VERSION ""
BS_:
BU_:

BO_ 881 RCM_dtcMatrix: 8 ETH
 SG_ RCM_dtcIndex M: 0|8@1+ (1,0) [0|0] "" X
 SG_ RCM_d000_comFault1 m0: 8|2@1+ (1,0) [0|0] "" X
 SG_ RCM_d001_vBatRange m0: 10|2@1+ (1,0) [0|0] "" X
 SG_ RCM_d002_vinMismatch m0: 12|2@1+ (1,0) [0|0] "" X
 SG_ RCM_d003_swVersionMismatch m0: 14|2@1+ (1,0) [0|0] "" X
 SG_ RCM_d004_idleMode m0: 16|2@1+ (1,0) [0|0] "" X
 SG_ RCM_d005_internalHard m0: 18|2@1+ (1,0) [0|0] "" X
 SG_ RCM_d006_crashAlgoDisabled m0: 20|2@1+ (1,0) [0|0] "" X
 SG_ RCM_d007_eolProgMismatch m0: 22|2@1+ (1,0) [0|0] "" X
 SG_ RCM_d008_crcErrorExternal m0: 24|2@1+ (1,0) [0|0] "" X
 SG_ RCM_d009_cfgFault m0: 26|2@1+ (1,0) [0|0] "" X
 SG_ RCM_d010_crashCalPNMissing m0: 28|2@1+ (1,0) [0|0] "" X
 SG_ RCM_d011_vdsFieldCalibFailed m0: 30|2@1+ (1,0) [0|0] "" X
 SG_ RCM_d012_vdsChannelSigMonTmp m0: 32|2@1+ (1,0) [0|0] "" X
 SG_ RCM_d013_vdsFieldCalibNotDone m0: 34|2@1+ (1,0) [0|0] "" X
 SG_ RCM_d014_vdsChannelSigMonPerm m0: 36|2@1+ (1,0) [0|0] "" X
 SG_ RCM_d015_vdsSensorMonitorTemp m0: 38|2@1+ (1,0) [0|0] "" X
 SG_ RCM_d016_comCANInitFailure m0: 40|2@1+ (1,0) [0|0] "" X
 SG_ RCM_d017_comGTWCarConfig m0: 42|2@1+ (1,0) [0|0] "" X
 SG_ RCM_d018_vinEmptyError m0: 44|2@1+ (1,0) [0|0] "" X
 SG_ RCM_d019_comESPC m0: 46|2@1+ (1,0) [0|0] "" X
 SG_ RCM_d020_comESP135 m0: 48|2@1+ (1,0) [0|0] "" X
 SG_ RCM_d021_comEPBStatus m0: 50|2@1+ (1,0) [0|0] "" X
 SG_ RCM_d022_comBCS2RStatus m0: 52|2@1+ (1,0) [0|0] "" X
 SG_ RCM_d023_comBCS2LStatus m0: 54|2@1+ (1,0) [0|0] "" X
 SG_ RCM_d024_comBCS2CStatus m0: 56|2@1+ (1,0) [0|0] "" X
 SG_ RCM_d025_comTPMSStatus m0: 58|2@1+ (1,0) [0|0] "" X
 SG_ RCM_d026_airbagWarnMismatch m0: 60|2@1+ (1,0) [0|0] "" X
 SG_ RCM_d027_ocsFailure m0: 62|2@1+ (1,0) [0|0] "" X
 SG_ RCM_d028_comGTWACS m1: 8|2@1+ (1,0) [0|0] "" X
 SG_ RCM_d029_comChassisBusOff m1: 10|2@1+ (1,0) [0|0] "" X
 SG_ RCM_d030_comStwAngle m1: 12|2@1+ (1,0) [0|0] "" X
 SG_ RCM_d031_comESP145 m1: 14|2@1+ (1,0) [0|0] "" X
 SG_ RCM_d032_comDITorque2 m1: 16|2@1+ (1,0) [0|0] "" X
 SG_ RCM_d033_comDITorque1 m1: 18|2@1+ (1,0) [0|0] "" X
 SG_ RCM_d034_comESPB m1: 20|2@1+ (1,0) [0|0] "" X
 SG_ RCM_d035_comGTWOdo m1: 22|2@1+ (1,0) [0|0] "" X
 SG_ RCM_d036_comBusOff m1: 24|2@1+ (1,0) [0|0] "" X
 SG_ RCM_d037_comMissingVehConfg m1: 26|2@1+ (1,0) [0|0] "" X
 SG_ RCM_d038_seatBackSw2ndRowLeft m1: 28|2@1+ (1,0) [0|0] "" X
 SG_ RCM_d039_pretenLapFrontRight m1: 30|2@1+ (1,0) [0|0] "" X
 SG_ RCM_d040_pretenLapFrontLeft m1: 32|2@1+ (1,0) [0|0] "" X
 SG_ RCM_d041_pretenShldFrontRight m1: 34|2@1+ (1,0) [0|0] "" X
 SG_ RCM_d042_pretenShldrFrontLeft m1: 36|2@1+ (1,0) [0|0] "" X
 SG_ RCM_d043_passABLampOnHardWire m1: 38|2@1+ (1,0) [0|0] "" X
 SG_ RCM_d044_crashDetected m1: 40|2@1+ (1,0) [0|0] "" X
 SG_ RCM_d045_crashOutSignal m1: 42|2@1+ (1,0) [0|0] "" X
 SG_ RCM_d046_passengerActiveVent m1: 44|2@1+ (1,0) [0|0] "" X
 SG_ RCM_d047_kneeABFrontPassenger m1: 46|2@1+ (1,0) [0|0] "" X
 SG_ RCM_d048_pressureFrontRtDoor m1: 48|2@1+ (1,0) [0|0] "" X
 SG_ RCM_d049_pressureFrontLftDoor m1: 50|2@1+ (1,0) [0|0] "" X
 SG_ RCM_d050_eepromDataLocked m1: 52|2@1+ (1,0) [0|0] "" X
 SG_ RCM_d051_hoodActuatorLeft m1: 54|2@1+ (1,0) [0|0] "" X
 SG_ RCM_d052_pretenMid2ndRow m1: 56|2@1+ (1,0) [0|0] "" X
 SG_ RCM_d053_sbsw2ndRowRight m1: 58|2@1+ (1,0) [0|0] "" X
 SG_ RCM_d054_padLampHardWire m1: 60|2@1+ (1,0) [0|0] "" X
 SG_ RCM_d055_passResOccupancySw m1: 62|2@1+ (1,0) [0|0] "" X
 SG_ RCM_d056_stpsDriver m2: 8|2@1+ (1,0) [0|0] "" X
 SG_ RCM_d057_pasDPillarLeftYAxis m2: 10|2@1+ (1,0) [0|0] "" X
 SG_ RCM_d058_pasDPillarLeftXAxis m2: 12|2@1+ (1,0) [0|0] "" X
 SG_ RCM_d059_pasDPillarRight m2: 14|2@1+ (1,0) [0|0] "" X
 SG_ RCM_d060_pasCPillarRight m2: 16|2@1+ (1,0) [0|0] "" X
 SG_ RCM_d061_pasBPillarRight m2: 18|2@1+ (1,0) [0|0] "" X
 SG_ RCM_d062_ufsRightSide m2: 20|2@1+ (1,0) [0|0] "" X
 SG_ RCM_d063_pasCPillarLeft m2: 22|2@1+ (1,0) [0|0] "" X
 SG_ RCM_d064_pasBPillarLeft m2: 24|2@1+ (1,0) [0|0] "" X
 SG_ RCM_d065_ufsLeftSide m2: 26|2@1+ (1,0) [0|0] "" X
 SG_ RCM_d066_loadLimiterRightSide m2: 28|2@1+ (1,0) [0|0] "" X
 SG_ RCM_d067_loadLimiterLeftSide m2: 30|2@1+ (1,0) [0|0] "" X
 SG_ RCM_d068_curAB3rdRowRight m2: 32|2@1+ (1,0) [0|0] "" X
 SG_ RCM_d069_curAB2ndRowRight m2: 34|2@1+ (1,0) [0|0] "" X
 SG_ RCM_d070_curAB2ndRowLeft m2: 36|2@1+ (1,0) [0|0] "" X
 SG_ RCM_d071_preten2ndRowRight m2: 38|2@1+ (1,0) [0|0] "" X
 SG_ RCM_d072_curAB3rdRowLeft m2: 40|2@1+ (1,0) [0|0] "" X
 SG_ RCM_d073_preten2ndRowLeft m2: 42|2@1+ (1,0) [0|0] "" X
 SG_ RCM_d074_siAB2ndRowRight m2: 44|2@1+ (1,0) [0|0] "" X
 SG_ RCM_d075_siAB2ndRowLeft m2: 46|2@1+ (1,0) [0|0] "" X
 SG_ RCM_d076_hardwarCodingPin3 m2: 48|2@1+ (1,0) [0|0] "" X
 SG_ RCM_d077_hardwareCodingPin2 m2: 50|2@1+ (1,0) [0|0] "" X
 SG_ RCM_d078_hardwareCodingPin1 m2: 52|2@1+ (1,0) [0|0] "" X
 SG_ RCM_d079_buckleRightSide m2: 54|2@1+ (1,0) [0|0] "" X
 SG_ RCM_d080_buckleLeftSide m2: 56|2@1+ (1,0) [0|0] "" X
 SG_ RCM_d081_curAB1stRowRight m2: 58|2@1+ (1,0) [0|0] "" X
 SG_ RCM_d082_siAB1stRowRight m2: 60|2@1+ (1,0) [0|0] "" X
 SG_ RCM_d083_curAB1stRowLeft m2: 62|2@1+ (1,0) [0|0] "" X
 SG_ RCM_d084_siAB1stRowLeft m3: 8|2@1+ (1,0) [0|0] "" X
 SG_ RCM_d085_pabStage2 m3: 10|2@1+ (1,0) [0|0] "" X
 SG_ RCM_d086_pabStage1 m3: 12|2@1+ (1,0) [0|0] "" X
 SG_ RCM_d087_hvDisconnect m3: 14|2@1+ (1,0) [0|0] "" X
 SG_ RCM_d088_kneeABDriver m3: 16|2@1+ (1,0) [0|0] "" X
 SG_ RCM_d089_dabStage2 m3: 18|2@1+ (1,0) [0|0] "" X
 SG_ RCM_d090_dabStage1 m3: 20|2@1+ (1,0) [0|0] "" X
 SG_ RCM_d091_comGTWCarState m3: 22|2@1+ (1,0) [0|0] "" X
 SG_ RCM_d092_driverOrientation m3: 24|2@1+ (1,0) [0|0] "" X
 SG_ RCM_d093_scmUnavailable m3: 26|2@1+ (1,0) [0|0] "" X
 SG_ RCM_d094_comDasControl m3: 28|2@1+ (1,0) [0|0] "" X
 SG_ RCM_d095_comDasIDF m3: 30|2@1+ (1,0) [0|0] "" X
 SG_ RCM_d096_comDasStatus m3: 32|2@1+ (1,0) [0|0] "" X
 SG_ RCM_d097_comDIState m3: 34|2@1+ (1,0) [0|0] "" X
 SG_ RCM_d098_comDIState2 m3: 36|2@1+ (1,0) [0|0] "" X

BO_ 849 RCM_info: 8 ETH
 SG_ RCM_infoIndex M: 0|8@1+ (1,0) [0|0] "" X
 SG_ RCM_infoBuildType m10: 8|8@1+ (1,0) [0|0] "" X
 SG_ RCM_infoComponentID m10: 48|16@1+ (1,0) [0|0] "" X
 SG_ RCM_infoPcbaID m11: 16|8@1+ (1,0) [0|0] "" X
 SG_ RCM_infoAssemblyID m11: 24|8@1+ (1,0) [0|0] "" X
 SG_ RCM_infoUsageID m11: 32|16@1+ (1,0) [0|0] "" X
 SG_ RCM_infoBootUdsProtoVersion m20: 8|8@1+ (1,0) [0|0] "" X
 SG_ RCM_infoBootloaderCRC m20: 32|32@1+ (1,0) [0|0] "" X
 SG_ RCM_infoApplicationCRC m13: 32|32@1+ (1,0) [0|0] "" X
 SG_ RCM_infoVariantCRC m22: 32|32@1+ (1,0) [0|0] "" X

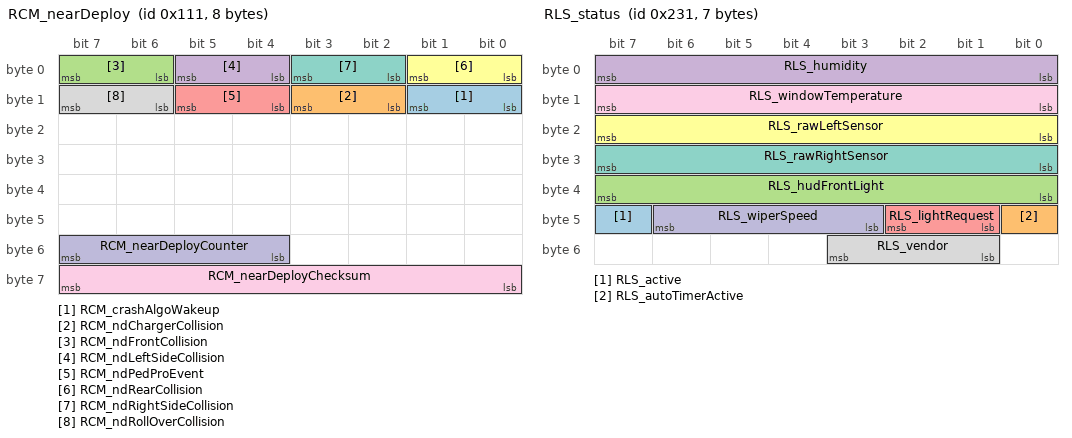
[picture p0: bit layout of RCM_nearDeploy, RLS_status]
BO_ 273 RCM_nearDeploy: 8 ETH
 SG_ RCM_crashAlgoWakeup: 8|2@1+ (1,0) [0|0] "" X
 SG_ RCM_ndChargerCollision: 10|2@1+ (1,0) [0|0] "" X
 SG_ RCM_ndFrontCollision: 6|2@1+ (1,0) [0|0] "" X
 SG_ RCM_ndLeftSideCollision: 4|2@1+ (1,0) [0|0] "" X
 SG_ RCM_ndPedProEvent: 12|2@1+ (1,0) [0|0] "" X
 SG_ RCM_ndRearCollision: 0|2@1+ (1,0) [0|0] "" X
 SG_ RCM_ndRightSideCollision: 2|2@1+ (1,0) [0|0] "" X
 SG_ RCM_ndRollOverCollision: 14|2@1+ (1,0) [0|0] "" X
 SG_ RCM_nearDeployChecksum: 56|8@1+ (1,0) [0|0] "" X
 SG_ RCM_nearDeployCounter: 52|4@1+ (1,0) [0|0] "" X

BO_ 535 RCM_status: 8 ETH
 SG_ RCM_airbagCutoffSwStatus: 34|2@1+ (1,0) [0|0] "" X
 SG_ RCM_armStatus: 4|2@1+ (1,0) [0|0] "" X
 SG_ RCM_buckle2ndRowStatus: 48|3@1+ (1,0) [0|0] "" X
 SG_ RCM_buckleDriverStatus: 14|2@1+ (1,0) [0|0] "" X
 SG_ RCM_bucklePassengerStatus: 10|2@1+ (1,0) [0|0] "" X
 SG_ RCM_chimeState1stRow: 22|2@1+ (1,0) [0|0] "" X
 SG_ RCM_driverOrientationInitStatus: 0|3@1+ (1,0) [0|0] "" X
 SG_ RCM_edr1State: 46|2@1+ (1,0) [0|0] "" X
 SG_ RCM_edr2State: 44|2@1+ (1,0) [0|0] "" X
 SG_ RCM_hwConfigPin56: 30|2@1+ (1,0) [0|0] "" X
 SG_ RCM_hwConfigPin57: 28|2@1+ (1,0) [0|0] "" X
 SG_ RCM_hwConfigPin58: 26|2@1+ (1,0) [0|0] "" X
 SG_ RCM_passAirbagRequest: 20|2@1+ (1,0) [0|0] "" X
 SG_ RCM_passOccupantStatus: 32|2@1+ (1,0) [0|0] "" X
 SG_ RCM_privateCANStatus: 36|2@1+ (1,0) [0|0] "" X
 SG_ RCM_publicCANStatus: 38|2@1+ (1,0) [0|0] "" X
 SG_ RCM_seatTrackPositionDrvr: 18|2@1+ (1,0) [0|0] "" X
 SG_ RCM_statusChecksum: 56|8@1+ (1,0) [0|0] "" X
 SG_ RCM_statusCounter: 52|4@1+ (1,0) [0|0] "" X
 SG_ RCM_tellTaleDriverState: 12|2@1+ (1,0) [0|0] "" X
 SG_ RCM_tellTalePassengerState: 8|2@1+ (1,0) [0|0] "" X
 SG_ RCM_vinLearnFlag: 24|2@1+ (1,0) [0|0] "" X
 SG_ RCM_warningIndicatorState: 6|2@1+ (1,0) [0|0] "" X

BO_ 1618 RCM_udsResponse: 8 ETH
 SG_ RCM_udsResponseData: 0|54@0+ (1024,0) [0|0] "" X

BO_ 561 RLS_status: 7 ETH
 SG_ RLS_active: 47|1@1+ (1,0) [0|0] "" X
 SG_ RLS_autoTimerActive: 40|1@1+ (1,0) [0|0] "" X
 SG_ RLS_hudFrontLight: 32|8@1+ (1,0) [0|0] "INTEGRAL" X
 SG_ RLS_humidity: 0|8@1+ (0.5,0) [0|0] "%" X
 SG_ RLS_lightRequest: 41|2@1+ (1,0) [0|0] "" X
 SG_ RLS_rawLeftSensor: 16|8@1+ (4.01575,0) [0|0] "W/m2" X
 SG_ RLS_rawRightSensor: 24|8@1+ (4.01575,0) [0|0] "W/m2" X
 SG_ RLS_vendor: 49|3@1+ (1,0) [0|0] "" X
 SG_ RLS_windowTemperature: 8|8@1+ (0.5,-40) [0|0] "C" X
 SG_ RLS_wiperSpeed: 43|4@1+ (1,0) [0|0] "" X

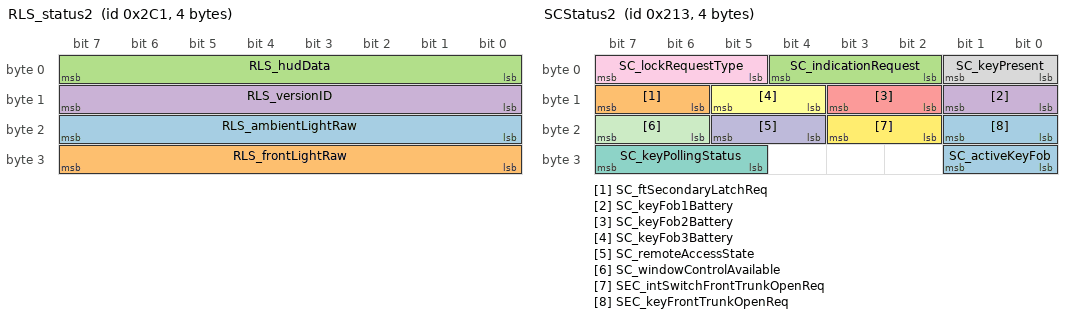
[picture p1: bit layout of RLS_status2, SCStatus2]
BO_ 705 RLS_status2: 4 ETH
 SG_ RLS_ambientLightRaw: 16|8@1+ (100,0) [0|0] "INTEGRAL" X
 SG_ RLS_frontLightRaw: 24|8@1+ (1,0) [0|0] "" X
 SG_ RLS_hudData: 0|8@1+ (1,0) [0|0] "INTEGRAL" X
 SG_ RLS_versionID: 8|8@1+ (1,0) [0|0] "INTEGRAL" X

BO_ 1944 SCCM_udsResponse: 8 ETH
 SG_ SCCM_udsResponseData: 0|54@0+ (1024,0) [0|0] "" X

BO_ 515 SCStatus: 8 ETH
 SG_ SC_alarmStatus: 0|4@1+ (1,0) [0|0] "" X
 SG_ SC_driverFrontDoorOpenStatus: 36|2@1+ (1,0) [0|0] "" X
 SG_ SC_driverRearDoorOpenStatus: 38|2@1+ (1,0) [0|0] "" X
 SG_ SC_frontTrunkStatus: 16|2@1+ (1,0) [0|0] "" X
 SG_ SC_hazardSwitchStatus: 14|2@1+ (1,0) [0|0] "" X
 SG_ SC_ignitionStatus: 52|4@1+ (1,0) [0|0] "" X
 SG_ SC_keyChallengeType: 22|2@1+ (1,0) [0|0] "" X
 SG_ SC_keyFobAuthenticated: 30|2@1+ (1,0) [0|0] "" X
 SG_ SC_passFrontDoorOpenStatus: 32|2@1+ (1,0) [0|0] "" X
 SG_ SC_passRearDoorOpenStatus: 34|2@1+ (1,0) [0|0] "" X
 SG_ SC_rearTrunkStatus: 18|2@1+ (1,0) [0|0] "" X
 SG_ SC_rkeUnlockRequiredForStart: 21|1@1+ (1,0) [0|0] "" X
 SG_ SC_scClusterMessage: 48|10@0+ (1,0) [0|0] "" X
 SG_ SC_scStatus: 4|4@1+ (1,0) [0|0] "" X
 SG_ SC_vehicleLockStatus: 8|3@1+ (1,0) [0|0] "" X
 SG_ SC_vehicleStatus: 11|3@1+ (1,0) [0|0] "" X
 SG_ SEC_accessViaDeadFob: 46|2@1+ (1,0) [0|0] "" X
 SG_ SEC_chargePortRequest: 44|2@1+ (1,0) [0|0] "" X
 SG_ SEC_driverPresent: 50|2@1+ (1,0) [0|0] "" X
 SG_ SEC_dtcPresent: 40|1@1+ (1,0) [0|0] "" X
 SG_ SEC_keyLocation: 24|4@1+ (1,0) [0|0] "" X
 SG_ SEC_keyPollSuccess: 28|2@1+ (1,0) [0|0] "" X
 SG_ SEC_lockRejected: 20|1@1+ (1,0) [0|0] "" X
 SG_ SEC_windowRequest: 42|2@1+ (1,0) [0|0] "" X

BO_ 531 SCStatus2: 4 ETH
 SG_ SC_activeKeyFob: 24|2@1+ (1,0) [0|0] "" X
 SG_ SC_ftSecondaryLatchReq: 14|2@1+ (1,0) [0|0] "" X
 SG_ SC_indicationRequest: 2|3@1+ (1,0) [0|0] "" X
 SG_ SC_keyFob1Battery: 8|2@1+ (1,0) [0|0] "" X
 SG_ SC_keyFob2Battery: 10|2@1+ (1,0) [0|0] "" X
 SG_ SC_keyFob3Battery: 12|2@1+ (1,0) [0|0] "" X
 SG_ SC_keyPollingStatus: 29|3@1+ (1,0) [0|0] "" X
 SG_ SC_keyPresent: 0|2@1+ (1,0) [0|0] "" X
 SG_ SC_lockRequestType: 5|3@1+ (1,0) [0|0] "" X
 SG_ SC_remoteAccessState: 20|2@1+ (1,0) [0|0] "" X
 SG_ SC_windowControlAvailable: 22|2@1+ (1,0) [0|0] "" X
 SG_ SEC_intSwitchFrontTrunkOpenReq: 18|2@1+ (1,0) [0|0] "" X
 SG_ SEC_keyFrontTrunkOpenReq: 16|2@1+ (1,0) [0|0] "" X

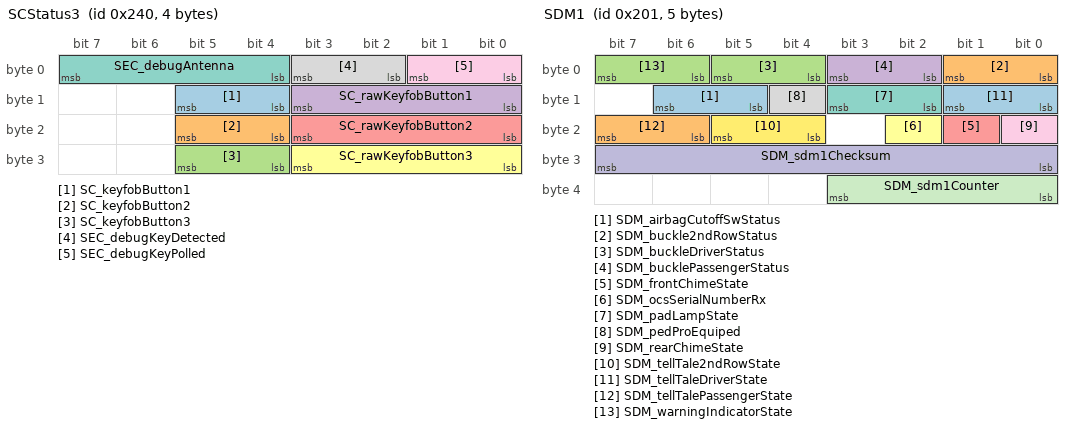
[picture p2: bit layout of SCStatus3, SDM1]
BO_ 576 SCStatus3: 4 ETH
 SG_ SC_keyfobButton1: 12|2@1+ (1,0) [0|0] "" X
 SG_ SC_keyfobButton2: 20|2@1+ (1,0) [0|0] "" X
 SG_ SC_keyfobButton3: 28|2@1+ (1,0) [0|0] "" X
 SG_ SC_rawKeyfobButton1: 8|4@1+ (1,0) [0|0] "" X
 SG_ SC_rawKeyfobButton2: 16|4@1+ (1,0) [0|0] "" X
 SG_ SC_rawKeyfobButton3: 24|4@1+ (1,0) [0|0] "" X
 SG_ SEC_debugAntenna: 4|4@1+ (1,0) [0|0] "" X
 SG_ SEC_debugKeyDetected: 2|2@1+ (1,0) [0|0] "" X
 SG_ SEC_debugKeyPolled: 0|2@1+ (1,0) [0|0] "" X

BO_ 513 SDM1: 5 ETH
 SG_ SDM_airbagCutoffSwStatus: 13|2@1+ (1,0) [0|0] "" X
 SG_ SDM_buckle2ndRowStatus: 0|2@1+ (1,0) [0|0] "" X
 SG_ SDM_buckleDriverStatus: 4|2@1+ (1,0) [0|0] "" X
 SG_ SDM_bucklePassengerStatus: 2|2@1+ (1,0) [0|0] "" X
 SG_ SDM_frontChimeState: 17|1@1+ (1,0) [0|0] "" X
 SG_ SDM_ocsSerialNumberRx: 18|1@1+ (1,0) [0|0] "" X
 SG_ SDM_padLampState: 10|2@1+ (1,0) [0|0] "" X
 SG_ SDM_pedProEquiped: 12|1@1+ (1,0) [0|0] "" X
 SG_ SDM_rearChimeState: 16|1@1+ (1,0) [0|0] "" X
 SG_ SDM_sdm1Checksum: 24|8@1+ (1,0) [0|0] "" X
 SG_ SDM_sdm1Counter: 32|4@1+ (1,0) [0|0] "" X
 SG_ SDM_tellTale2ndRowState: 20|2@1+ (1,0) [0|0] "" X
 SG_ SDM_tellTaleDriverState: 8|2@1+ (1,0) [0|0] "" X
 SG_ SDM_tellTalePassengerState: 22|2@1+ (1,0) [0|0] "" X
 SG_ SDM_warningIndicatorState: 6|2@1+ (1,0) [0|0] "" X

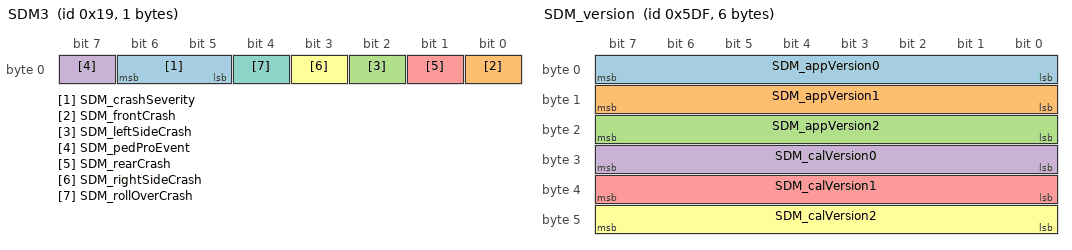
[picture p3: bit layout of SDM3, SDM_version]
BO_ 25 SDM3: 1 ETH
 SG_ SDM_crashSeverity: 5|2@1+ (1,0) [0|0] "" X
 SG_ SDM_frontCrash: 0|1@1+ (1,0) [0|0] "" X
 SG_ SDM_leftSideCrash: 2|1@1+ (1,0) [0|0] "" X
 SG_ SDM_pedProEvent: 7|1@1+ (1,0) [0|0] "" X
 SG_ SDM_rearCrash: 1|1@1+ (1,0) [0|0] "" X
 SG_ SDM_rightSideCrash: 3|1@1+ (1,0) [0|0] "" X
 SG_ SDM_rollOverCrash: 4|1@1+ (1,0) [0|0] "" X

BO_ 1617 SDM_udsResponse: 8 ETH
 SG_ SDM_udsResponseData: 0|54@0+ (1024,0) [0|0] "" X

BO_ 1503 SDM_version: 6 ETH
 SG_ SDM_appVersion0: 0|8@1+ (1,0) [0|0] "" X
 SG_ SDM_appVersion1: 8|8@1+ (1,0) [0|0] "" X
 SG_ SDM_appVersion2: 16|8@1+ (1,0) [0|0] "" X
 SG_ SDM_calVersion0: 24|8@1+ (1,0) [0|0] "" X
 SG_ SDM_calVersion1: 32|8@1+ (1,0) [0|0] "" X
 SG_ SDM_calVersion2: 40|8@1+ (1,0) [0|0] "" X

BO_ 547 SEC_doorCommandPartial: 1 ETH
 SG_ SC_handleFLCommand: 6|2@1+ (1,0) [0|0] "" X

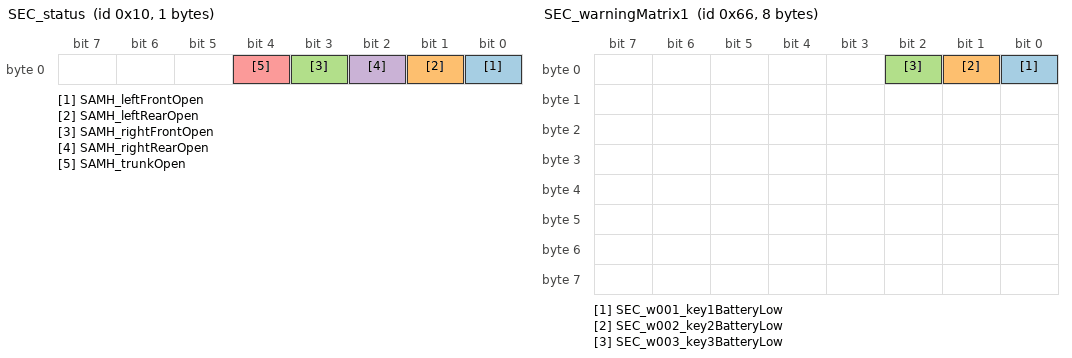
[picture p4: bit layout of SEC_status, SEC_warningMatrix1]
BO_ 16 SEC_status: 1 ETH
 SG_ SAMH_leftFrontOpen: 0|1@1+ (1,0) [0|0] "" X
 SG_ SAMH_leftRearOpen: 1|1@1+ (1,0) [0|0] "" X
 SG_ SAMH_rightFrontOpen: 3|1@1+ (1,0) [0|0] "" X
 SG_ SAMH_rightRearOpen: 2|1@1+ (1,0) [0|0] "" X
 SG_ SAMH_trunkOpen: 4|1@1+ (1,0) [0|0] "" X

BO_ 1683 SEC_udsResponse: 8 ETH
 SG_ SEC_udsResponseData: 0|54@0+ (1024,0) [0|0] "" X

BO_ 1315 SEC_version: 8 ETH
 SG_ SEC_componentBranchOrigin: 40|8@1+ (1,0) [0|0] "" X
 SG_ SEC_componentHardwareRevision: 56|8@1+ (1,0) [0|0] "" X
 SG_ SEC_componentMajorVersion: 32|8@1+ (1,0) [0|0] "" X
 SG_ SEC_componentMaturity: 48|8@1+ (1,0) [0|0] "" X
 SG_ SEC_componentSvn: 8|24@0+ (1,0) [0|0] "" X
 SG_ SEC_platformType: 0|8@1+ (1,0) [0|0] "" X

BO_ 102 SEC_warningMatrix1: 8 ETH
 SG_ SEC_w001_key1BatteryLow: 0|1@1+ (1,0) [0|0] "" X
 SG_ SEC_w002_key2BatteryLow: 1|1@1+ (1,0) [0|0] "" X
 SG_ SEC_w003_key3BatteryLow: 2|1@1+ (1,0) [0|0] "" X

BO_ 1317 SNSCLL1_info: 8 ETH
 SG_ SNSCLL1_infoIndex M: 0|8@1+ (1,0) [0|0] "" X
 SG_ SNSCLL1_infoBuildType m10: 8|8@1+ (1,0) [0|0] "" X
 SG_ SNSCLL1_infoBuildConfigID m10: 16|16@1+ (1,0) [0|0] "" X
 SG_ SNSCLL1_infoHardwareID m10: 32|16@1+ (1,0) [0|0] "" X
 SG_ SNSCLL1_infoComponentID m10: 48|16@1+ (1,0) [0|0] "" X
 SG_ SNSCLL1_infoPcbaID m11: 16|8@1+ (1,0) [0|0] "" X
 SG_ SNSCLL1_infoAssemblyID m11: 24|8@1+ (1,0) [0|0] "INTEGRAL" X
 SG_ SNSCLL1_infoUsageID m11: 32|16@1+ (1,0) [0|0] "" X
 SG_ SNSCLL1_infoSubUsageID m11: 48|16@1+ (1,0) [0|0] "" X
 SG_ SNSCLL1_infoApplicationCRC m13: 32|32@1+ (1,0) [0|0] "" X
 SG_ SNSCLL1_infoBootSvnRev m14: 8|24@1+ (1,0) [0|0] "" X
 SG_ SNSCLL1_infoAppGitHashBytes m17: 10|54@1+ (4,0) [0|0] "" X
 SG_ SNSCLL1_infoBootGitHashBytes m18: 10|54@1+ (4,0) [0|0] "" X
 SG_ SNSCLL1_infoPlatformType m19: 8|8@1+ (1,0) [0|0] "" X
 SG_ SNSCLL1_infoBootUdsProtoVersion m20: 8|8@1+ (1,0) [0|0] "" X
 SG_ SNSCLL1_infoBootloaderCRC m20: 32|32@1+ (1,0) [0|0] "" X

BO_ 1784 SNSCLL1_udsResponse: 8 ETH
 SG_ SNSCLL1_udsResponseData: 0|54@0+ (1024,0) [0|0] "" X

BO_ 1318 SNSCLR1_info: 8 ETH
 SG_ SNSCLR1_infoIndex M: 0|8@1+ (1,0) [0|0] "" X
 SG_ SNSCLR1_infoBuildType m10: 8|8@1+ (1,0) [0|0] "" X
 SG_ SNSCLR1_infoBuildConfigID m10: 16|16@1+ (1,0) [0|0] "" X
 SG_ SNSCLR1_infoHardwareID m10: 32|16@1+ (1,0) [0|0] "" X
 SG_ SNSCLR1_infoComponentID m10: 48|16@1+ (1,0) [0|0] "" X
 SG_ SNSCLR1_infoPcbaID m11: 16|8@1+ (1,0) [0|0] "" X
 SG_ SNSCLR1_infoAssemblyID m11: 24|8@1+ (1,0) [0|0] "INTEGRAL" X
 SG_ SNSCLR1_infoUsageID m11: 32|16@1+ (1,0) [0|0] "" X
 SG_ SNSCLR1_infoSubUsageID m11: 48|16@1+ (1,0) [0|0] "" X
 SG_ SNSCLR1_infoApplicationCRC m13: 32|32@1+ (1,0) [0|0] "" X
 SG_ SNSCLR1_infoBootSvnRev m14: 8|24@1+ (1,0) [0|0] "" X
 SG_ SNSCLR1_infoAppGitHashBytes m17: 10|54@1+ (4,0) [0|0] "" X
 SG_ SNSCLR1_infoBootGitHashBytes m18: 10|54@1+ (4,0) [0|0] "" X
 SG_ SNSCLR1_infoPlatformType m19: 8|8@1+ (1,0) [0|0] "" X
 SG_ SNSCLR1_infoBootUdsProtoVersion m20: 8|8@1+ (1,0) [0|0] "" X
 SG_ SNSCLR1_infoBootloaderCRC m20: 32|32@1+ (1,0) [0|0] "" X

BO_ 1785 SNSCLR1_udsResponse: 8 ETH
 SG_ SNSCLR1_udsResponseData: 0|54@0+ (1024,0) [0|0] "" X

BO_ 1319 SNSCUL1_info: 8 ETH
 SG_ SNSCUL1_infoIndex M: 0|8@1+ (1,0) [0|0] "" X
 SG_ SNSCUL1_infoBuildType m10: 8|8@1+ (1,0) [0|0] "" X
 SG_ SNSCUL1_infoBuildConfigID m10: 16|16@1+ (1,0) [0|0] "" X
 SG_ SNSCUL1_infoHardwareID m10: 32|16@1+ (1,0) [0|0] "" X
 SG_ SNSCUL1_infoComponentID m10: 48|16@1+ (1,0) [0|0] "" X
 SG_ SNSCUL1_infoPcbaID m11: 16|8@1+ (1,0) [0|0] "" X
 SG_ SNSCUL1_infoAssemblyID m11: 24|8@1+ (1,0) [0|0] "INTEGRAL" X
 SG_ SNSCUL1_infoUsageID m11: 32|16@1+ (1,0) [0|0] "" X
 SG_ SNSCUL1_infoSubUsageID m11: 48|16@1+ (1,0) [0|0] "" X
 SG_ SNSCUL1_infoApplicationCRC m13: 32|32@1+ (1,0) [0|0] "" X
 SG_ SNSCUL1_infoBootSvnRev m14: 8|24@1+ (1,0) [0|0] "" X
 SG_ SNSCUL1_infoAppGitHashBytes m17: 10|54@1+ (4,0) [0|0] "" X
 SG_ SNSCUL1_infoBootGitHashBytes m18: 10|54@1+ (4,0) [0|0] "" X
 SG_ SNSCUL1_infoPlatformType m19: 8|8@1+ (1,0) [0|0] "" X
 SG_ SNSCUL1_infoBootUdsProtoVersion m20: 8|8@1+ (1,0) [0|0] "" X
 SG_ SNSCUL1_infoBootloaderCRC m20: 32|32@1+ (1,0) [0|0] "" X

BO_ 1786 SNSCUL1_udsResponse: 8 ETH
 SG_ SNSCUL1_udsResponseData: 0|54@0+ (1024,0) [0|0] "" X

BO_ 1320 SNSCUR1_info: 8 ETH
 SG_ SNSCUR1_infoIndex M: 0|8@1+ (1,0) [0|0] "" X
 SG_ SNSCUR1_infoBuildType m10: 8|8@1+ (1,0) [0|0] "" X
 SG_ SNSCUR1_infoBuildConfigID m10: 16|16@1+ (1,0) [0|0] "" X
 SG_ SNSCUR1_infoHardwareID m10: 32|16@1+ (1,0) [0|0] "" X
 SG_ SNSCUR1_infoComponentID m10: 48|16@1+ (1,0) [0|0] "" X
 SG_ SNSCUR1_infoPcbaID m11: 16|8@1+ (1,0) [0|0] "" X
 SG_ SNSCUR1_infoAssemblyID m11: 24|8@1+ (1,0) [0|0] "INTEGRAL" X
 SG_ SNSCUR1_infoUsageID m11: 32|16@1+ (1,0) [0|0] "" X
 SG_ SNSCUR1_infoSubUsageID m11: 48|16@1+ (1,0) [0|0] "" X
 SG_ SNSCUR1_infoApplicationCRC m13: 32|32@1+ (1,0) [0|0] "" X
 SG_ SNSCUR1_infoBootSvnRev m14: 8|24@1+ (1,0) [0|0] "" X
 SG_ SNSCUR1_infoAppGitHashBytes m17: 10|54@1+ (4,0) [0|0] "" X
 SG_ SNSCUR1_infoBootGitHashBytes m18: 10|54@1+ (4,0) [0|0] "" X
 SG_ SNSCUR1_infoPlatformType m19: 8|8@1+ (1,0) [0|0] "" X
 SG_ SNSCUR1_infoBootUdsProtoVersion m20: 8|8@1+ (1,0) [0|0] "" X
 SG_ SNSCUR1_infoBootloaderCRC m20: 32|32@1+ (1,0) [0|0] "" X

BO_ 1787 SNSCUR1_udsResponse: 8 ETH
 SG_ SNSCUR1_udsResponseData: 0|54@0+ (1024,0) [0|0] "" X

BO_ 685 STW_ACTN_RQ: 8 ETH
 SG_ CRC_STW_ACTN_RQ: 56|8@1+ (1,0) [0|0] "" X
 SG_ DTR_Dist_Rq: 8|8@1+ (1,0) [0|0] "" X
 SG_ HiBmLvr_Stat: 18|2@1+ (1,0) [0|0] "" X
 SG_ HrnSw_Psd: 30|2@1+ (1,0) [0|0] "" X
 SG_ MC_STW_ACTN_RQ: 52|4@1+ (1,0) [0|0] "" X
 SG_ SpdCtrlLvrStat_Inv: 7|1@1+ (1,0) [0|0] "" X
 SG_ SpdCtrlLvr_Stat: 0|6@1+ (1,0) [0|0] "" X
 SG_ StW_Cond_Flt: 27|1@1+ (1,0) [0|0] "" X
 SG_ StW_Cond_Psd: 28|2@1+ (1,0) [0|0] "" X
 SG_ StW_Lvr_Stat: 24|3@1+ (1,0) [0|0] "" X
 SG_ StW_Sw00_Psd: 32|1@1+ (1,0) [0|0] "" X
 SG_ StW_Sw01_Psd: 33|1@1+ (1,0) [0|0] "" X
 SG_ StW_Sw02_Psd: 34|1@1+ (1,0) [0|0] "" X
 SG_ StW_Sw03_Psd: 35|1@1+ (1,0) [0|0] "" X
 SG_ StW_Sw04_Psd: 36|1@1+ (1,0) [0|0] "" X
 SG_ StW_Sw05_Psd: 37|1@1+ (1,0) [0|0] "" X
 SG_ StW_Sw06_Psd: 38|1@1+ (1,0) [0|0] "" X
 SG_ StW_Sw07_Psd: 39|1@1+ (1,0) [0|0] "" X
 SG_ StW_Sw08_Psd: 40|1@1+ (1,0) [0|0] "" X
 SG_ StW_Sw09_Psd: 41|1@1+ (1,0) [0|0] "" X
 SG_ StW_Sw10_Psd: 42|1@1+ (1,0) [0|0] "" X
 SG_ StW_Sw11_Psd: 43|1@1+ (1,0) [0|0] "" X
 SG_ StW_Sw12_Psd: 44|1@1+ (1,0) [0|0] "" X
 SG_ StW_Sw13_Psd: 45|1@1+ (1,0) [0|0] "" X
 SG_ StW_Sw14_Psd: 46|1@1+ (1,0) [0|0] "" X
 SG_ StW_Sw15_Psd: 47|1@1+ (1,0) [0|0] "" X
 SG_ TurnIndLvr_Stat: 16|2@1+ (1,0) [0|0] "" X
 SG_ VSL_Enbl_Rq: 6|1@1+ (1,0) [0|0] "" X
 SG_ WprSw6Posn: 48|3@1+ (1,0) [0|0] "" X
 SG_ WprWashSw_Psd: 20|2@1+ (1,0) [0|0] "" X
 SG_ WprWash_R_Sw_Posn_V2: 22|2@1+ (1,0) [0|0] "" X

BO_ 138 STW_ANGLHP_STAT_partial: 8 ETH
 SG_ StW_AnglHP: 0|14@0+ (0.1,-819.2) [0|0] "deg" X
 SG_ StW_AnglHP_Spd: 16|14@0+ (0.5,-4096) [0|0] "deg/s" X

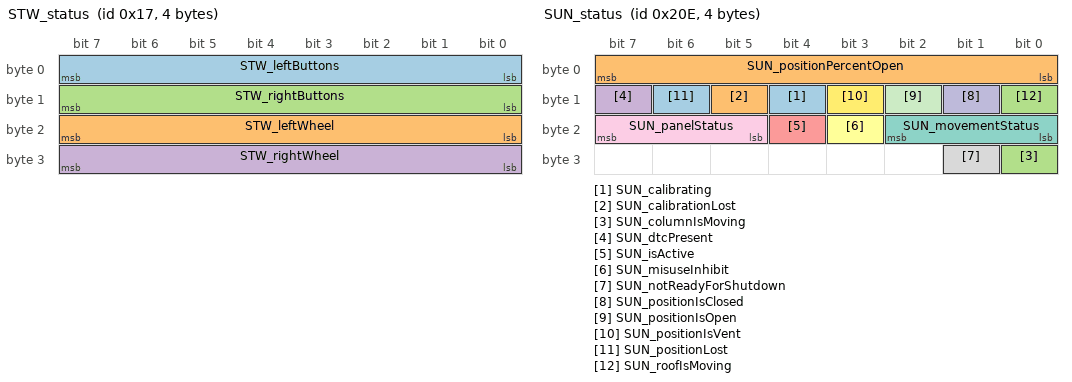
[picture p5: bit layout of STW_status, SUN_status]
BO_ 23 STW_status: 4 ETH
 SG_ STW_leftButtons: 0|8@1+ (1,0) [0|0] "" X
 SG_ STW_leftWheel: 16|8@1+ (1,0) [0|0] "" X
 SG_ STW_rightButtons: 8|8@1+ (1,0) [0|0] "" X
 SG_ STW_rightWheel: 24|8@1+ (1,0) [0|0] "" X

BO_ 526 SUN_status: 4 ETH
 SG_ SUN_calibrating: 12|1@1+ (1,0) [0|0] "" X
 SG_ SUN_calibrationLost: 13|1@1+ (1,0) [0|0] "" X
 SG_ SUN_columnIsMoving: 24|1@1+ (1,0) [0|0] "" X
 SG_ SUN_dtcPresent: 15|1@1+ (1,0) [0|0] "" X
 SG_ SUN_isActive: 20|1@1+ (1,0) [0|0] "" X
 SG_ SUN_misuseInhibit: 19|1@1+ (1,0) [0|0] "" X
 SG_ SUN_movementStatus: 16|3@1+ (1,0) [0|0] "" X
 SG_ SUN_notReadyForShutdown: 25|1@1+ (1,0) [0|0] "" X
 SG_ SUN_panelStatus: 21|3@1+ (1,0) [0|0] "" X
 SG_ SUN_positionIsClosed: 9|1@1+ (1,0) [0|0] "" X
 SG_ SUN_positionIsOpen: 10|1@1+ (1,0) [0|0] "" X
 SG_ SUN_positionIsVent: 11|1@1+ (1,0) [0|0] "" X
 SG_ SUN_positionLost: 14|1@1+ (1,0) [0|0] "" X
 SG_ SUN_positionPercentOpen: 0|8@1+ (0.5,0) [0|0] "%" X
 SG_ SUN_roofIsMoving: 8|1@1+ (1,0) [0|0] "" X

BO_ 1694 SUN_udsResponse: 8 ETH
 SG_ SUN_udsResponseData: 0|54@0+ (1024,0) [0|0] "" X

BO_ 1310 SUN_version: 8 ETH
 SG_ SUN_componentBranchOrigin: 40|8@1+ (1,0) [0|0] "" X
 SG_ SUN_componentHardwareRevision: 56|8@1+ (1,0) [0|0] "" X
 SG_ SUN_componentMajorVersion: 32|8@1+ (1,0) [0|0] "" X
 SG_ SUN_componentMaturity: 48|8@1+ (1,0) [0|0] "" X
 SG_ SUN_componentSvn: 8|24@0+ (1,0) [0|0] "" X
 SG_ SUN_platformType: 0|8@1+ (1,0) [0|0] "" X

BO_ 1292 TAS2_alertMatrix: 8 ETH
 SG_ TAS2_matrixIndex M: 0|4@1+ (1,0) [0|0] "" X
 SG_ TAS2_a001_WatchdogReset m0: 4|1@1+ (1,0) [0|0] "" X
 SG_ TAS2_a002_PowerLossReset m0: 5|1@1+ (1,0) [0|0] "" X
 SG_ TAS2_a003_SWAssertion m0: 6|1@1+ (1,0) [0|0] "" X
 SG_ TAS2_a012_CPUReset m0: 15|1@1+ (1,0) [0|0] "" X
 SG_ TAS2_a015_NVMMAlert m0: 18|1@1+ (1,0) [0|0] "" X
 SG_ TAS2_a021_TaskSchedulerError m0: 24|1@1+ (1,0) [0|0] "" X
 SG_ TAS2_a022_TaskInitError m0: 25|1@1+ (1,0) [0|0] "" X
 SG_ TAS2_a025_CrashEvent m0: 28|1@1+ (1,0) [0|0] "" X
 SG_ TAS2_a030_PWMerrorFL m0: 33|1@1+ (1,0) [0|0] "" X
 SG_ TAS2_a031_PWMerrorFR m0: 34|1@1+ (1,0) [0|0] "" X
 SG_ TAS2_a032_PWMerrorRL m0: 35|1@1+ (1,0) [0|0] "" X
 SG_ TAS2_a033_PWMerrorRR m0: 36|1@1+ (1,0) [0|0] "" X
 SG_ TAS2_a034_PWMshortFL m0: 37|1@1+ (1,0) [0|0] "" X
 SG_ TAS2_a035_PWMshortFR m0: 38|1@1+ (1,0) [0|0] "" X
 SG_ TAS2_a036_PWMshortRL m0: 39|1@1+ (1,0) [0|0] "" X
 SG_ TAS2_a037_PWMshortRR m0: 40|1@1+ (1,0) [0|0] "" X
 SG_ TAS2_a038_PWMopenFL m0: 41|1@1+ (1,0) [0|0] "" X
 SG_ TAS2_a039_PWMopenFR m0: 42|1@1+ (1,0) [0|0] "" X
 SG_ TAS2_a040_PWMopenRL m0: 43|1@1+ (1,0) [0|0] "" X
 SG_ TAS2_a041_PWMopenRR m0: 44|1@1+ (1,0) [0|0] "" X
 SG_ TAS2_a043_Task1msError m0: 46|1@1+ (1,0) [0|0] "" X
 SG_ TAS2_a044_Task10msError m0: 47|1@1+ (1,0) [0|0] "" X
 SG_ TAS2_a045_Task100msError m0: 48|1@1+ (1,0) [0|0] "" X
 SG_ TAS2_a046_Task1000msError m0: 49|1@1+ (1,0) [0|0] "" X
 SG_ TAS2_a059_inputResistanceHigh m0: 62|1@1+ (1,0) [0|0] "" X
 SG_ TAS2_a060_engineeringBuild m0: 63|1@1+ (1,0) [0|0] "" X
 SG_ TAS2_a061_XCPConnected m1: 4|1@1+ (1,0) [0|0] "" X
 SG_ TAS2_a062_XCPWasConnected m1: 5|1@1+ (1,0) [0|0] "" X
 SG_ TAS2_a070_underVoltage12V m1: 13|1@1+ (1,0) [0|0] "" X
 SG_ TAS2_a071_overVoltage12V m1: 14|1@1+ (1,0) [0|0] "" X
 SG_ TAS2_a072_shortCircuit5VOnBoard m1: 15|1@1+ (1,0) [0|0] "" X
 SG_ TAS2_a073_underVoltage5VOnBoard m1: 16|1@1+ (1,0) [0|0] "" X
 SG_ TAS2_a074_shortCircuit5VAnalog m1: 17|1@1+ (1,0) [0|0] "" X
 SG_ TAS2_a075_underVoltage5VAnalog m1: 18|1@1+ (1,0) [0|0] "" X
 SG_ TAS2_a076_overVoltage5VAnalog m1: 19|1@1+ (1,0) [0|0] "" X
 SG_ TAS2_a077_pressureSigVTooLow m1: 20|1@1+ (1,0) [0|0] "" X
 SG_ TAS2_a078_pressureSigVTooHigh m1: 21|1@1+ (1,0) [0|0] "" X
 SG_ TAS2_a079_DvrSideCfgMismatch m1: 22|1@1+ (1,0) [0|0] "" X
 SG_ TAS2_a080_shortCircuit5VHeight m1: 23|1@1+ (1,0) [0|0] "" X
 SG_ TAS2_a081_underVoltage5VHeight m1: 24|1@1+ (1,0) [0|0] "" X
 SG_ TAS2_a082_overVoltage5VHeight m1: 25|1@1+ (1,0) [0|0] "" X
 SG_ TAS2_a093_OTPError m1: 36|1@1+ (1,0) [0|0] "" X
 SG_ TAS2_a094_DAS_MIA m1: 37|1@1+ (1,0) [0|0] "" X
 SG_ TAS2_a095_DIS_MIA m1: 38|1@1+ (1,0) [0|0] "" X
 SG_ TAS2_a096_IMU_MIA m1: 39|1@1+ (1,0) [0|0] "" X
 SG_ TAS2_a097_RCM_MIA m1: 40|1@1+ (1,0) [0|0] "" X
 SG_ TAS2_a098_MCU_MIA m1: 41|1@1+ (1,0) [0|0] "" X
 SG_ TAS2_a099_EFUSE_MIA m1: 42|1@1+ (1,0) [0|0] "" X
 SG_ TAS2_a100_SCCM_MIA m1: 43|1@1+ (1,0) [0|0] "" X
 SG_ TAS2_a101_ESP_MIA m1: 44|1@1+ (1,0) [0|0] "" X
 SG_ TAS2_a102_DI_MIA m1: 45|1@1+ (1,0) [0|0] "" X
 SG_ TAS2_a103_GTW_MIA m1: 46|1@1+ (1,0) [0|0] "" X
 SG_ TAS2_a106_HighCPULoad m1: 49|1@1+ (1,0) [0|0] "" X
 SG_ TAS2_a107_HighStackUsage m1: 50|1@1+ (1,0) [0|0] "" X
 SG_ TAS2_a121_maxDutyFL m2: 4|1@1+ (1,0) [0|0] "" X
 SG_ TAS2_a122_maxDutyFR m2: 5|1@1+ (1,0) [0|0] "" X
 SG_ TAS2_a123_maxDutyRL m2: 6|1@1+ (1,0) [0|0] "" X
 SG_ TAS2_a124_maxDutyRR m2: 7|1@1+ (1,0) [0|0] "" X
 SG_ TAS2_a125_maxDutyReservoir m2: 8|1@1+ (1,0) [0|0] "" X
 SG_ TAS2_a126_maxDutyExhaust m2: 9|1@1+ (1,0) [0|0] "" X
 SG_ TAS2_a127_maxDutyBoost m2: 10|1@1+ (1,0) [0|0] "" X
 SG_ TAS2_a128_maxDutyCompressor m2: 11|1@1+ (1,0) [0|0] "" X
 SG_ TAS2_a129_openCircuitFL m2: 12|1@1+ (1,0) [0|0] "" X
 SG_ TAS2_a130_openCircuitFR m2: 13|1@1+ (1,0) [0|0] "" X
 SG_ TAS2_a131_openCircuitRL m2: 14|1@1+ (1,0) [0|0] "" X
 SG_ TAS2_a132_openCircuitRR m2: 15|1@1+ (1,0) [0|0] "" X
 SG_ TAS2_a133_openCircuitReservoir m2: 16|1@1+ (1,0) [0|0] "" X
 SG_ TAS2_a134_openCircuitExhaust m2: 17|1@1+ (1,0) [0|0] "" X
 SG_ TAS2_a135_openCircuitBoost m2: 18|1@1+ (1,0) [0|0] "" X
 SG_ TAS2_a136_openCircuitCompressor m2: 19|1@1+ (1,0) [0|0] "" X
 SG_ TAS2_a137_shortCircuitFL m2: 20|1@1+ (1,0) [0|0] "" X
 SG_ TAS2_a138_shortCircuitFR m2: 21|1@1+ (1,0) [0|0] "" X
 SG_ TAS2_a139_shortCircuitRL m2: 22|1@1+ (1,0) [0|0] "" X
 SG_ TAS2_a140_shortCircuitRR m2: 23|1@1+ (1,0) [0|0] "" X
 SG_ TAS2_a141_shortCircuitReservoir m2: 24|1@1+ (1,0) [0|0] "" X
 SG_ TAS2_a142_shortCircuitExhaust m2: 25|1@1+ (1,0) [0|0] "" X
 SG_ TAS2_a143_shortCircuitBoost m2: 26|1@1+ (1,0) [0|0] "" X
 SG_ TAS2_a144_shortCircuitCompressor m2: 27|1@1+ (1,0) [0|0] "" X
 SG_ TAS2_a145_boardFaultFL m2: 28|1@1+ (1,0) [0|0] "" X
 SG_ TAS2_a146_boardFaultFR m2: 29|1@1+ (1,0) [0|0] "" X
 SG_ TAS2_a147_boardFaultRL m2: 30|1@1+ (1,0) [0|0] "" X
 SG_ TAS2_a148_boardFaultRR m2: 31|1@1+ (1,0) [0|0] "" X
 SG_ TAS2_a149_boardFaultReservoir m2: 32|1@1+ (1,0) [0|0] "" X
 SG_ TAS2_a150_boardFaultExhaust m2: 33|1@1+ (1,0) [0|0] "" X
 SG_ TAS2_a151_boardFaultBoost m2: 34|1@1+ (1,0) [0|0] "" X
 SG_ TAS2_a152_boardFaultCompressor m2: 35|1@1+ (1,0) [0|0] "" X
 SG_ TAS2_a153_otherCircuitFL m2: 36|1@1+ (1,0) [0|0] "" X
 SG_ TAS2_a154_otherCircuitFR m2: 37|1@1+ (1,0) [0|0] "" X
 SG_ TAS2_a155_otherCircuitRL m2: 38|1@1+ (1,0) [0|0] "" X
 SG_ TAS2_a156_otherCircuitRR m2: 39|1@1+ (1,0) [0|0] "" X
 SG_ TAS2_a157_otherCircuitReservoir m2: 40|1@1+ (1,0) [0|0] "" X
 SG_ TAS2_a158_otherCircuitExhaust m2: 41|1@1+ (1,0) [0|0] "" X
 SG_ TAS2_a159_otherCircuitBoost m2: 42|1@1+ (1,0) [0|0] "" X
 SG_ TAS2_a160_otherCircuitCompressor m2: 43|1@1+ (1,0) [0|0] "" X
 SG_ TAS2_a161_valveBlockOpenGND m2: 44|1@1+ (1,0) [0|0] "" X
 SG_ TAS2_a162_compressorValveOpenGND m2: 45|1@1+ (1,0) [0|0] "" X
 SG_ TAS2_a163_reservoirFillDisabled m2: 46|1@1+ (1,0) [0|0] "" X
 SG_ TAS2_a165_damperValveCompFL m2: 48|1@1+ (1,0) [0|0] "" X
 SG_ TAS2_a166_damperValveRbndFL m2: 49|1@1+ (1,0) [0|0] "" X
 SG_ TAS2_a167_damperValveCompFR m2: 50|1@1+ (1,0) [0|0] "" X
 SG_ TAS2_a168_damperValveRbndFR m2: 51|1@1+ (1,0) [0|0] "" X
 SG_ TAS2_a169_damperValveCompRL m2: 52|1@1+ (1,0) [0|0] "" X
 SG_ TAS2_a170_damperValveRbndRL m2: 53|1@1+ (1,0) [0|0] "" X
 SG_ TAS2_a171_damperValveCompRR m2: 54|1@1+ (1,0) [0|0] "" X
 SG_ TAS2_a172_damperValveRbndRR m2: 55|1@1+ (1,0) [0|0] "" X
 SG_ TAS2_a200_jackModeActive m3: 23|1@1+ (1,0) [0|0] "" X
 SG_ TAS2_a201_lowHVBattery m3: 24|1@1+ (1,0) [0|0] "" X
 SG_ TAS2_a210_outOfRangeCalibration m3: 33|1@1+ (1,0) [0|0] "" X
 SG_ TAS2_a211_noRideHeightCalib m3: 34|1@1+ (1,0) [0|0] "" X
 SG_ TAS2_a213_yellowWarningLamp m3: 36|1@1+ (1,0) [0|0] "" X
 SG_ TAS2_a214_redWarningLamp m3: 37|1@1+ (1,0) [0|0] "" X
 SG_ TAS2_a215_limpHomeMode10 m3: 38|1@1+ (1,0) [0|0] "" X
 SG_ TAS2_a216_limpHomeMode20 m3: 39|1@1+ (1,0) [0|0] "" X
 SG_ TAS2_a217_limpHomeMode30 m3: 40|1@1+ (1,0) [0|0] "" X
 SG_ TAS2_a218_limpHomeMode40 m3: 41|1@1+ (1,0) [0|0] "" X
 SG_ TAS2_a220_exhaustGalleryFault m3: 43|1@1+ (1,0) [0|0] "" X
 SG_ TAS2_a221_valveLeakDetected m3: 44|1@1+ (1,0) [0|0] "" X
 SG_ TAS2_a222_compressorPrefillFault m3: 45|1@1+ (1,0) [0|0] "" X
 SG_ TAS2_a223_blockedAirline m3: 46|1@1+ (1,0) [0|0] "" X
 SG_ TAS2_a224_openAirline m3: 47|1@1+ (1,0) [0|0] "" X
 SG_ TAS2_a225_galleryPressureTooHigh m3: 48|1@1+ (1,0) [0|0] "" X
 SG_ TAS2_a226_PWMfastDetectFL m3: 49|1@1+ (1,0) [0|0] "" X
 SG_ TAS2_a227_PWMfastDetectFR m3: 50|1@1+ (1,0) [0|0] "" X
 SG_ TAS2_a228_PWMfastDetectRL m3: 51|1@1+ (1,0) [0|0] "" X
 SG_ TAS2_a229_PWMfastDetectRR m3: 52|1@1+ (1,0) [0|0] "" X
 SG_ TAS2_a290_twistSustainedAtSpeed m4: 53|1@1+ (1,0) [0|0] "" X
 SG_ TAS2_a291_frontAxleTooHigh m4: 54|1@1+ (1,0) [0|0] "" X
 SG_ TAS2_a292_rearAxleTooHigh m4: 55|1@1+ (1,0) [0|0] "" X
 SG_ TAS2_a293_frontAxleTooLow m4: 56|1@1+ (1,0) [0|0] "" X
 SG_ TAS2_a294_rearAxleTooLow m4: 57|1@1+ (1,0) [0|0] "" X
 SG_ TAS2_a295_targetHeightNotMet m4: 58|1@1+ (1,0) [0|0] "" X
 SG_ TAS2_a296_chassisTypeMismatch m4: 59|1@1+ (1,0) [0|0] "" X
 SG_ TAS2_a297_vinMismatch m4: 60|1@1+ (1,0) [0|0] "" X
 SG_ TAS2_a298_vinNotLearned m4: 61|1@1+ (1,0) [0|0] "" X

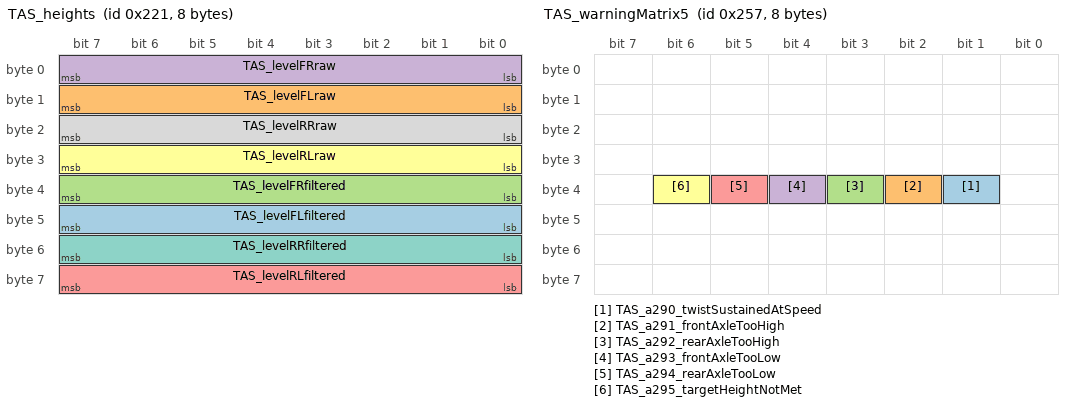
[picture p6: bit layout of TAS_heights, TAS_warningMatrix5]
BO_ 545 TAS_heights: 8 ETH
 SG_ TAS_levelFLfiltered: 40|8@1+ (1,-100) [0|0] "mm" X
 SG_ TAS_levelFLraw: 8|8@1+ (1,-100) [0|0] "mm" X
 SG_ TAS_levelFRfiltered: 32|8@1+ (1,-100) [0|0] "mm" X
 SG_ TAS_levelFRraw: 0|8@1+ (1,-100) [0|0] "mm" X
 SG_ TAS_levelRLfiltered: 56|8@1+ (1,-100) [0|0] "mm" X
 SG_ TAS_levelRLraw: 24|8@1+ (1,-100) [0|0] "mm" X
 SG_ TAS_levelRRfiltered: 48|8@1+ (1,-100) [0|0] "mm" X
 SG_ TAS_levelRRraw: 16|8@1+ (1,-100) [0|0] "mm" X

BO_ 1307 TAS_info: 8 ETH
 SG_ TAS_infoIndex M: 0|8@1+ (1,0) [0|0] "" X
 SG_ TAS_infoBuildType m10: 8|8@1+ (1,0) [0|0] "" X
 SG_ TAS_infoBuildConfigId m10: 16|16@1+ (1,0) [0|0] "" X
 SG_ TAS_infoHardwareId m10: 32|1@1+ (1,0) [0|0] "" X
 SG_ TAS_infoComponentId m10: 48|16@1+ (1,0) [0|0] "" X
 SG_ TAS_infoPcbaId m11: 16|8@1+ (1,0) [0|0] "" X
 SG_ TAS_infoAssemblyId m11: 24|8@1+ (1,0) [0|0] "" X
 SG_ TAS_infoUsageId m11: 32|16@1+ (1,0) [0|0] "" X
 SG_ TAS_infoSubUsageId m11: 48|16@1+ (1,0) [0|0] "" X
 SG_ TAS_infoAppCrc m13: 32|32@1+ (1,0) [0|0] "" X
 SG_ TAS_infoBootloaderSvnRevision m14: 8|24@1+ (1,0) [0|0] "" X
 SG_ TAS_infoAppGitHash m17: 10|54@1+ (4,0) [0|0] "" X
 SG_ TAS_infoBootGitHash m18: 10|54@1+ (4,0) [0|0] "" X
 SG_ TAS_infoPlatformType m19: 8|8@1+ (1,0) [0|0] "" X
 SG_ TAS_infoMajorVersion m19: 16|8@1+ (1,0) [0|0] "" X
 SG_ TAS_infoBranchOrigin m19: 24|8@1+ (1,0) [0|0] "" X
 SG_ TAS_infoMaturity m19: 32|8@1+ (1,0) [0|0] "" X
 SG_ TAS_infoHardwareRevision m19: 40|8@1+ (1,0) [0|0] "" X
 SG_ TAS_infoBootUdsProtoVersion m20: 8|8@1+ (1,0) [0|0] "" X
 SG_ TAS_infoBootCrc m20: 32|32@1+ (1,0) [0|0] "" X

BO_ 555 TAS_states: 8 ETH
 SG_ TAS_closureRestriction: 45|1@1+ (1,0) [0|0] "" X
 SG_ TAS_currentLevel: 56|3@1+ (1,0) [0|0] "" X
 SG_ TAS_detectedJack: 52|1@1+ (1,0) [0|0] "" X
 SG_ TAS_detectedLean: 51|1@1+ (1,0) [0|0] "" X
 SG_ TAS_detectedTwist: 50|1@1+ (1,0) [0|0] "" X
 SG_ TAS_levelingItem: 10|3@1+ (1,0) [0|0] "" X
 SG_ TAS_levelingType: 8|2@1+ (1,0) [0|0] "" X
 SG_ TAS_limpHomeMode: 61|3@1+ (1,0) [0|0] "" X
 SG_ TAS_mode: 0|3@1+ (1,0) [0|0] "" X
 SG_ TAS_pressureFL: 25|5@1+ (0.5,0) [0|0] "bara" X
 SG_ TAS_pressureFR: 30|5@1+ (0.5,0) [0|0] "bara" X
 SG_ TAS_pressureGallery: 13|6@1+ (0.33,0) [0|0] "bara" X
 SG_ TAS_pressureRL: 35|5@1+ (0.5,0) [0|0] "bara" X
 SG_ TAS_pressureRR: 40|5@1+ (0.5,0) [0|0] "bara" X
 SG_ TAS_pressureReservoir: 19|6@1+ (0.33,0) [0|0] "bara" X
 SG_ TAS_runMode: 46|3@1+ (1,0) [0|0] "" X
 SG_ TAS_state: 4|4@1+ (1,0) [0|0] "" X
 SG_ TAS_targetLevel: 53|3@1+ (1,0) [0|0] "" X
 SG_ TAS_warningLampRed: 59|1@1+ (1,0) [0|0] "" X
 SG_ TAS_warningLampYellow: 60|1@1+ (1,0) [0|0] "" X

BO_ 1627 TAS_udsResponse: 8 ETH
 SG_ TAS_udsResponseData_H: 0|32@0+ (1,0) [0|0] "" X
 SG_ TAS_udsResponseData_L: 32|32@0+ (1,0) [0|0] "" X

BO_ 743 TAS_warningMatrix1: 8 ETH
 SG_ TAS_a001_WatchdogReset: 0|1@1+ (1,0) [0|0] "" X
 SG_ TAS_a002_PowerLossReset: 1|1@1+ (1,0) [0|0] "" X
 SG_ TAS_a003_SWAssertion: 2|1@1+ (1,0) [0|0] "" X
 SG_ TAS_a004_CANMIA: 3|1@1+ (1,0) [0|0] "" X
 SG_ TAS_a005_CANHighError: 4|1@1+ (1,0) [0|0] "" X
 SG_ TAS_a006_CANLowError: 5|1@1+ (1,0) [0|0] "" X
 SG_ TAS_a007_LINTimeout: 6|1@1+ (1,0) [0|0] "" X
 SG_ TAS_a008_LIN2Error: 7|1@1+ (1,0) [0|0] "" X
 SG_ TAS_a009_LIN3Error: 8|1@1+ (1,0) [0|0] "" X
 SG_ TAS_a010_ExtSupplyVoltError: 9|1@1+ (1,0) [0|0] "" X
 SG_ TAS_a011_ECUSupplyVoltError: 10|1@1+ (1,0) [0|0] "" X
 SG_ TAS_a012_CPUReset: 11|1@1+ (1,0) [0|0] "" X
 SG_ TAS_a013_Shared13: 12|1@1+ (1,0) [0|0] "" X
 SG_ TAS_a014_BridgeFault: 13|1@1+ (1,0) [0|0] "" X
 SG_ TAS_a015_NVMMAlert: 14|1@1+ (1,0) [0|0] "" X
 SG_ TAS_a016_MessageTimingError: 15|1@1+ (1,0) [0|0] "" X
 SG_ TAS_a017_AwakeForTooLong: 16|1@1+ (1,0) [0|0] "" X
 SG_ TAS_a018_ADCError: 17|1@1+ (1,0) [0|0] "" X
 SG_ TAS_a019_I2CError: 18|1@1+ (1,0) [0|0] "" X
 SG_ TAS_a020_PWMError: 19|1@1+ (1,0) [0|0] "" X
 SG_ TAS_a021_TaskSchedulerError: 20|1@1+ (1,0) [0|0] "" X
 SG_ TAS_a022_TaskInitError: 21|1@1+ (1,0) [0|0] "" X
 SG_ TAS_a023_SleepError: 22|1@1+ (1,0) [0|0] "" X
 SG_ TAS_a024_WakeError: 23|1@1+ (1,0) [0|0] "" X
 SG_ TAS_a025_CrashEvent: 24|1@1+ (1,0) [0|0] "" X
 SG_ TAS_a026_FlashMemoryError: 25|1@1+ (1,0) [0|0] "" X
 SG_ TAS_a027_NVRAMCorruption: 26|1@1+ (1,0) [0|0] "" X
 SG_ TAS_a028_NVRAMNotResponding: 27|1@1+ (1,0) [0|0] "" X
 SG_ TAS_a029_NVRAMUninitialized: 28|1@1+ (1,0) [0|0] "" X
 SG_ TAS_a030_PWMerrorFL: 29|1@1+ (1,0) [0|0] "" X
 SG_ TAS_a031_PWMerrorFR: 30|1@1+ (1,0) [0|0] "" X
 SG_ TAS_a032_PWMerrorRL: 31|1@1+ (1,0) [0|0] "" X
 SG_ TAS_a033_PWMerrorRR: 32|1@1+ (1,0) [0|0] "" X
 SG_ TAS_a034_PWMshortFL: 33|1@1+ (1,0) [0|0] "" X
 SG_ TAS_a035_PWMshortFR: 34|1@1+ (1,0) [0|0] "" X
 SG_ TAS_a036_PWMshortRL: 35|1@1+ (1,0) [0|0] "" X
 SG_ TAS_a037_PWMshortRR: 36|1@1+ (1,0) [0|0] "" X
 SG_ TAS_a038_PWMopenFL: 37|1@1+ (1,0) [0|0] "" X
 SG_ TAS_a039_PWMopenFR: 38|1@1+ (1,0) [0|0] "" X
 SG_ TAS_a040_PWMopenRL: 39|1@1+ (1,0) [0|0] "" X
 SG_ TAS_a041_PWMopenRR: 40|1@1+ (1,0) [0|0] "" X

BO_ 859 TAS_warningMatrix2: 8 ETH
 SG_ TAS_a070_underVoltage12V: 5|1@1+ (1,0) [0|0] "" X
 SG_ TAS_a071_overVoltage12V: 6|1@1+ (1,0) [0|0] "" X
 SG_ TAS_a072_shortCircuit5VOnBoard: 7|1@1+ (1,0) [0|0] "" X
 SG_ TAS_a073_underVoltage5VOnBoard: 8|1@1+ (1,0) [0|0] "" X
 SG_ TAS_a074_shortCircuit5VOffBoard: 9|1@1+ (1,0) [0|0] "" X
 SG_ TAS_a075_underVoltage5VOffBoard: 10|1@1+ (1,0) [0|0] "" X
 SG_ TAS_a076_overVoltage5VOffBoard: 11|1@1+ (1,0) [0|0] "" X
 SG_ TAS_a077_pressureSigVTooLow: 12|1@1+ (1,0) [0|0] "" X
 SG_ TAS_a078_pressureSigVTooHigh: 13|1@1+ (1,0) [0|0] "" X
 SG_ TAS_a079_DvrSideCfgMismatch: 14|1@1+ (1,0) [0|0] "" X
 SG_ TAS_a093_OTPError: 28|1@1+ (1,0) [0|0] "" X
 SG_ TAS_a098_MCU_MIA: 33|1@1+ (1,0) [0|0] "" X
 SG_ TAS_a099_EFUSE_MIA: 34|1@1+ (1,0) [0|0] "" X
 SG_ TAS_a100_SCCM_MIA: 35|1@1+ (1,0) [0|0] "" X
 SG_ TAS_a101_ESP_MIA: 36|1@1+ (1,0) [0|0] "" X
 SG_ TAS_a102_DI_MIA: 37|1@1+ (1,0) [0|0] "" X
 SG_ TAS_a103_GTW_MIA: 38|1@1+ (1,0) [0|0] "" X
 SG_ TAS_a105_ECUDebugMode: 40|1@1+ (1,0) [0|0] "" X
 SG_ TAS_a106_HighCPULoad: 41|1@1+ (1,0) [0|0] "" X
 SG_ TAS_a107_HighStackUsage: 42|1@1+ (1,0) [0|0] "" X
 SG_ TAS_a121_maxDutyFL: 56|1@1+ (1,0) [0|0] "" X
 SG_ TAS_a122_maxDutyFR: 57|1@1+ (1,0) [0|0] "" X
 SG_ TAS_a123_maxDutyRL: 58|1@1+ (1,0) [0|0] "" X
 SG_ TAS_a124_maxDutyRR: 59|1@1+ (1,0) [0|0] "" X
 SG_ TAS_a125_maxDutyReservoir: 60|1@1+ (1,0) [0|0] "" X
 SG_ TAS_a126_maxDutyExhaust: 61|1@1+ (1,0) [0|0] "" X
 SG_ TAS_a127_maxDutyBoost: 62|1@1+ (1,0) [0|0] "" X
 SG_ TAS_a128_maxDutyCompressor: 63|1@1+ (1,0) [0|0] "" X

BO_ 631 TAS_warningMatrix3: 8 ETH
 SG_ TAS_a129_openCircuitFL: 0|1@1+ (1,0) [0|0] "" X
 SG_ TAS_a130_openCircuitFR: 1|1@1+ (1,0) [0|0] "" X
 SG_ TAS_a131_openCircuitRL: 2|1@1+ (1,0) [0|0] "" X
 SG_ TAS_a132_openCircuitRR: 3|1@1+ (1,0) [0|0] "" X
 SG_ TAS_a133_openCircuitReservoir: 4|1@1+ (1,0) [0|0] "" X
 SG_ TAS_a134_openCircuitExhaust: 5|1@1+ (1,0) [0|0] "" X
 SG_ TAS_a135_openCircuitBoost: 6|1@1+ (1,0) [0|0] "" X
 SG_ TAS_a136_openCircuitCompressor: 7|1@1+ (1,0) [0|0] "" X
 SG_ TAS_a137_shortCircuitFL: 8|1@1+ (1,0) [0|0] "" X
 SG_ TAS_a138_shortCircuitFR: 9|1@1+ (1,0) [0|0] "" X
 SG_ TAS_a139_shortCircuitRL: 10|1@1+ (1,0) [0|0] "" X
 SG_ TAS_a140_shortCircuitRR: 11|1@1+ (1,0) [0|0] "" X
 SG_ TAS_a141_shortCircuitReservoir: 12|1@1+ (1,0) [0|0] "" X
 SG_ TAS_a142_shortCircuitExhaust: 13|1@1+ (1,0) [0|0] "" X
 SG_ TAS_a143_shortCircuitBoost: 14|1@1+ (1,0) [0|0] "" X
 SG_ TAS_a144_shortCircuitCompressor: 15|1@1+ (1,0) [0|0] "" X
 SG_ TAS_a145_boardFaultFL: 16|1@1+ (1,0) [0|0] "" X
 SG_ TAS_a146_boardFaultFR: 17|1@1+ (1,0) [0|0] "" X
 SG_ TAS_a147_boardFaultRL: 18|1@1+ (1,0) [0|0] "" X
 SG_ TAS_a148_boardFaultRR: 19|1@1+ (1,0) [0|0] "" X
 SG_ TAS_a149_boardFaultReservoir: 20|1@1+ (1,0) [0|0] "" X
 SG_ TAS_a150_boardFaultExhaust: 21|1@1+ (1,0) [0|0] "" X
 SG_ TAS_a151_boardFaultBoost: 22|1@1+ (1,0) [0|0] "" X
 SG_ TAS_a152_boardFaultCompressor: 23|1@1+ (1,0) [0|0] "" X
 SG_ TAS_a153_otherCircuitFL: 24|1@1+ (1,0) [0|0] "" X
 SG_ TAS_a154_otherCircuitFR: 25|1@1+ (1,0) [0|0] "" X
 SG_ TAS_a155_otherCircuitRL: 26|1@1+ (1,0) [0|0] "" X
 SG_ TAS_a156_otherCircuitRR: 27|1@1+ (1,0) [0|0] "" X
 SG_ TAS_a157_otherCircuitReservoir: 28|1@1+ (1,0) [0|0] "" X
 SG_ TAS_a158_otherCircuitExhaust: 29|1@1+ (1,0) [0|0] "" X
 SG_ TAS_a159_otherCircuitBoost: 30|1@1+ (1,0) [0|0] "" X
 SG_ TAS_a160_otherCircuitCompressor: 31|1@1+ (1,0) [0|0] "" X
 SG_ TAS_a161_valveBlockOpenGND: 32|1@1+ (1,0) [0|0] "" X
 SG_ TAS_a162_compressorValveOpenGND: 33|1@1+ (1,0) [0|0] "" X
 SG_ TAS_a163_reservoirFillDisabled: 34|1@1+ (1,0) [0|0] "" X

BO_ 615 TAS_warningMatrix4: 8 ETH
 SG_ TAS_a200_jackModeActive: 7|1@1+ (1,0) [0|0] "" X
 SG_ TAS_a201_lowHVBattery: 8|1@1+ (1,0) [0|0] "" X
 SG_ TAS_a210_outOfRangeCalibration: 17|1@1+ (1,0) [0|0] "" X
 SG_ TAS_a211_noRideHeightCalib: 18|1@1+ (1,0) [0|0] "" X
 SG_ TAS_a212_noCurrentSenseCalib: 19|1@1+ (1,0) [0|0] "" X
 SG_ TAS_a213_yellowWarningLamp: 20|1@1+ (1,0) [0|0] "" X
 SG_ TAS_a214_redWarningLamp: 21|1@1+ (1,0) [0|0] "" X
 SG_ TAS_a215_limpHomeMode10: 22|1@1+ (1,0) [0|0] "" X
 SG_ TAS_a216_limpHomeMode20: 23|1@1+ (1,0) [0|0] "" X
 SG_ TAS_a217_limpHomeMode30: 24|1@1+ (1,0) [0|0] "" X
 SG_ TAS_a218_limpHomeMode40: 25|1@1+ (1,0) [0|0] "" X
 SG_ TAS_a220_exhaustGalleryFault: 27|1@1+ (1,0) [0|0] "" X
 SG_ TAS_a221_valveLeakDetected: 28|1@1+ (1,0) [0|0] "" X
 SG_ TAS_a222_compressorPrefillFault: 29|1@1+ (1,0) [0|0] "" X
 SG_ TAS_a223_blockedAirline: 30|1@1+ (1,0) [0|0] "" X
 SG_ TAS_a224_openAirline: 31|1@1+ (1,0) [0|0] "" X
 SG_ TAS_a225_galleryPressureTooHigh: 32|1@1+ (1,0) [0|0] "" X
 SG_ TAS_a226_PWMfastDetectFL: 33|1@1+ (1,0) [0|0] "" X
 SG_ TAS_a227_PWMfastDetectFR: 34|1@1+ (1,0) [0|0] "" X
 SG_ TAS_a228_PWMfastDetectRL: 35|1@1+ (1,0) [0|0] "" X
 SG_ TAS_a229_PWMfastDetectRR: 36|1@1+ (1,0) [0|0] "" X

BO_ 599 TAS_warningMatrix5: 8 ETH
 SG_ TAS_a290_twistSustainedAtSpeed: 33|1@1+ (1,0) [0|0] "" X
 SG_ TAS_a291_frontAxleTooHigh: 34|1@1+ (1,0) [0|0] "" X
 SG_ TAS_a292_rearAxleTooHigh: 35|1@1+ (1,0) [0|0] "" X
 SG_ TAS_a293_frontAxleTooLow: 36|1@1+ (1,0) [0|0] "" X
 SG_ TAS_a294_rearAxleTooLow: 37|1@1+ (1,0) [0|0] "" X
 SG_ TAS_a295_targetHeightNotMet: 38|1@1+ (1,0) [0|0] "" X

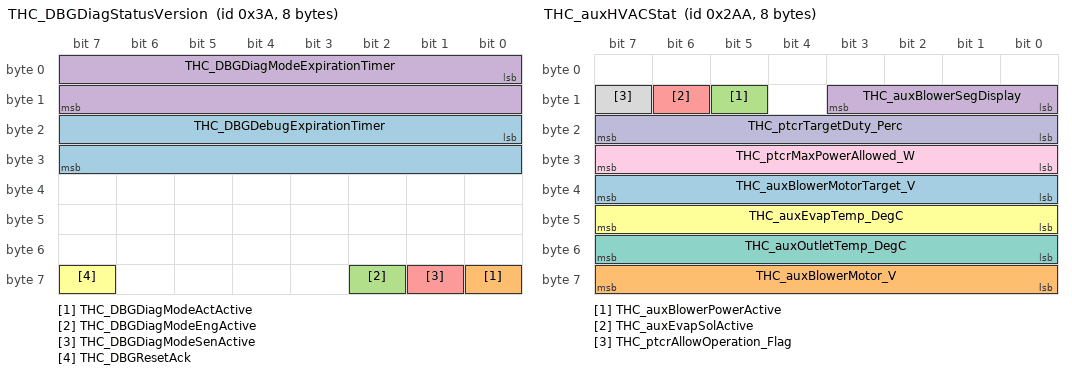
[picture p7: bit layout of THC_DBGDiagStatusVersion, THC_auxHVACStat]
BO_ 58 THC_DBGDiagStatusVersion: 8 ETH
 SG_ THC_DBGDebugExpirationTimer: 16|16@1+ (1,0) [0|0] "sec" X
 SG_ THC_DBGDiagModeActActive: 56|1@1+ (1,0) [0|0] "" X
 SG_ THC_DBGDiagModeEngActive: 58|1@1+ (1,0) [0|0] "" X
 SG_ THC_DBGDiagModeExpirationTimer: 0|16@1+ (1,0) [0|0] "sec" X
 SG_ THC_DBGDiagModeSenActive: 57|1@1+ (1,0) [0|0] "" X
 SG_ THC_DBGResetAck: 63|1@1+ (1,0) [0|0] "" X

BO_ 53 THC_MCUHMIResponse: 8 ETH
 SG_ THC_DefoggingLimit: 43|1@1+ (1,0) [0|0] "" X
 SG_ THC_MCUAconInd_Flag: 32|1@1+ (1,0) [0|0] "" X
 SG_ THC_MCUAutoInd_Flag: 24|1@1+ (1,0) [0|0] "" X
 SG_ THC_MCUBlowerSegDis_Flag: 20|4@1+ (1,0) [0|0] "" X
 SG_ THC_MCUDefogInd_Flag: 26|2@1+ (1,0) [0|0] "" X
 SG_ THC_MCUDualInd_Flag: 25|1@1+ (1,0) [0|0] "" X
 SG_ THC_MCUEcoInd_Flag: 31|1@1+ (1,0) [0|0] "" X
 SG_ THC_MCUHtronInd_Flag: 33|1@1+ (1,0) [0|0] "" X
 SG_ THC_MCUIntakeInd_Flag: 29|2@1+ (1,0) [0|0] "" X
 SG_ THC_MCUIntakePercent: 34|6@1+ (2,0) [0|0] "%" X
 SG_ THC_MCULeftTempSetpoint_DegC: 0|8@1+ (0.5,0) [0|0] "degC" X
 SG_ THC_MCUModeDis_Flag: 16|4@1+ (1,0) [0|0] "" X
 SG_ THC_MCUOffInd_Flag: 28|1@1+ (1,0) [0|0] "" X
 SG_ THC_MCURightTempSetpoint_DegC: 8|8@1+ (0.5,0) [0|0] "degC" X
 SG_ THC_ManualBlowerHotLimit: 41|1@1+ (1,0) [0|0] "" X
 SG_ THC_ManualModeHotLimit: 40|1@1+ (1,0) [0|0] "" X
 SG_ THC_RangeModeHotLimit: 42|1@1+ (1,0) [0|0] "" X

BO_ 45 THC_alertMatrix1: 8 ETH
 SG_ THC_w0001_bootLoaderCRC: 0|1@1+ (1,0) [0|0] "" X
 SG_ THC_w0002_bootloaderHwId: 1|1@1+ (1,0) [0|0] "" X
 SG_ THC_w0003_bootloaderBufOvfl: 2|1@1+ (1,0) [0|0] "" X
 SG_ THC_w0004_nvAccessPViol: 3|1@1+ (1,0) [0|0] "" X
 SG_ THC_w0005_unexpectedInt: 4|1@1+ (1,0) [0|0] "" X
 SG_ THC_w0006_reboot: 5|1@1+ (1,0) [0|0] "" X
 SG_ THC_w0007_bootloader: 6|1@1+ (1,0) [0|0] "" X
 SG_ THC_w0008_ASSERT: 7|1@1+ (1,0) [0|0] "" X
 SG_ THC_w0009_EXVLinTmo: 8|1@1+ (1,0) [0|0] "" X
 SG_ THC_w0010_EXVOutOfPosition: 9|1@1+ (1,0) [0|0] "" X
 SG_ THC_w0011_msgLen: 10|1@1+ (1,0) [0|0] "" X
 SG_ THC_w0012_msgSigOutsideRange: 11|1@1+ (1,0) [0|0] "" X
 SG_ THC_w0013_compressorTHCForcedOff: 12|1@1+ (1,0) [0|0] "" X
 SG_ THC_w0014_compComponentShutdown: 13|1@1+ (1,0) [0|0] "" X
 SG_ THC_w0015_compLimitedOpRange: 14|1@1+ (1,0) [0|0] "" X
 SG_ THC_w0016_compOverheatWarning: 15|1@1+ (1,0) [0|0] "" X
 SG_ THC_w0017_auxBlowerPwmOS: 16|1@1+ (1,0) [0|0] "" X
 SG_ THC_w0018_unused018: 17|1@1+ (1,0) [0|0] "" X
 SG_ THC_w0019_tempIncarDrvHsg: 18|1@1+ (1,0) [0|0] "" X
 SG_ THC_w0020_tempIncarDrvHsgRange: 19|1@1+ (1,0) [0|0] "" X
 SG_ THC_w0021_sanityIncarDriver: 20|1@1+ (1,0) [0|0] "" X
 SG_ THC_w0022_tempIncarDriver: 21|1@1+ (1,0) [0|0] "" X
 SG_ THC_w0023_tempIncarDriverRange: 22|1@1+ (1,0) [0|0] "" X
 SG_ THC_w0024_pumpPT2Limp: 23|1@1+ (1,0) [0|0] "" X
 SG_ THC_w0025_pumpPT2Stop: 24|1@1+ (1,0) [0|0] "" X
 SG_ THC_w0026_DASCanTmo: 25|1@1+ (1,0) [0|0] "" X
 SG_ THC_w0027_tempAuxHvacDuctRange: 26|1@1+ (1,0) [0|0] "" X
 SG_ THC_w0028_sanityTempAuxHvacDuct: 27|1@1+ (1,0) [0|0] "" X
 SG_ THC_w0029_sanityPumpPT2: 28|1@1+ (1,0) [0|0] "" X
 SG_ THC_w0030_pumpPT2FaultMax: 29|1@1+ (1,0) [0|0] "" X
 SG_ THC_w0031_compNoFeedbk: 30|1@1+ (1,0) [0|0] "" X
 SG_ THC_w0032_unused032: 31|1@1+ (1,0) [0|0] "" X
 SG_ THC_w0033_unused033: 32|1@1+ (1,0) [0|0] "" X
 SG_ THC_w0034_compOvercurrent: 33|1@1+ (1,0) [0|0] "" X
 SG_ THC_w0035_tempAuxHvacDuct: 34|1@1+ (1,0) [0|0] "" X
 SG_ THC_w0036_PTCRCanTmo: 35|1@1+ (1,0) [0|0] "" X
 SG_ THC_w0037_unused037: 36|1@1+ (1,0) [0|0] "" X
 SG_ THC_w0038_radFanSelfError: 37|1@1+ (1,0) [0|0] "" X
 SG_ THC_w0039_pumpPTLimp: 38|1@1+ (1,0) [0|0] "" X
 SG_ THC_w0040_pumpPTStop: 39|1@1+ (1,0) [0|0] "" X
 SG_ THC_w0041_tempAuxHvacEvap: 40|1@1+ (1,0) [0|0] "" X
 SG_ THC_w0042_tempAuxHvacEvapRange: 41|1@1+ (1,0) [0|0] "" X
 SG_ THC_w0043_sanityTempAuxHvacEvap: 42|1@1+ (1,0) [0|0] "" X
 SG_ THC_w0044_sanityPumpPT: 43|1@1+ (1,0) [0|0] "" X
 SG_ THC_w0045_pumpPTFaultMax: 44|1@1+ (1,0) [0|0] "" X
 SG_ THC_w0046_shutterLinTmo: 45|1@1+ (1,0) [0|0] "" X
 SG_ THC_w0047_pumpBat1Limp: 46|1@1+ (1,0) [0|0] "" X
 SG_ THC_w0048_pumpBat1Stop: 47|1@1+ (1,0) [0|0] "" X
 SG_ THC_w0049_auxBlowerRelayOS: 48|1@1+ (1,0) [0|0] "" X
 SG_ THC_w0050_auxEvapTXVOS: 49|1@1+ (1,0) [0|0] "" X
 SG_ THC_w0051_radFanLinTmo: 50|1@1+ (1,0) [0|0] "" X
 SG_ THC_w0052_sanityPumpBat1: 51|1@1+ (1,0) [0|0] "" X
 SG_ THC_w0053_pumpBat1FaultMax: 52|1@1+ (1,0) [0|0] "" X
 SG_ THC_w0054_tempIncarPsngr: 53|1@1+ (1,0) [0|0] "" X
 SG_ THC_w0055_pumpBat2Limp: 54|1@1+ (1,0) [0|0] "" X
 SG_ THC_w0056_pumpBat2Stop: 55|1@1+ (1,0) [0|0] "" X
 SG_ THC_w0057_tempIncarPsngrRange: 56|1@1+ (1,0) [0|0] "" X
 SG_ THC_w0058_shutterOutOfPosition: 57|1@1+ (1,0) [0|0] "" X
 SG_ THC_w0059_sanityShutter: 58|1@1+ (1,0) [0|0] "" X
 SG_ THC_w0060_sanityPumpBat2: 59|1@1+ (1,0) [0|0] "" X
 SG_ THC_w0061_pumpBat2FaultMax: 60|1@1+ (1,0) [0|0] "" X
 SG_ THC_w0062_DISCanTmo: 61|1@1+ (1,0) [0|0] "" X
 SG_ THC_w0063_unused63: 62|1@1+ (1,0) [0|0] "" X
 SG_ THC_w0064_unused64: 63|1@1+ (1,0) [0|0] "" X

BO_ 46 THC_alertMatrix2: 8 ETH
 SG_ THC_w0065_bcRlsHumiditySNA: 0|1@1+ (1,0) [0|0] "" X
 SG_ THC_w0066_valveRadBypFeedbk: 1|1@1+ (1,0) [0|0] "" X
 SG_ THC_w0067_valveRadBypRange: 2|1@1+ (1,0) [0|0] "" X
 SG_ THC_w0068_unused68: 3|1@1+ (1,0) [0|0] "" X
 SG_ THC_w0069_unused69: 4|1@1+ (1,0) [0|0] "" X
 SG_ THC_w0070_unused70: 5|1@1+ (1,0) [0|0] "" X
 SG_ THC_w0071_unused71: 6|1@1+ (1,0) [0|0] "" X
 SG_ THC_w0072_valveChillBypFeedbk: 7|1@1+ (1,0) [0|0] "" X
 SG_ THC_w0073_valveChillBypRange: 8|1@1+ (1,0) [0|0] "" X
 SG_ THC_w0074_unused74: 9|1@1+ (1,0) [0|0] "" X
 SG_ THC_w0075_unused75: 10|1@1+ (1,0) [0|0] "" X
 SG_ THC_w0076_unused76: 11|1@1+ (1,0) [0|0] "" X
 SG_ THC_w0077_unused77: 12|1@1+ (1,0) [0|0] "" X
 SG_ THC_w0078_valveParallelFeedbk: 13|1@1+ (1,0) [0|0] "" X
 SG_ THC_w0079_valveParallelRange: 14|1@1+ (1,0) [0|0] "" X
 SG_ THC_w0080_unused80: 15|1@1+ (1,0) [0|0] "" X
 SG_ THC_w0081_unused81: 16|1@1+ (1,0) [0|0] "" X
 SG_ THC_w0082_sanityValveParallel: 17|1@1+ (1,0) [0|0] "" X
 SG_ THC_w0083_chillTXV: 18|1@1+ (1,0) [0|0] "" X
 SG_ THC_w0084_sanityChillTXV: 19|1@1+ (1,0) [0|0] "" X
 SG_ THC_w0085_evapTXV: 20|1@1+ (1,0) [0|0] "" X
 SG_ THC_w0086_sanityEvapTXV: 21|1@1+ (1,0) [0|0] "" X
 SG_ THC_w0087_tempBatIn: 22|1@1+ (1,0) [0|0] "" X
 SG_ THC_w0088_tempBatInRange: 23|1@1+ (1,0) [0|0] "" X
 SG_ THC_w0089_sanityTempBatIn: 24|1@1+ (1,0) [0|0] "" X
 SG_ THC_w0090_unused090: 25|1@1+ (1,0) [0|0] "" X
 SG_ THC_w0091_unused091: 26|1@1+ (1,0) [0|0] "" X
 SG_ THC_w0092_unused092: 27|1@1+ (1,0) [0|0] "" X
 SG_ THC_w0093_tempBatHeater: 28|1@1+ (1,0) [0|0] "" X
 SG_ THC_w0094_tempBatHeaterRange: 29|1@1+ (1,0) [0|0] "" X
 SG_ THC_w0095_sanityTempBatHeater: 30|1@1+ (1,0) [0|0] "" X
 SG_ THC_w0096_tempChargerPTInSensor: 31|1@1+ (1,0) [0|0] "" X
 SG_ THC_w0097_tempChargerPTInRange: 32|1@1+ (1,0) [0|0] "" X
 SG_ THC_w0098_sanityTempChargerPTIn: 33|1@1+ (1,0) [0|0] "" X
 SG_ THC_w0099_unused99: 34|1@1+ (1,0) [0|0] "" X
 SG_ THC_w0100_unused100: 35|1@1+ (1,0) [0|0] "" X
 SG_ THC_w0101_unused101: 36|1@1+ (1,0) [0|0] "" X
 SG_ THC_w0102_unused102: 37|1@1+ (1,0) [0|0] "" X
 SG_ THC_w0103_unused103: 38|1@1+ (1,0) [0|0] "" X
 SG_ THC_w0104_unused104: 39|1@1+ (1,0) [0|0] "" X
 SG_ THC_w0105_coolantBottleLowLevel: 40|1@1+ (1,0) [0|0] "" X
 SG_ THC_w0106_unused106: 41|1@1+ (1,0) [0|0] "" X
 SG_ THC_w0107_unused107: 42|1@1+ (1,0) [0|0] "" X
 SG_ THC_w0108_unused108: 43|1@1+ (1,0) [0|0] "" X
 SG_ THC_w0109_unused109: 44|1@1+ (1,0) [0|0] "" X
 SG_ THC_w0110_PTCBankStuckOn: 45|1@1+ (1,0) [0|0] "" X
 SG_ THC_w0111_unused111: 46|1@1+ (1,0) [0|0] "" X
 SG_ THC_w0112_PTCTempRange: 47|1@1+ (1,0) [0|0] "" X
 SG_ THC_w0113_unused113: 48|1@1+ (1,0) [0|0] "" X
 SG_ THC_w0114_coolantHeaterOpenShort: 49|1@1+ (1,0) [0|0] "" X
 SG_ THC_w0115_sanityBatHeater: 50|1@1+ (1,0) [0|0] "" X
 SG_ THC_w0116_fanLeft: 51|1@1+ (1,0) [0|0] "" X
 SG_ THC_w0117_unused117: 52|1@1+ (1,0) [0|0] "" X
 SG_ THC_w0118_fanRight: 53|1@1+ (1,0) [0|0] "" X
 SG_ THC_w0119_unused119: 54|1@1+ (1,0) [0|0] "" X
 SG_ THC_w0120_condLeftShutrLossCom: 55|1@1+ (1,0) [0|0] "" X
 SG_ THC_w0121_condLeftShutrRange: 56|1@1+ (1,0) [0|0] "" X
 SG_ THC_w0122_condLeftShutrNoFeedbk: 57|1@1+ (1,0) [0|0] "" X
 SG_ THC_w0123_sanityCondLeftShutr: 58|1@1+ (1,0) [0|0] "" X
 SG_ THC_w0124_condRightShutrLossCom: 59|1@1+ (1,0) [0|0] "" X
 SG_ THC_w0125_condRightShutrRange: 60|1@1+ (1,0) [0|0] "" X
 SG_ THC_w0126_condRightShutrNoFeedbk: 61|1@1+ (1,0) [0|0] "" X
 SG_ THC_w0127_sanityCondRightShutr: 62|1@1+ (1,0) [0|0] "" X
 SG_ THC_w0128_radLeftShutrLossCom: 63|1@1+ (1,0) [0|0] "" X

BO_ 47 THC_alertMatrix3: 8 ETH
 SG_ THC_w0129_radLeftShutrRange: 0|1@1+ (1,0) [0|0] "" X
 SG_ THC_w0130_radLeftShutrNoFeedbk: 1|1@1+ (1,0) [0|0] "" X
 SG_ THC_w0131_sanityRadLeftShutr: 2|1@1+ (1,0) [0|0] "" X
 SG_ THC_w0132_radRightShutrLossCom: 3|1@1+ (1,0) [0|0] "" X
 SG_ THC_w0133_radRightShutrRange: 4|1@1+ (1,0) [0|0] "" X
 SG_ THC_w0134_radRightShutrNoFeedbk: 5|1@1+ (1,0) [0|0] "" X
 SG_ THC_w0135_sanityRadRightShutr: 6|1@1+ (1,0) [0|0] "" X
 SG_ THC_w0136_rfrgDisPress: 7|1@1+ (1,0) [0|0] "" X
 SG_ THC_w0137_rfrgDisTemp: 8|1@1+ (1,0) [0|0] "" X
 SG_ THC_w0138_rfrgDisTempRange: 9|1@1+ (1,0) [0|0] "" X
 SG_ THC_w0139_rfrgDisPressRange: 10|1@1+ (1,0) [0|0] "" X
 SG_ THC_w0140_sanityRfrgDisPress: 11|1@1+ (1,0) [0|0] "" X
 SG_ THC_w0141_sanityRfrgDisTemp: 12|1@1+ (1,0) [0|0] "" X
 SG_ THC_w0142_rfrgSuctPress: 13|1@1+ (1,0) [0|0] "" X
 SG_ THC_w0143_rfrgSuctTemp: 14|1@1+ (1,0) [0|0] "" X
 SG_ THC_w0144_rfrgSuctTempRange: 15|1@1+ (1,0) [0|0] "" X
 SG_ THC_w0145_rfrgSuctPressRange: 16|1@1+ (1,0) [0|0] "" X
 SG_ THC_w0146_sanityRfrgSuctPress: 17|1@1+ (1,0) [0|0] "" X
 SG_ THC_w0147_sanityRfrgSuctTemp: 18|1@1+ (1,0) [0|0] "" X
 SG_ THC_w0148_refrigerantLow: 19|1@1+ (1,0) [0|0] "" X
 SG_ THC_w0149_refrigLowChiller: 20|1@1+ (1,0) [0|0] "" X
 SG_ THC_w0150_evapFreezeProtActive: 21|1@1+ (1,0) [0|0] "" X
 SG_ THC_w0151_canRxOverflow: 22|1@1+ (1,0) [0|0] "" X
 SG_ THC_w0152_canTxFull: 23|1@1+ (1,0) [0|0] "" X
 SG_ THC_w0153_unused153: 24|1@1+ (1,0) [0|0] "" X
 SG_ THC_w0154_unused154: 25|1@1+ (1,0) [0|0] "" X
 SG_ THC_w0155_xgate: 26|1@1+ (1,0) [0|0] "" X
 SG_ THC_w0156_unused156: 27|1@1+ (1,0) [0|0] "" X
 SG_ THC_w0157_unused157: 28|1@1+ (1,0) [0|0] "" X
 SG_ THC_w0158_unused158: 29|1@1+ (1,0) [0|0] "" X
 SG_ THC_w0159_unused159: 30|1@1+ (1,0) [0|0] "" X
 SG_ THC_w0160_compOvervoltage: 31|1@1+ (1,0) [0|0] "" X
 SG_ THC_w0161_5Voutput: 32|1@1+ (1,0) [0|0] "" X
 SG_ THC_w0162_unused162: 33|1@1+ (1,0) [0|0] "" X
 SG_ THC_w0163_unused163: 34|1@1+ (1,0) [0|0] "" X
 SG_ THC_w0164_fanRelaySolenoidOS: 35|1@1+ (1,0) [0|0] "" X
 SG_ THC_w0165_12VBatVoltage: 36|1@1+ (1,0) [0|0] "" X
 SG_ THC_w0166_unused166: 37|1@1+ (1,0) [0|0] "" X
 SG_ THC_w0167_unused167: 38|1@1+ (1,0) [0|0] "" X
 SG_ THC_w0168_eeprom: 39|1@1+ (1,0) [0|0] "" X
 SG_ THC_w0169_unused169: 40|1@1+ (1,0) [0|0] "" X
 SG_ THC_w0170_solenoidOutputs: 41|1@1+ (1,0) [0|0] "" X
 SG_ THC_w0171_unused171: 42|1@1+ (1,0) [0|0] "" X
 SG_ THC_w0172_unused172: 43|1@1+ (1,0) [0|0] "" X
 SG_ THC_w0173_unused173: 44|1@1+ (1,0) [0|0] "" X
 SG_ THC_w0174_unused174: 45|1@1+ (1,0) [0|0] "" X
 SG_ THC_w0175_unused175: 46|1@1+ (1,0) [0|0] "" X
 SG_ THC_w0176_unused176: 47|1@1+ (1,0) [0|0] "" X
 SG_ THC_w0177_GTWCanTmo: 48|1@1+ (1,0) [0|0] "" X
 SG_ THC_w0178_RCCMCanTmo: 49|1@1+ (1,0) [0|0] "" X
 SG_ THC_w0179_BMSCanTmo: 50|1@1+ (1,0) [0|0] "" X
 SG_ THC_w0180_DICanTmo: 51|1@1+ (1,0) [0|0] "" X
 SG_ THC_w0181_DCDCCanTmo: 52|1@1+ (1,0) [0|0] "" X
 SG_ THC_w0182_CHGCanTmo: 53|1@1+ (1,0) [0|0] "" X
 SG_ THC_w0183_PTCCanTmo: 54|1@1+ (1,0) [0|0] "" X
 SG_ THC_w0184_sanityAmbientRaw: 55|1@1+ (1,0) [0|0] "" X
 SG_ THC_w0185_unused185: 56|1@1+ (1,0) [0|0] "" X
 SG_ THC_w0186_CHGSCanTmo: 57|1@1+ (1,0) [0|0] "" X
 SG_ THC_w0187_unused187: 58|1@1+ (1,0) [0|0] "" X
 SG_ THC_w0188_GBLCanTmo: 59|1@1+ (1,0) [0|0] "" X
 SG_ THC_w0189_DriveIgnMismatch: 60|1@1+ (1,0) [0|0] "" X
 SG_ THC_w0190_compShortCircuit: 61|1@1+ (1,0) [0|0] "" X
 SG_ THC_w0191_unused191: 62|1@1+ (1,0) [0|0] "" X
 SG_ THC_w0192_unused192: 63|1@1+ (1,0) [0|0] "" X

BO_ 48 THC_alertMatrix4: 8 ETH
 SG_ THC_w0193_unused193: 0|1@1+ (1,0) [0|0] "" X
 SG_ THC_w0194_RCCMModeAct: 1|1@1+ (1,0) [0|0] "" X
 SG_ THC_w0195_RCCMleftTempAct: 2|1@1+ (1,0) [0|0] "" X
 SG_ THC_w0196_RCCMRightTempAct: 3|1@1+ (1,0) [0|0] "" X
 SG_ THC_w0197_RCCMIntakeAct: 4|1@1+ (1,0) [0|0] "" X
 SG_ THC_w0198_RCCMDefAct: 5|1@1+ (1,0) [0|0] "" X
 SG_ THC_w0199_unused199: 6|1@1+ (1,0) [0|0] "" X
 SG_ THC_w0200_RCCMIncarTempSns: 7|1@1+ (1,0) [0|0] "" X
 SG_ THC_w0201_unused201: 8|1@1+ (1,0) [0|0] "" X
 SG_ THC_w0202_RCCMAmbientTempSns: 9|1@1+ (1,0) [0|0] "" X
 SG_ THC_w0203_unused203: 10|1@1+ (1,0) [0|0] "" X
 SG_ THC_w0204_RCCMEvapSns: 11|1@1+ (1,0) [0|0] "" X
 SG_ THC_w0205_unused205: 12|1@1+ (1,0) [0|0] "" X
 SG_ THC_w0206_RCCMLeftVentDuctSns: 13|1@1+ (1,0) [0|0] "" X
 SG_ THC_w0207_RCCMRightVentDuctSns: 14|1@1+ (1,0) [0|0] "" X
 SG_ THC_w0208_RCCMLeftFloorDuctSns: 15|1@1+ (1,0) [0|0] "" X
 SG_ THC_w0209_RCCMRightFloorDuctSns: 16|1@1+ (1,0) [0|0] "" X
 SG_ THC_w0210_RCCMDefDuctSns: 17|1@1+ (1,0) [0|0] "" X
 SG_ THC_w0211_unused211: 18|1@1+ (1,0) [0|0] "" X
 SG_ THC_w0212_RLSCanTmo: 19|1@1+ (1,0) [0|0] "" X
 SG_ THC_w0213_RCCMMsg227Timeout: 20|1@1+ (1,0) [0|0] "" X
 SG_ THC_w0214_RCCMMsg237Timeout: 21|1@1+ (1,0) [0|0] "" X
 SG_ THC_w0215_RCCMMsg247Timeout: 22|1@1+ (1,0) [0|0] "" X
 SG_ THC_w0216_unused216: 23|1@1+ (1,0) [0|0] "" X
 SG_ THC_w0217_RCCMMsg337Timeout: 24|1@1+ (1,0) [0|0] "" X
 SG_ THC_w0218_unused218: 25|1@1+ (1,0) [0|0] "" X
 SG_ THC_w0219_taskDeadlineOverdue: 26|1@1+ (1,0) [0|0] "" X
 SG_ THC_w0220_PTC_PtcFault: 27|1@1+ (1,0) [0|0] "" X
 SG_ THC_w0221_ptcrHighVoltageRange: 28|1@1+ (1,0) [0|0] "" X
 SG_ THC_w0222_ptcrOverCurrent: 29|1@1+ (1,0) [0|0] "" X
 SG_ THC_w0223_ptcrThermalShutdown: 30|1@1+ (1,0) [0|0] "" X
 SG_ THC_w0224_ptcrSnsFail: 31|1@1+ (1,0) [0|0] "" X
 SG_ THC_w0225_ptcrLowVoltageRange: 32|1@1+ (1,0) [0|0] "" X
 SG_ THC_w0226_ptcrIGBTShort: 33|1@1+ (1,0) [0|0] "" X
 SG_ THC_w0227_unused227: 34|1@1+ (1,0) [0|0] "" X
 SG_ THC_w0228_unused228: 35|1@1+ (1,0) [0|0] "" X
 SG_ THC_w0229_unused229: 36|1@1+ (1,0) [0|0] "" X
 SG_ THC_w0230_unused230: 37|1@1+ (1,0) [0|0] "" X
 SG_ THC_w0231_unused231: 38|1@1+ (1,0) [0|0] "" X
 SG_ THC_w0232_unused232: 39|1@1+ (1,0) [0|0] "" X
 SG_ THC_w0233_unused233: 40|1@1+ (1,0) [0|0] "" X
 SG_ THC_w0234_unused234: 41|1@1+ (1,0) [0|0] "" X
 SG_ THC_w0235_unused235: 42|1@1+ (1,0) [0|0] "" X
 SG_ THC_w0236_unused236: 43|1@1+ (1,0) [0|0] "" X
 SG_ THC_w0237_PTC_LeftCoreTempSensor: 44|1@1+ (1,0) [0|0] "" X
 SG_ THC_w0238_PTC_RtCoreTempSensor: 45|1@1+ (1,0) [0|0] "" X
 SG_ THC_w0239_unused239: 46|1@1+ (1,0) [0|0] "" X
 SG_ THC_w0240_unused240: 47|1@1+ (1,0) [0|0] "" X
 SG_ THC_w0241_unused241: 48|1@1+ (1,0) [0|0] "" X
 SG_ THC_w0242_exvSelfError: 49|1@1+ (1,0) [0|0] "" X
 SG_ THC_w0243_aqsLinTmo: 50|1@1+ (1,0) [0|0] "" X
 SG_ THC_w0244_PTC_LimitedOpCause: 51|1@1+ (1,0) [0|0] "" X
 SG_ THC_w0245_CANBusOff: 52|1@1+ (1,0) [0|0] "" X
 SG_ THC_w0246_unused246: 53|1@1+ (1,0) [0|0] "" X
 SG_ THC_w0247_unused247: 54|1@1+ (1,0) [0|0] "" X
 SG_ THC_w0248_unused248: 55|1@1+ (1,0) [0|0] "" X
 SG_ THC_w0249_sanityTempRiBatHeat: 56|1@1+ (1,0) [0|0] "" X
 SG_ THC_w0250_rfrgDisOverTemp: 57|1@1+ (1,0) [0|0] "" X
 SG_ THC_w0251_rfrgDisPressLo: 58|1@1+ (1,0) [0|0] "" X
 SG_ THC_w0252_rfrgSuctPressLo: 59|1@1+ (1,0) [0|0] "" X
 SG_ THC_w0253_rfrgDisPressHi: 60|1@1+ (1,0) [0|0] "" X
 SG_ THC_w0254_radFanProblem: 61|1@1+ (1,0) [0|0] "" X
 SG_ THC_w0255_hvacIonizer: 62|1@1+ (1,0) [0|0] "" X
 SG_ THC_w0256_radFanOS: 63|1@1+ (1,0) [0|0] "" X

BO_ 682 THC_auxHVACStat: 8 ETH
 SG_ THC_auxBlowerMotorTarget_V: 32|8@1+ (0.1,0) [0|0] "V" X
 SG_ THC_auxBlowerMotor_V: 56|8@1+ (0.1,0) [0|0] "V" X
 SG_ THC_auxBlowerPowerActive: 13|1@1+ (1,0) [0|0] "" X
 SG_ THC_auxBlowerSegDisplay: 8|4@1+ (1,0) [0|0] "" X
 SG_ THC_auxEvapSolActive: 14|1@1+ (1,0) [0|0] "" X
 SG_ THC_auxEvapTemp_DegC: 40|8@1+ (0.1,-5) [0|0] "degC" X
 SG_ THC_auxOutletTemp_DegC: 48|8@1+ (1,-40) [0|0] "degC" X
 SG_ THC_ptcrAllowOperation_Flag: 15|1@1+ (1,0) [0|0] "" X
 SG_ THC_ptcrMaxPowerAllowed_W: 24|8@1+ (50,0) [0|0] "W" X
 SG_ THC_ptcrTargetDuty_Perc: 16|8@1+ (0.5,0) [0|0] "%" X

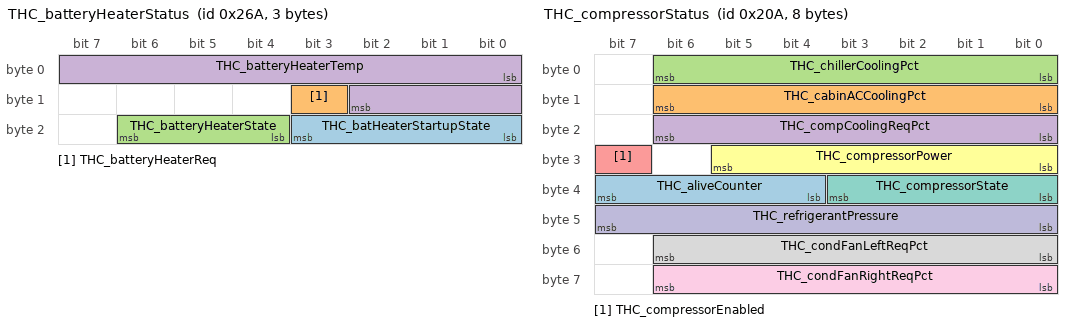
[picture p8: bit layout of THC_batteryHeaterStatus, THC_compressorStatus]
BO_ 618 THC_batteryHeaterStatus: 3 ETH
 SG_ THC_batHeaterStartupState: 16|4@1+ (1,0) [0|0] "" X
 SG_ THC_batteryHeaterReq: 11|1@1+ (1,0) [0|0] "" X
 SG_ THC_batteryHeaterState: 20|3@1+ (1,0) [0|0] "" X
 SG_ THC_batteryHeaterTemp: 0|11@1+ (0.125,-40) [0|0] "degC" X

BO_ 522 THC_compressorStatus: 8 ETH
 SG_ THC_aliveCounter: 36|4@1+ (1,0) [0|0] "" X
 SG_ THC_cabinACCoolingPct: 8|7@1+ (1,0) [0|0] "%" X
 SG_ THC_chillerCoolingPct: 0|7@1+ (1,0) [0|0] "%" X
 SG_ THC_compCoolingReqPct: 16|7@1+ (1,0) [0|0] "%" X
 SG_ THC_compressorEnabled: 31|1@1+ (1,0) [0|0] "" X
 SG_ THC_compressorPower: 24|6@1+ (0.1,0) [0|0] "kW" X
 SG_ THC_compressorState: 32|4@1+ (1,0) [0|0] "" X
 SG_ THC_condFanLeftReqPct: 48|7@1+ (1,0) [0|0] "%" X
 SG_ THC_condFanRightReqPct: 56|7@1+ (1,0) [0|0] "%" X
 SG_ THC_refrigerantPressure: 40|8@1+ (0.125,0) [0|0] "bar" X

BO_ 778 THC_coolantFlow: 8 ETH
 SG_ THC_12VpowerNeeded: 39|1@1+ (1,0) [0|0] "" X
 SG_ THC_PTPumpActive: 19|1@1+ (1,0) [0|0] "" X
 SG_ THC_PTWasteHeatOn: 17|1@1+ (1,0) [0|0] "" X
 SG_ THC_batteryHeaterOn: 16|1@1+ (1,0) [0|0] "" X
 SG_ THC_batteryPumpsActive: 20|1@1+ (1,0) [0|0] "" X
 SG_ THC_botLevelSensOK: 33|1@1+ (1,0) [0|0] "" X
 SG_ THC_chillSolActive: 23|1@1+ (1,0) [0|0] "" X
 SG_ THC_chillerBypassYMaxUCPct: 48|7@1+ (1,0) [0|0] "%" X
 SG_ THC_chillerCompArbState: 40|4@1+ (1,0) [0|0] "" X
 SG_ THC_chillerMode: 44|2@1+ (1,0) [0|0] "" X
 SG_ THC_compressorActive: 24|1@1+ (1,0) [0|0] "" X
 SG_ THC_condFanLeftActive: 22|1@1+ (1,0) [0|0] "" X
 SG_ THC_condFanRightActive: 21|1@1+ (1,0) [0|0] "" X
 SG_ THC_coolantBatFlowPct: 56|7@1+ (1,0) [0|0] "%" X
 SG_ THC_currentModeTransPri: 28|4@1+ (1,0) [0|0] "" X
 SG_ THC_desiredMode: 8|2@1+ (1,0) [0|0] "" X
 SG_ THC_desiredModeTransPri: 36|3@1+ (1,0) [0|0] "" X
 SG_ THC_evapSolActive: 18|1@1+ (1,0) [0|0] "" X
 SG_ THC_limpModeAct: 34|1@1+ (1,0) [0|0] "" X
 SG_ THC_mode: 46|2@1+ (1,0) [0|0] "" X
 SG_ THC_modeValveParallel: 25|1@1+ (1,0) [0|0] "" X
 SG_ THC_postRunRequest: 32|1@1+ (1,0) [0|0] "" X
 SG_ THC_previousMode: 26|2@1+ (1,0) [0|0] "" X

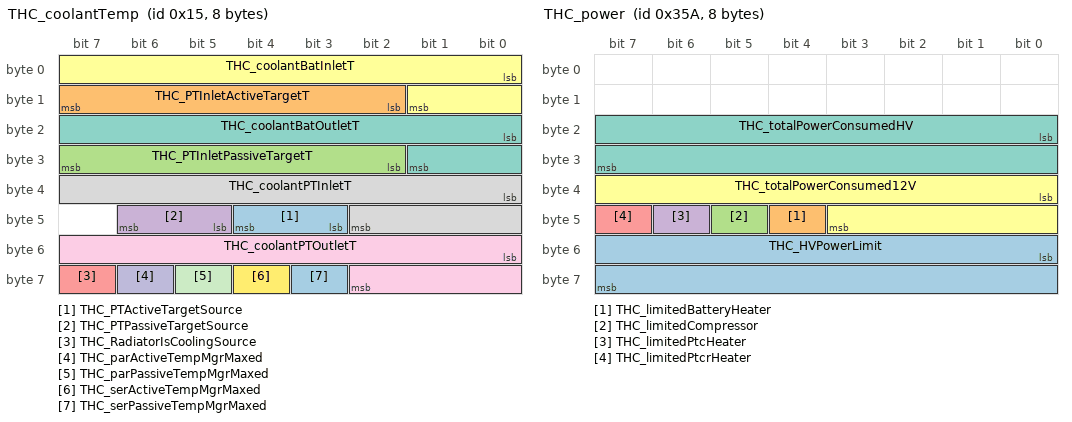
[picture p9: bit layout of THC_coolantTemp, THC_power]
BO_ 21 THC_coolantTemp: 8 ETH
 SG_ THC_PTActiveTargetSource: 43|2@1+ (1,0) [0|0] "" X
 SG_ THC_PTInletActiveTargetT: 10|6@1+ (1,5) [0|0] "degC" X
 SG_ THC_PTInletPassiveTargetT: 26|6@1+ (1,0) [0|0] "degC" X
 SG_ THC_PTPassiveTargetSource: 45|2@1+ (1,0) [0|0] "" X
 SG_ THC_RadiatorIsCoolingSource: 63|1@1+ (1,0) [0|0] "" X
 SG_ THC_coolantBatInletT: 0|10@1+ (0.125,-40) [0|0] "degC" X
 SG_ THC_coolantBatOutletT: 16|10@1+ (0.125,-40) [0|0] "degC" X
 SG_ THC_coolantPTInletT: 32|11@1+ (0.125,-40) [0|0] "degC" X
 SG_ THC_coolantPTOutletT: 48|11@1+ (0.125,-40) [0|0] "degC" X
 SG_ THC_parActiveTempMgrMaxed: 62|1@1+ (1,0) [0|0] "" X
 SG_ THC_parPassiveTempMgrMaxed: 61|1@1+ (1,0) [0|0] "" X
 SG_ THC_serActiveTempMgrMaxed: 60|1@1+ (1,0) [0|0] "" X
 SG_ THC_serPassiveTempMgrMaxed: 59|1@1+ (1,0) [0|0] "" X

BO_ 1610 THC_dtcMatrix: 8 ETH
 SG_ THC_dtcMultiplex M: 0|8@1+ (1,0) [0|0] "" X
 SG_ THC_d0001_tempSnsPTIn m0: 8|2@1+ (1,0) [0|0] "" X
 SG_ THC_d0002_tempSnsBatIn m0: 10|2@1+ (1,0) [0|0] "" X
 SG_ THC_d0003_cabinPTCRHeater m0: 12|2@1+ (1,0) [0|0] "" X
 SG_ THC_d0004_pumpPT m0: 14|2@1+ (1,0) [0|0] "" X
 SG_ THC_d0005_pumpBat1 m0: 16|2@1+ (1,0) [0|0] "" X
 SG_ THC_d0006_pumpBat2 m0: 18|2@1+ (1,0) [0|0] "" X
 SG_ THC_d0007_valveRadByp m0: 20|2@1+ (1,0) [0|0] "" X
 SG_ THC_d0008_valveChilByp m0: 22|2@1+ (1,0) [0|0] "" X
 SG_ THC_d0009_valveParallel m0: 24|2@1+ (1,0) [0|0] "" X
 SG_ THC_d0010_compressor m0: 26|2@1+ (1,0) [0|0] "" X
 SG_ THC_d0011_presSnsDis m0: 28|2@1+ (1,0) [0|0] "" X
 SG_ THC_d0012_presSnsSuct m0: 30|2@1+ (1,0) [0|0] "" X
 SG_ THC_d0013_coolantHeater m0: 32|2@1+ (1,0) [0|0] "" X
 SG_ THC_d0014_coolant m0: 34|2@1+ (1,0) [0|0] "" X
 SG_ THC_d0015_cabinPTCHeater m0: 36|2@1+ (1,0) [0|0] "" X
 SG_ THC_d0016_chiller m0: 38|2@1+ (1,0) [0|0] "" X
 SG_ THC_d0017_evaporator m0: 40|2@1+ (1,0) [0|0] "" X
 SG_ THC_d0018_activeAero m0: 42|2@1+ (1,0) [0|0] "" X
 SG_ THC_d0019_RCCMComm m0: 44|2@1+ (1,0) [0|0] "" X
 SG_ THC_d0020_RCCMTempSnsAmb m0: 46|2@1+ (1,0) [0|0] "" X
 SG_ THC_d0021_RCCMActuator m0: 48|2@1+ (1,0) [0|0] "" X
 SG_ THC_d0022_RCCMSensor m0: 50|2@1+ (1,0) [0|0] "" X
 SG_ THC_d0023_THCFailure m0: 52|2@1+ (1,0) [0|0] "" X
 SG_ THC_d0024_refrigSystem m0: 54|2@1+ (1,0) [0|0] "" X
 SG_ THC_d0025_pumpPT2 m0: 56|2@1+ (1,0) [0|0] "" X
 SG_ THC_d0026_hvacIonizer m0: 58|2@1+ (1,0) [0|0] "" X
 SG_ THC_d0027_coolingFan m0: 60|2@1+ (1,0) [0|0] "" X
 SG_ THC_d0028_incarTempSns m0: 62|2@1+ (1,0) [0|0] "" X

BO_ 842 THC_heaterCmd: 1 ETH
 SG_ THC_heaterPWM: 0|8@1+ (0.4,0) [0|0] "%" X

BO_ 1322 THC_hvacStatus: 8 ETH
 SG_ THC_hvacStatusMultiplex M: 0|8@1+ (1,0) [0|0] "" X
 SG_ THC_occupantHeatLoad m0: 8|8@1- (4,0) [0|0] "W/m2" X
 SG_ THC_ptcTargetFeedFwd m0: 16|16@1+ (1,0) [0|0] "W" X
 SG_ THC_ptcTargetPower m0: 32|16@1+ (1,0) [0|0] "W" X
 SG_ THC_leftTargetDischTemp m0: 48|8@1+ (1,0) [0|0] "degC" X
 SG_ THC_rightTargetDischTemp m0: 56|8@1+ (1,0) [0|0] "degC" X
 SG_ THC_rearAirMassTempEst m1: 8|8@1+ (0.5,-40) [0|0] "degC" X
 SG_ THC_qdotLeft m1: 16|16@1- (1,0) [0|0] "W" X
 SG_ THC_qdotRight m1: 32|16@1- (1,0) [0|0] "W" X
 SG_ THC_hvacMdot m1: 48|8@1+ (1,0) [0|0] "g/s" X
 SG_ THC_windshieldTempEst m1: 56|8@1+ (1,-40) [0|0] "degC" X
 SG_ THC_dasHeaterTempEst m2: 8|8@1+ (1,-40) [0|0] "degC" X
 SG_ THC_glassTempEst m2: 16|8@1+ (1,-40) [0|0] "degC" X
 SG_ THC_incarTempSnsEst m2: 24|8@1+ (1,-40) [0|0] "degC" X
 SG_ THC_airMassTempEst m2: 32|11@1+ (0.1,-40) [0|0] "degC" X
 SG_ THC_evapTargetT m2: 43|4@1+ (1,0) [0|0] "degC" X
 SG_ THC_cabinWillOverheat m2: 47|1@1+ (1,0) [0|0] "" X
 SG_ THC_foggingRisk m2: 48|8@1+ (1,0) [0|0] "" X
 SG_ THC_humidityLevel m2: 56|8@1+ (1,0) [0|0] "" X
 SG_ THC_evapFeedForwardWatts m3: 8|8@1+ (32,0) [0|0] "W" X
 SG_ THC_deliveredConvection m3: 16|16@1- (1,0) [0|0] "W/m2" X
 SG_ THC_targetConvection m3: 32|16@1- (1,0) [0|0] "W/m2" X
 SG_ THC_evapFeedbackWatts m3: 48|8@1- (64,0) [0|0] "W" X
 SG_ THC_glassRoofTempEst m3: 56|8@1+ (1,-40) [0|0] "degC" X
 SG_ THC_setTempDeviationActive m4: 8|1@1+ (1,0) [0|0] "" X
 SG_ THC_comfortMdotActive m4: 9|1@1+ (1,0) [0|0] "" X
 SG_ THC_stratificationMdotActive m4: 10|1@1+ (1,0) [0|0] "" X
 SG_ THC_actualSetTempTarget m4: 16|11@1+ (0.1,-40) [0|0] "degC" X
 SG_ THC_modeAdjustedForColdFeet m4: 27|1@1+ (1,0) [0|0] "" X
 SG_ THC_modeAdjustedForPanelHeating m4: 28|1@1+ (1,0) [0|0] "" X
 SG_ THC_incidentAirTemp m4: 29|11@1+ (0.1,-40) [0|0] "degC" X
 SG_ THC_actualSolarLoadEst m4: 40|16@1- (1,0) [0|0] "W/m2" X
 SG_ THC_leftQdotLimited m4: 56|1@1+ (-1,0) [0|0] "" X
 SG_ THC_rightQdotLimited m4: 57|1@1+ (-1,0) [0|0] "" X
 SG_ THC_evapFreezeLimitWatts m4: 58|6@1+ (128,0) [0|0] "W" X

BO_ 1626 THC_info: 8 ETH
 SG_ THC_infoIndex M: 0|8@1+ (1,0) [0|0] "" X
 SG_ THC_infoBuildType m10: 8|8@1+ (1,0) [0|0] "" X
 SG_ THC_infoBuildConfigID m10: 16|16@1+ (1,0) [0|0] "" X
 SG_ THC_infoHardwareID m10: 32|16@1+ (1,0) [0|0] "" X
 SG_ THC_infoComponentID m10: 48|16@1+ (1,0) [0|0] "" X
 SG_ THC_infoPcbaID m11: 16|8@1+ (1,0) [0|0] "" X
 SG_ THC_infoAssemblyID m11: 24|8@1+ (1,0) [0|0] "" X
 SG_ THC_infoUsageID m11: 32|16@1+ (1,0) [0|0] "" X
 SG_ THC_infoSubUsageID m11: 48|16@1+ (1,0) [0|0] "" X
 SG_ THC_infoApplicationCRC m13: 32|32@1+ (1,0) [0|0] "" X
 SG_ THC_infoBootloaderSvnRevision m14: 8|24@1+ (1,0) [0|0] "" X
 SG_ THC_infoAppGitHashBytes m17: 10|54@1+ (4,0) [0|0] "" X
 SG_ THC_infoBootGitHashBytes m18: 10|54@1+ (4,0) [0|0] "" X
 SG_ THC_infoPlatformType m19: 8|8@1+ (1,0) [0|0] "" X
 SG_ THC_infoMajorVersion m19: 16|8@1+ (1,0) [0|0] "" X
 SG_ THC_infoBranchOrigin m19: 24|8@1+ (1,0) [0|0] "" X
 SG_ THC_infoMaturity m19: 32|8@1+ (1,0) [0|0] "" X
 SG_ THC_infoHardwareRevision m19: 40|8@1+ (1,0) [0|0] "" X
 SG_ THC_infoBootLdUdsProtocolVersion m20: 8|8@1+ (1,0) [0|0] "" X
 SG_ THC_infoBootloaderCRC m20: 32|32@1+ (1,0) [0|0] "" X

BO_ 602 THC_limits: 8 ETH
 SG_ THC_limitACManualOff: 49|1@1+ (1,0) [0|0] "" X
 SG_ THC_limitACN: 31|1@1+ (1,0) [0|0] "" X
 SG_ THC_limitACNChillerCtrs: 32|1@1+ (1,0) [0|0] "" X
 SG_ THC_limitBatHeaterBmsNoFlow: 20|1@1+ (1,0) [0|0] "" X
 SG_ THC_limitBatHeaterBmsWorthwhile: 21|1@1+ (1,0) [0|0] "" X
 SG_ THC_limitBatHeaterCoolantRecirc: 36|1@1+ (1,0) [0|0] "" X
 SG_ THC_limitBatHeaterDCDCTmo: 47|1@1+ (1,0) [0|0] "" X
 SG_ THC_limitBatHeaterLowCoolant: 38|1@1+ (1,0) [0|0] "" X
 SG_ THC_limitBatHeaterNoCoolant: 35|1@1+ (1,0) [0|0] "" X
 SG_ THC_limitBatHeaterOvertemp: 19|1@1+ (1,0) [0|0] "" X
 SG_ THC_limitBatHeaterPumps: 16|1@1+ (1,0) [0|0] "" X
 SG_ THC_limitBatHeaterStartBatInDT: 33|1@1+ (1,0) [0|0] "" X
 SG_ THC_limitBatHeaterStartTempChk: 34|1@1+ (1,0) [0|0] "" X
 SG_ THC_limitBatHeaterTempRiseTmo: 14|1@1+ (1,0) [0|0] "" X
 SG_ THC_limitBatHeaterTempSensor: 18|1@1+ (1,0) [0|0] "" X
 SG_ THC_limitBatHeaterThermostat: 15|1@1+ (1,0) [0|0] "" X
 SG_ THC_limitBatHeaterValve: 17|1@1+ (1,0) [0|0] "" X
 SG_ THC_limitBatHeaterValveOS: 29|1@1+ (1,0) [0|0] "" X
 SG_ THC_limitBattHeaterHVPower: 2|1@1+ (1,0) [0|0] "" X
 SG_ THC_limitCPC: 46|1@1+ (1,0) [0|0] "" X
 SG_ THC_limitChilSolPres: 44|1@1+ (1,0) [0|0] "" X
 SG_ THC_limitCompAmbient: 45|1@1+ (1,0) [0|0] "" X
 SG_ THC_limitCompCompFault: 10|1@1+ (1,0) [0|0] "" X
 SG_ THC_limitCompCompTempMax: 9|1@1+ (1,0) [0|0] "" X
 SG_ THC_limitCompCurrentHigh: 43|1@1+ (1,0) [0|0] "" X
 SG_ THC_limitCompDiagAlert: 5|1@1+ (1,0) [0|0] "" X
 SG_ THC_limitCompDischTempHi: 4|1@1+ (1,0) [0|0] "" X
 SG_ THC_limitCompDischTempMax: 8|1@1+ (1,0) [0|0] "" X
 SG_ THC_limitCompInhibited: 13|1@1+ (1,0) [0|0] "" X
 SG_ THC_limitCompPressSenFault: 11|1@1+ (1,0) [0|0] "" X
 SG_ THC_limitCompPressureHi: 3|1@1+ (1,0) [0|0] "" X
 SG_ THC_limitCompPressureMax: 7|1@1+ (1,0) [0|0] "" X
 SG_ THC_limitCompPressureMin: 6|1@1+ (1,0) [0|0] "" X
 SG_ THC_limitCompSolenoidsClosed: 12|1@1+ (1,0) [0|0] "" X
 SG_ THC_limitCompTempSenFault: 37|1@1+ (1,0) [0|0] "" X
 SG_ THC_limitCompVoltageLow: 42|1@1+ (1,0) [0|0] "" X
 SG_ THC_limitCompressorHVPower: 0|1@1+ (1,0) [0|0] "" X
 SG_ THC_limitContactorsOpen: 22|1@1+ (1,0) [0|0] "" X
 SG_ THC_limitEvapDrying: 48|1@1+ (1,0) [0|0] "" X
 SG_ THC_limitEvapThermostat: 50|1@1+ (1,0) [0|0] "" X
 SG_ THC_limitFillRoutineActive: 53|1@1+ (1,0) [0|0] "" X
 SG_ THC_limitHvacGoingDown: 23|1@1+ (1,0) [0|0] "" X
 SG_ THC_limitOilRecirc: 30|1@1+ (1,0) [0|0] "" X
 SG_ THC_limitPtcHeaterHVPower: 1|1@1+ (1,0) [0|0] "" X
 SG_ THC_limitPtcrHeaterHVPower: 51|1@1+ (1,0) [0|0] "" X
 SG_ THC_limitPumpsNoCoolantFill: 39|1@1+ (1,0) [0|0] "" X
 SG_ THC_limitThermalTestActive: 52|1@1+ (1,0) [0|0] "" X
 SG_ THC_limitUDSActive: 27|1@1+ (1,0) [0|0] "" X
 SG_ THC_limitUnused24: 24|1@1+ (1,0) [0|0] "" X
 SG_ THC_limitUnused25: 25|1@1+ (1,0) [0|0] "" X
 SG_ THC_limitUnused26: 26|1@1+ (1,0) [0|0] "" X
 SG_ THC_limitUnused40: 40|1@1+ (1,0) [0|0] "" X
 SG_ THC_limitUnused41: 41|1@1+ (1,0) [0|0] "" X
 SG_ THC_limitUnused54: 54|1@1+ (1,0) [0|0] "" X
 SG_ THC_limitUnused55: 55|1@1+ (1,0) [0|0] "" X
 SG_ THC_limitUnused56: 56|1@1+ (1,0) [0|0] "" X
 SG_ THC_limitUnused57: 57|1@1+ (1,0) [0|0] "" X
 SG_ THC_limitUnused58: 58|1@1+ (1,0) [0|0] "" X
 SG_ THC_limitUnused59: 59|1@1+ (1,0) [0|0] "" X
 SG_ THC_limitUnused60: 60|1@1+ (1,0) [0|0] "" X
 SG_ THC_limitUnused61: 61|1@1+ (1,0) [0|0] "" X
 SG_ THC_limitUnused62: 62|1@1+ (1,0) [0|0] "" X
 SG_ THC_limitUnused63: 63|1@1+ (1,0) [0|0] "" X
 SG_ THC_limitXCPActive: 28|1@1+ (1,0) [0|0] "" X

BO_ 858 THC_power: 8 ETH
 SG_ THC_HVPowerLimit: 48|16@1+ (0.01,0) [0|0] "kW" X
 SG_ THC_limitedBatteryHeater: 44|1@1+ (1,0) [0|0] "" X
 SG_ THC_limitedCompressor: 45|1@1+ (1,0) [0|0] "" X
 SG_ THC_limitedPtcHeater: 46|1@1+ (1,0) [0|0] "" X
 SG_ THC_limitedPtcrHeater: 47|1@1+ (1,0) [0|0] "" X
 SG_ THC_totalPowerConsumed12V: 32|12@1+ (0.001,0) [0|0] "kW" X
 SG_ THC_totalPowerConsumedHV: 16|16@1+ (0.001,0) [0|0] "kW" X

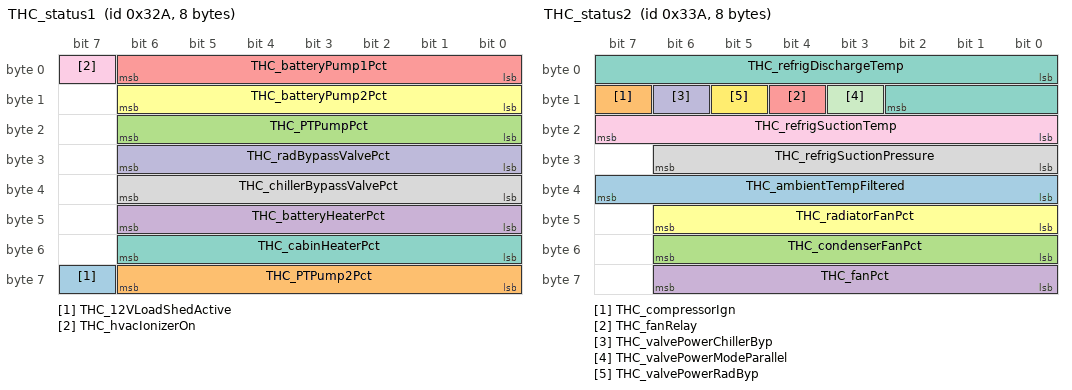
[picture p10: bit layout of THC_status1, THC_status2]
BO_ 810 THC_status1: 8 ETH
 SG_ THC_12VLoadShedActive: 63|1@1+ (1,0) [0|0] "" X
 SG_ THC_PTPump2Pct: 56|7@1+ (1,0) [0|0] "%" X
 SG_ THC_PTPumpPct: 16|7@1+ (1,0) [0|0] "%" X
 SG_ THC_batteryHeaterPct: 40|7@1+ (1,0) [0|0] "%" X
 SG_ THC_batteryPump1Pct: 0|7@1+ (1,0) [0|0] "%" X
 SG_ THC_batteryPump2Pct: 8|7@1+ (1,0) [0|0] "%" X
 SG_ THC_cabinHeaterPct: 48|7@1+ (1,0) [0|0] "%" X
 SG_ THC_chillerBypassValvePct: 32|7@1+ (1,0) [0|0] "%" X
 SG_ THC_hvacIonizerOn: 7|1@1+ (1,0) [0|0] "" X
 SG_ THC_radBypassValvePct: 24|7@1+ (1,0) [0|0] "%" X

BO_ 826 THC_status2: 8 ETH
 SG_ THC_ambientTempFiltered: 32|8@1+ (0.5,-40) [0|0] "degC" X
 SG_ THC_compressorIgn: 15|1@1+ (1,0) [0|0] "" X
 SG_ THC_condenserFanPct: 48|7@1+ (1,0) [0|0] "%" X
 SG_ THC_fanPct: 56|7@1+ (1,0) [0|0] "%" X
 SG_ THC_fanRelay: 12|1@1+ (1,0) [0|0] "" X
 SG_ THC_radiatorFanPct: 40|7@1+ (1,0) [0|0] "%" X
 SG_ THC_refrigDischargeTemp: 0|11@1+ (0.125,-40) [0|0] "degC" X
 SG_ THC_refrigSuctionPressure: 24|7@1+ (0.125,0) [0|0] "bar" X
 SG_ THC_refrigSuctionTemp: 16|8@1+ (0.5,-40) [0|0] "degC" X
 SG_ THC_valvePowerChillerByp: 14|1@1+ (1,0) [0|0] "" X
 SG_ THC_valvePowerModeParallel: 11|1@1+ (1,0) [0|0] "" X
 SG_ THC_valvePowerRadByp: 13|1@1+ (1,0) [0|0] "" X

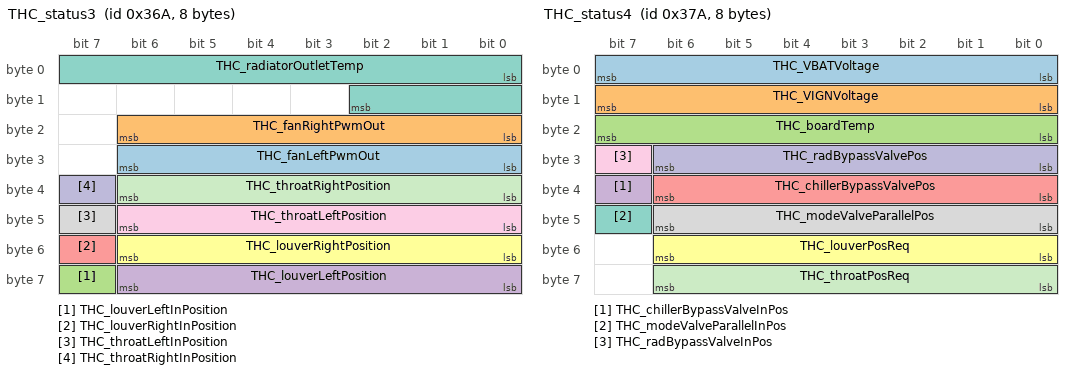
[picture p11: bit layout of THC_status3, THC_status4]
BO_ 874 THC_status3: 8 ETH
 SG_ THC_fanLeftPwmOut: 24|7@1+ (1,0) [0|0] "%" X
 SG_ THC_fanRightPwmOut: 16|7@1+ (1,0) [0|0] "%" X
 SG_ THC_louverLeftInPosition: 63|1@1+ (1,0) [0|0] "" X
 SG_ THC_louverLeftPosition: 56|7@1+ (1,0) [0|0] "%" X
 SG_ THC_louverRightInPosition: 55|1@1+ (1,0) [0|0] "" X
 SG_ THC_louverRightPosition: 48|7@1+ (1,0) [0|0] "%" X
 SG_ THC_radiatorOutletTemp: 0|11@1+ (0.125,-40) [0|0] "degC" X
 SG_ THC_throatLeftInPosition: 47|1@1+ (1,0) [0|0] "" X
 SG_ THC_throatLeftPosition: 40|7@1+ (1,0) [0|0] "%" X
 SG_ THC_throatRightInPosition: 39|1@1+ (1,0) [0|0] "" X
 SG_ THC_throatRightPosition: 32|7@1+ (1,0) [0|0] "%" X

BO_ 890 THC_status4: 8 ETH
 SG_ THC_VBATVoltage: 0|8@1+ (0.1,0) [0|0] "V" X
 SG_ THC_VIGNVoltage: 8|8@1+ (0.1,0) [0|0] "V" X
 SG_ THC_boardTemp: 16|8@1+ (0.5,-40) [0|0] "degC" X
 SG_ THC_chillerBypassValveInPos: 39|1@1+ (1,0) [0|0] "" X
 SG_ THC_chillerBypassValvePos: 32|7@1+ (1,0) [0|0] "%" X
 SG_ THC_louverPosReq: 48|7@1+ (1,0) [0|0] "%" X
 SG_ THC_modeValveParallelInPos: 47|1@1+ (1,0) [0|0] "" X
 SG_ THC_modeValveParallelPos: 40|7@1+ (1,0) [0|0] "%" X
 SG_ THC_radBypassValveInPos: 31|1@1+ (1,0) [0|0] "" X
 SG_ THC_radBypassValvePos: 24|7@1+ (1,0) [0|0] "%" X
 SG_ THC_throatPosReq: 56|7@1+ (1,0) [0|0] "%" X

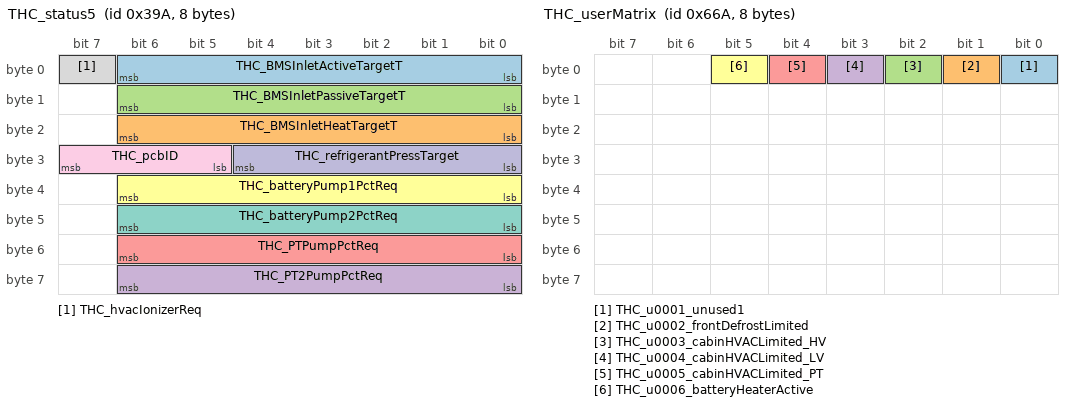
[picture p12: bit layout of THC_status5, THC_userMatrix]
BO_ 922 THC_status5: 8 ETH
 SG_ THC_BMSInletActiveTargetT: 0|7@1+ (1,0) [0|0] "degC" X
 SG_ THC_BMSInletHeatTargetT: 16|7@1+ (1,-40) [0|0] "degC" X
 SG_ THC_BMSInletPassiveTargetT: 8|7@1+ (1,-20) [0|0] "degC" X
 SG_ THC_PT2PumpPctReq: 56|7@1+ (1,0) [0|0] "%" X
 SG_ THC_PTPumpPctReq: 48|7@1+ (1,0) [0|0] "%" X
 SG_ THC_batteryPump1PctReq: 32|7@1+ (1,0) [0|0] "%" X
 SG_ THC_batteryPump2PctReq: 40|7@1+ (1,0) [0|0] "%" X
 SG_ THC_hvacIonizerReq: 7|1@1+ (1,0) [0|0] "" X
 SG_ THC_pcbID: 29|3@1+ (1,0) [0|0] "" X
 SG_ THC_refrigerantPressTarget: 24|5@1+ (0.5,12) [0|0] "bar" X

BO_ 1562 THC_udsResponse: 8 ETH
 SG_ THC_udsResponseData_H: 0|32@0+ (1,0) [0|0] "" X
 SG_ THC_udsResponseData_L: 32|32@0+ (1,0) [0|0] "" X

BO_ 1642 THC_userMatrix: 8 ETH
 SG_ THC_u0001_unused1: 0|1@1+ (1,0) [0|0] "" X
 SG_ THC_u0002_frontDefrostLimited: 1|1@1+ (1,0) [0|0] "" X
 SG_ THC_u0003_cabinHVACLimited_HV: 2|1@1+ (1,0) [0|0] "" X
 SG_ THC_u0004_cabinHVACLimited_LV: 3|1@1+ (1,0) [0|0] "" X
 SG_ THC_u0005_cabinHVACLimited_PT: 4|1@1+ (1,0) [0|0] "" X
 SG_ THC_u0006_batteryHeaterActive: 5|1@1+ (1,0) [0|0] "" X

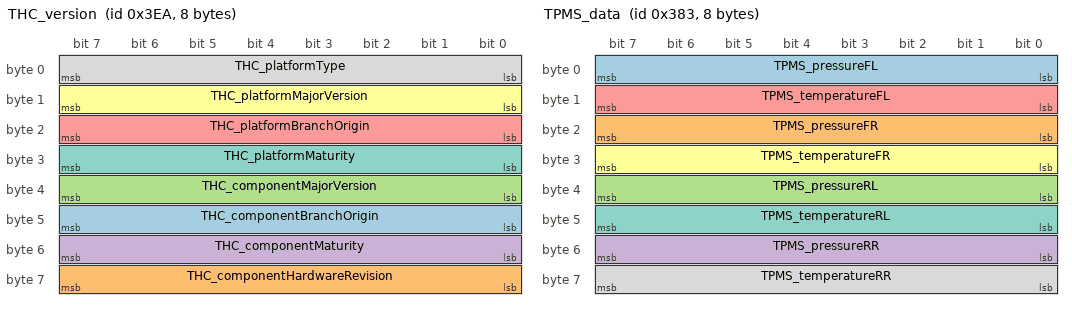
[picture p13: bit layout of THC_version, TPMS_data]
BO_ 1002 THC_version: 8 ETH
 SG_ THC_componentBranchOrigin: 40|8@1+ (1,0) [0|0] "" X
 SG_ THC_componentHardwareRevision: 56|8@1+ (1,0) [0|0] "" X
 SG_ THC_componentMajorVersion: 32|8@1+ (1,0) [0|0] "" X
 SG_ THC_componentMaturity: 48|8@1+ (1,0) [0|0] "" X
 SG_ THC_platformBranchOrigin: 16|8@1+ (1,0) [0|0] "" X
 SG_ THC_platformMajorVersion: 8|8@1+ (1,0) [0|0] "" X
 SG_ THC_platformMaturity: 24|8@1+ (1,0) [0|0] "" X
 SG_ THC_platformType: 0|8@1+ (1,0) [0|0] "" X

BO_ 2029 TOOL_forcedOutputs: 8 ETH
 SG_ TOOL_forceEasOn: 0|1@1+ (1,0) [0|0] "" X
 SG_ TOOL_homelinkCountry: 1|4@1+ (1,0) [0|0] "" X

BO_ 2030 TOOL_log: 4 ETH
 SG_ TOOL_enum: 0|32@0+ (1,0) [0|0] "" X

BO_ 2031 TOOL_note: 4 ETH
 SG_ TOOL_ascii: 0|32@0+ (1,0) [0|0] "" X

BO_ 132 TPMS_StatusC: 8 ETH
 SG_ TPMS_WA_version: 3|1@1+ (1,0) [0|0] "" X
 SG_ TPMS_c_globalHardWarning: 0|1@1+ (1,0) [0|0] "" X
 SG_ TPMS_c_globalSoftWarning: 1|1@1+ (1,0) [0|0] "" X
 SG_ TPMS_c_sensorBatteryLowFL: 32|1@1+ (1,0) [0|0] "" X
 SG_ TPMS_c_sensorBatteryLowFR: 33|1@1+ (1,0) [0|0] "" X
 SG_ TPMS_c_sensorBatteryLowRL: 34|1@1+ (1,0) [0|0] "" X
 SG_ TPMS_c_sensorBatteryLowRR: 35|1@1+ (1,0) [0|0] "" X
 SG_ TPMS_deltaPressWarningFL: 20|1@1+ (1,0) [0|0] "" X
 SG_ TPMS_deltaPressWarningFR: 21|1@1+ (1,0) [0|0] "" X
 SG_ TPMS_deltaPressWarningRL: 22|1@1+ (1,0) [0|0] "" X
 SG_ TPMS_deltaPressWarningRR: 23|1@1+ (1,0) [0|0] "" X
 SG_ TPMS_ecuOverVoltage: 41|1@1+ (1,0) [0|0] "" X
 SG_ TPMS_ecuRamRomNvMFail: 42|1@1+ (1,0) [0|0] "" X
 SG_ TPMS_ecuUnderVoltage: 40|1@1+ (1,0) [0|0] "" X
 SG_ TPMS_eolNotCompleted: 47|1@1+ (1,0) [0|0] "" X
 SG_ TPMS_externalTemperatureFail: 46|1@1+ (1,0) [0|0] "" X
 SG_ TPMS_globalDeltaPressure: 4|1@1+ (1,0) [0|0] "" X
 SG_ TPMS_hardWarningFL: 15|1@1+ (1,0) [0|0] "" X
 SG_ TPMS_hardWarningFR: 13|1@1+ (1,0) [0|0] "" X
 SG_ TPMS_hardWarningRL: 11|1@1+ (1,0) [0|0] "" X
 SG_ TPMS_hardWarningRR: 9|1@1+ (1,0) [0|0] "" X
 SG_ TPMS_learningStatus: 16|2@1+ (1,0) [0|0] "" X
 SG_ TPMS_localisationStatus: 18|2@1+ (1,0) [0|0] "" X
 SG_ TPMS_newSensorLearnt: 5|1@1+ (1,0) [0|0] "" X
 SG_ TPMS_rcpFront: 48|8@1+ (0.025,0) [0|0] "bar" X
 SG_ TPMS_rcpRear: 56|8@1+ (0.025,0) [0|0] "bar" X
 SG_ TPMS_rfReceiverFail: 43|1@1+ (1,0) [0|0] "" X
 SG_ TPMS_sensorDefectiveFL: 36|1@1+ (1,0) [0|0] "" X
 SG_ TPMS_sensorDefectiveFR: 37|1@1+ (1,0) [0|0] "" X
 SG_ TPMS_sensorDefectiveRL: 38|1@1+ (1,0) [0|0] "" X
 SG_ TPMS_sensorDefectiveRR: 39|1@1+ (1,0) [0|0] "" X
 SG_ TPMS_sensorNoResponseFL: 24|1@1+ (1,0) [0|0] "" X
 SG_ TPMS_sensorNoResponseFR: 25|1@1+ (1,0) [0|0] "" X
 SG_ TPMS_sensorNoResponseRL: 26|1@1+ (1,0) [0|0] "" X
 SG_ TPMS_sensorNoResponseRR: 27|1@1+ (1,0) [0|0] "" X
 SG_ TPMS_sensorThermShutdownFL: 28|1@1+ (1,0) [0|0] "" X
 SG_ TPMS_sensorThermShutdownFR: 29|1@1+ (1,0) [0|0] "" X
 SG_ TPMS_sensorThermShutdownRL: 30|1@1+ (1,0) [0|0] "" X
 SG_ TPMS_sensorThermShutdownRR: 31|1@1+ (1,0) [0|0] "" X
 SG_ TPMS_softWarningFL: 14|1@1+ (1,0) [0|0] "" X
 SG_ TPMS_softWarningFR: 12|1@1+ (1,0) [0|0] "" X
 SG_ TPMS_softWarningRL: 10|1@1+ (1,0) [0|0] "" X
 SG_ TPMS_softWarningRR: 8|1@1+ (1,0) [0|0] "" X
 SG_ TPMS_systemMalfunction: 2|1@1+ (1,0) [0|0] "" X
 SG_ TPMS_vehicleSpeedFail: 45|1@1+ (1,0) [0|0] "" X
 SG_ TPMS_wheelPulseMissing: 44|1@1+ (1,0) [0|0] "" X

BO_ 123 TPMS_antennaStatus: 8 ETH
 SG_ TPMS_IDWriteErrorFlag: 8|1@1+ (1,0) [0|0] "" X
 SG_ TPMS_autoLearnDebugInfo: 11|1@1+ (1,0) [0|0] "" X
 SG_ TPMS_autoLearnFinishedFlag: 6|1@1+ (1,0) [0|0] "" X
 SG_ TPMS_errorRSSI: 14|1@1+ (1,0) [0|0] "" X
 SG_ TPMS_modeInfoTPMS: 9|1@1+ (1,0) [0|0] "" X
 SG_ TPMS_noResponseTimeoutFL: 32|8@1+ (1,0) [0|0] "" X
 SG_ TPMS_noResponseTimeoutFR: 40|8@1+ (1,0) [0|0] "" X
 SG_ TPMS_noResponseTimeoutRL: 48|8@1+ (1,0) [0|0] "" X
 SG_ TPMS_noResponseTimeoutRR: 56|8@1+ (1,0) [0|0] "" X
 SG_ TPMS_requiredAutoLearnResult: 7|1@1+ (1,0) [0|0] "" X
 SG_ TPMS_sideInformationError: 15|1@1+ (1,0) [0|0] "" X
 SG_ TPMS_speedUpTimeout: 24|8@1+ (1,0) [0|0] "" X
 SG_ TPMS_startUpTimeout: 16|8@1+ (1,0) [0|0] "" X
 SG_ TPMS_startupFlagFL: 3|1@1+ (1,0) [0|0] "" X
 SG_ TPMS_startupFlagFR: 2|1@1+ (1,0) [0|0] "" X
 SG_ TPMS_startupFlagRL: 1|1@1+ (1,0) [0|0] "" X
 SG_ TPMS_startupFlagRR: 0|1@1+ (1,0) [0|0] "" X
 SG_ TPMS_startupFlagTPMS: 4|1@1+ (1,0) [0|0] "" X
 SG_ TPMS_wheelSizeInfo: 10|1@1+ (1,0) [0|0] "" X

BO_ 899 TPMS_data: 8 ETH
 SG_ TPMS_pressureFL: 0|8@1+ (0.025,0) [0|0] "bar" X
 SG_ TPMS_pressureFR: 16|8@1+ (0.025,0) [0|0] "bar" X
 SG_ TPMS_pressureRL: 32|8@1+ (0.025,0) [0|0] "bar" X
 SG_ TPMS_pressureRR: 48|8@1+ (0.025,0) [0|0] "bar" X
 SG_ TPMS_temperatureFL: 8|8@1+ (1,-40) [0|0] "C" X
 SG_ TPMS_temperatureFR: 24|8@1+ (1,-40) [0|0] "C" X
 SG_ TPMS_temperatureRL: 40|8@1+ (1,-40) [0|0] "C" X
 SG_ TPMS_temperatureRR: 56|8@1+ (1,-40) [0|0] "C" X

BO_ 927 TPMS_status: 8 ETH
 SG_ TPMS_IDLearnActiveByPwrON: 61|1@1+ (1,0) [0|0] "" X
 SG_ TPMS_autoLearnRequired: 63|1@1+ (1,0) [0|0] "" X
 SG_ TPMS_autoLearnResult: 59|1@1+ (1,0) [0|0] "" X
 SG_ TPMS_autoLocationRequired: 62|1@1+ (1,0) [0|0] "" X
 SG_ TPMS_autoLocationResult: 60|1@1+ (1,0) [0|0] "" X
 SG_ TPMS_batteryVoltageHigh: 17|1@1+ (1,0) [0|0] "" X
 SG_ TPMS_batteryVoltageLow: 16|1@1+ (1,0) [0|0] "" X
 SG_ TPMS_carMovingFlag: 48|1@1+ (1,0) [0|0] "" X
 SG_ TPMS_checkingInProgress: 56|1@1+ (1,0) [0|0] "" X
 SG_ TPMS_circuitVoltageHigh: 19|1@1+ (1,0) [0|0] "" X
 SG_ TPMS_circuitVoltageLow: 18|1@1+ (1,0) [0|0] "" X
 SG_ TPMS_dataRxCANError: 53|1@1+ (1,0) [0|0] "" X
 SG_ TPMS_globalDeltaPressureWarning: 5|1@1+ (1,0) [0|0] "" X
 SG_ TPMS_globalHardWarning: 0|1@1+ (1,0) [0|0] "" X
 SG_ TPMS_globalLowPresWarning: 4|1@1+ (1,0) [0|0] "" X
 SG_ TPMS_globalOverPresWarning: 3|1@1+ (1,0) [0|0] "" X
 SG_ TPMS_globalRunFlatWarning: 7|1@1+ (1,0) [0|0] "" X
 SG_ TPMS_globalSoftWarning: 1|1@1+ (1,0) [0|0] "" X
 SG_ TPMS_globalTireTempWarning: 6|1@1+ (1,0) [0|0] "" X
 SG_ TPMS_globalVMaxPresWarning: 2|1@1+ (1,0) [0|0] "" X
 SG_ TPMS_learningInProgress: 57|1@1+ (1,0) [0|0] "" X
 SG_ TPMS_lowPressHiSpeedMode: 54|1@1+ (1,0) [0|0] "" X
 SG_ TPMS_noDataRxCANError: 52|1@1+ (1,0) [0|0] "" X
 SG_ TPMS_noPingReponseFL: 24|1@1+ (1,0) [0|0] "" X
 SG_ TPMS_noPingResponseFR: 25|1@1+ (1,0) [0|0] "" X
 SG_ TPMS_noPingResponseRL: 26|1@1+ (1,0) [0|0] "" X
 SG_ TPMS_noPingResponseRR: 27|1@1+ (1,0) [0|0] "" X
 SG_ TPMS_overTempPSU: 51|1@1+ (1,0) [0|0] "" X
 SG_ TPMS_overflowPressureFL: 40|1@1+ (1,0) [0|0] "" X
 SG_ TPMS_overflowPressureFR: 41|1@1+ (1,0) [0|0] "" X
 SG_ TPMS_overflowPressureRL: 42|1@1+ (1,0) [0|0] "" X
 SG_ TPMS_overflowPressureRR: 43|1@1+ (1,0) [0|0] "" X
 SG_ TPMS_referenceVoltageHigh: 21|1@1+ (1,0) [0|0] "" X
 SG_ TPMS_referenceVoltageLow: 20|1@1+ (1,0) [0|0] "" X
 SG_ TPMS_sensorBatteryLowFL: 32|1@1+ (1,0) [0|0] "" X
 SG_ TPMS_sensorBatteryLowFR: 33|1@1+ (1,0) [0|0] "" X
 SG_ TPMS_sensorBatteryLowRL: 34|1@1+ (1,0) [0|0] "" X
 SG_ TPMS_sensorBatteryLowRR: 35|1@1+ (1,0) [0|0] "" X
 SG_ TPMS_sensorInfoErrorFL: 36|1@1+ (1,0) [0|0] "" X
 SG_ TPMS_sensorInfoErrorFR: 37|1@1+ (1,0) [0|0] "" X
 SG_ TPMS_sensorInfoErrorRL: 38|1@1+ (1,0) [0|0] "" X
 SG_ TPMS_sensorInfoErrorRR: 39|1@1+ (1,0) [0|0] "" X
 SG_ TPMS_sensorTempWarnFlagFL: 44|1@1+ (1,0) [0|0] "" X
 SG_ TPMS_sensorTempWarnFlagFR: 45|1@1+ (1,0) [0|0] "" X
 SG_ TPMS_sensorTempWarnFlagRL: 46|1@1+ (1,0) [0|0] "" X
 SG_ TPMS_sensorTempWarnFlagRR: 47|1@1+ (1,0) [0|0] "" X
 SG_ TPMS_statusLearned: 58|1@1+ (1,0) [0|0] "" X
 SG_ TPMS_systemFault: 49|1@1+ (1,0) [0|0] "" X
 SG_ TPMS_unableToLearnFL: 28|1@1+ (1,0) [0|0] "" X
 SG_ TPMS_unableToLearnFR: 29|1@1+ (1,0) [0|0] "" X
 SG_ TPMS_unableToLearnRL: 30|1@1+ (1,0) [0|0] "" X
 SG_ TPMS_unableToLearnRR: 31|1@1+ (1,0) [0|0] "" X

BO_ 1631 TPMS_udsResponse: 8 ETH
 SG_ TPMS_udsResponseData: 0|54@0+ (1024,0) [0|0] "" X

BO_ 911 TUNER_DisplayInfo: 2 ETH
 SG_ TUNER_displayLength: 8|8@1+ (1,0) [0|0] "" X
 SG_ TUNER_displayType: 0|8@1+ (1,0) [0|0] "" X

BO_ 937 TUNER_ErrorData: 8 ETH
 SG_ TUNER_errorData: 0|54@0+ (1024,0) [0|0] "" X

BO_ 815 TUNER_MasterArbitration: 1 ETH
 SG_ TUNER_abitrationCommand: 0|8@1+ (1,0) [0|0] "" X

BO_ 783 TUNER_NodeStatus: 1 ETH
 SG_ TUNER_nodeStatusByte0: 0|8@1+ (1,0) [0|0] "" X

BO_ 936 TUNER_RemoteReceiverControl: 8 ETH
 SG_ TUNER_controlCommand M: 0|8@1+ (1,0) [0|0] "" X
 SG_ TUNER_paramSelectBand m1: 8|8@1+ (1,0) [0|0] "" X
 SG_ TUNER_paramCancelInterrupt m2: 8|8@1+ (1,0) [0|0] "" X
 SG_ TUNER_paramMuteControl m4: 8|8@1+ (1,0) [0|0] "" X
 SG_ TUNER_paramConfigureRegion m5: 8|8@1+ (1,0) [0|0] "" X
 SG_ TUNER_paramConfigureRegionPD m5: 16|8@1+ (1,0) [0|0] "" X
 SG_ TUNER_paramRequestErrorStatus m6: 8|8@1+ (1,0) [0|0] "" X
 SG_ TUNER_paramAMFMHDDirectTuneBy m16: 8|8@1+ (1,0) [0|0] "" X
 SG_ TUNER_paramAMFMHDDirectTuneTo m16: 16|16@0+ (1,0) [0|0] "" X
 SG_ TUNER_paramAMFMHDTuneMultiPIMSB m16: 32|8@1+ (1,0) [0|0] "" X
 SG_ TUNER_paramAMFMHDTunePILSB m16: 40|8@1+ (1,0) [0|0] "" X
 SG_ TUNER_paramAMFMHDTuneUpDown m17: 8|8@1+ (1,0) [0|0] "" X
 SG_ TUNER_paramAMFMHDSeekUpDown m19: 8|8@1+ (1,0) [0|0] "" X
 SG_ TUNER_paramAMFMHDScanUpDown m20: 8|8@1+ (1,0) [0|0] "" X
 SG_ TUNER_paramAMFMHDPtySeek m21: 8|8@1+ (1,0) [0|0] "" X
 SG_ TUNER_paramAMFMHDPtyScan m22: 8|8@1+ (1,0) [0|0] "" X
 SG_ TUNER_paramAMFMHDPtyGroupSelect m23: 8|8@1+ (1,0) [0|0] "" X
 SG_ TUNER_paramAMFMHDPtyGroupCode m23: 16|8@1+ (1,0) [0|0] "" X
 SG_ TUNER_paramRDSSettings m26: 8|8@1+ (1,0) [0|0] "" X
 SG_ TUNER_paramHDSettings m27: 8|8@1+ (1,0) [0|0] "" X
 SG_ TUNER_hdChanges m27: 16|8@1+ (1,0) [0|0] "" X
 SG_ TUNER_paramXMDirectTuneBy m32: 8|8@1+ (1,0) [0|0] "" X
 SG_ TUNER_paramXMDirTuneChanOrSIDMSB m32: 16|8@1+ (1,0) [0|0] "" X
 SG_ TUNER_paramXMDirTuneToSIDLSB m32: 24|8@1+ (1,0) [0|0] "" X
 SG_ TUNER_paramXMTuneUpDown m33: 8|8@1+ (1,0) [0|0] "" X
 SG_ TUNER_paramXMFastUpDown m34: 8|8@1+ (1,0) [0|0] "" X
 SG_ TUNER_paramXMSeekUpDown m35: 8|8@1+ (1,0) [0|0] "" X
 SG_ TUNER_paramXMScanUpDown m36: 8|8@1+ (1,0) [0|0] "" X
 SG_ TUNER_paramXMCategoryUpDown m39: 8|8@1+ (1,0) [0|0] "" X
 SG_ TUNER_paramXMCatSearchUpDown m40: 8|8@1+ (1,0) [0|0] "" X
 SG_ TUNER_paramXMDiagnosisMode m44: 8|8@1+ (1,0) [0|0] "" X
 SG_ MCU_tunerXmDiagDispMode m44: 16|8@1+ (1,0) [0|0] "" X
 SG_ MCU_tunerXmDiagDispSubMode m44: 24|8@1+ (1,0) [0|0] "" X
 SG_ TUNER_paramXMExtDiagnosisMode m45: 8|8@1+ (1,0) [0|0] "" X
 SG_ TUNER_paramDABDirectTuneBy m48: 8|8@1+ (1,0) [0|0] "" X
 SG_ TUNER_paramDABDirectTuneChannel m48: 16|8@1+ (1,0) [0|0] "" X
 SG_ TUNER_paramDABDirectTuneEID m48: 24|16@0+ (1,0) [0|0] "" X
 SG_ TUNER_paramDABDirectTuneSID m48: 40|16@0+ (1,0) [0|0] "" X
 SG_ TUNER_paramDABDirectTuneCID m48: 56|8@1+ (1,0) [0|0] "" X
 SG_ TUNER_paramDABTuneUpDown m49: 8|8@1+ (1,0) [0|0] "" X
 SG_ TUNER_paramDABSeekUpDown m51: 8|8@1+ (1,0) [0|0] "" X
 SG_ TUNER_paramDABScanUpDown m52: 8|8@1+ (1,0) [0|0] "" X
 SG_ TUNER_paramDABPtySeek m53: 8|8@1+ (1,0) [0|0] "" X
 SG_ TUNER_paramDABPtyScan m54: 8|8@1+ (1,0) [0|0] "" X
 SG_ TUNER_paramDABPtyGroupSelect m55: 8|8@1+ (1,0) [0|0] "" X
 SG_ TUNER_paramDABSettings m58: 8|8@1+ (1,0) [0|0] "" X
 SG_ TUNER_paramDABMakeStationList m62: 8|8@1+ (1,0) [0|0] "" X

BO_ 895 TUNER_RemoteReceiverExtStatus: 8 ETH
 SG_ TUNER_receiverExtStatusType M: 0|8@1+ (1,0) [0|0] "" X
 SG_ TUNER_receiverStatusFMPI m0: 8|16@0+ (1,0) [0|0] "" X
 SG_ TUNER_receiverStatusFMPrgType m0: 24|8@1+ (1,0) [0|0] "" X
 SG_ TUNER_receiverStatusFMPrgTypeGrp m0: 32|8@1+ (1,0) [0|0] "" X
 SG_ TUNER_receiverStatusHDPrgType m1: 8|8@1+ (1,0) [0|0] "" X
 SG_ TUNER_receiverStatusHDPrgTypeGrp m1: 16|8@1+ (1,0) [0|0] "" X
 SG_ TUNER_receiverStatusXMServiceID m2: 8|16@0+ (1,0) [0|0] "" X
 SG_ TUNER_receiverStatusDABSID m3: 8|32@0+ (1,0) [0|0] "" X
 SG_ TUNER_receiverStatusDABPrgType m3: 40|8@1+ (1,0) [0|0] "" X
 SG_ TUNER_receiverStatusDABEID m3: 48|16@0+ (1,0) [0|0] "" X

BO_ 863 TUNER_RemoteReceiverResponse: 2 ETH
 SG_ TUNER_cmdResponseEcho: 0|8@1+ (1,0) [0|0] "" X
 SG_ TUNER_cmdResponseStatus: 8|8@1+ (1,0) [0|0] "" X

BO_ 879 TUNER_RemoteReceiverStatus: 8 ETH
 SG_ TUNER_dspMute: 4|4@1+ (1,0) [0|0] "" X
 SG_ TUNER_receiverStatusBand: 0|4@1+ (1,0) [0|0] "" X
 SG_ TUNER_receiverStatusFrequency: 16|24@0+ (1,0) [0|0] "" X
 SG_ TUNER_receiverStatusIndicator: 40|16@0+ (1,0) [0|0] "" X
 SG_ TUNER_receiverStatusLevel: 56|8@1+ (1,0) [0|0] "" X
 SG_ TUNER_receiverStatusStatus: 8|8@1+ (1,0) [0|0] "" X

BO_ 904 TUNER_RequestStatus: 1 ETH
 SG_ TUNER_requestStatusType: 0|8@1+ (1,0) [0|0] "" X

BO_ 920 TUNER_RequestTextData: 3 ETH
 SG_ TUNER_requestTextSubID: 8|16@0+ (1,0) [0|0] "" X
 SG_ TUNER_requestTextTextID: 0|8@1+ (1,0) [0|0] "" X

BO_ 831 TUNER_SourceStatus: 1 ETH
 SG_ TUNER_audioSourceStatus: 0|8@1+ (1,0) [0|0] "" X

BO_ 767 TUNER_TextData: 8 ETH
 SG_ TUNER_textData: 10|54@1+ (1024,0) [0|0] "" X

BO_ 1695 TUNER_udsResponse: 8 ETH
 SG_ TUNER_udsResponseData: 0|54@0+ (1024,0) [0|0] "" X

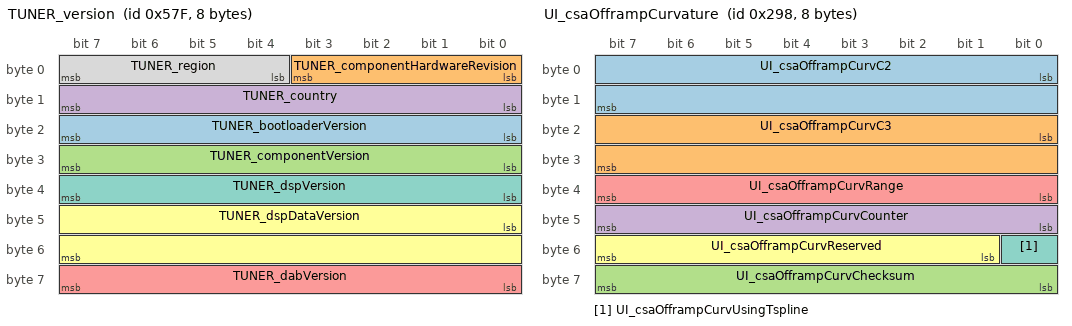
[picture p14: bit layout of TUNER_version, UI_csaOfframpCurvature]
BO_ 1407 TUNER_version: 8 ETH
 SG_ TUNER_bootloaderVersion: 16|8@1+ (1,0) [0|0] "" X
 SG_ TUNER_componentHardwareRevision: 0|4@1+ (1,0) [0|0] "" X
 SG_ TUNER_componentVersion: 24|8@1+ (1,0) [0|0] "" X
 SG_ TUNER_country: 8|8@1+ (1,0) [0|0] "" X
 SG_ TUNER_dabVersion: 56|8@1+ (1,0) [0|0] "" X
 SG_ TUNER_dspDataVersion: 40|16@1+ (1,0) [0|0] "" X
 SG_ TUNER_dspVersion: 32|8@1+ (1,0) [0|0] "" X
 SG_ TUNER_region: 4|4@1+ (1,0) [0|0] "" X

BO_ 1423 TUNER_version1: 8 ETH
 SG_ TUNER_HDVersion: 0|16@1+ (1,0) [0|0] "" X

BO_ 1679 UDS_tunerRequest: 8 ETH
 SG_ UDS_tunerRequestData: 0|54@0+ (1024,0) [0|0] "" X

BO_ 1006 UI_autopilotControl: 8 ETH
 SG_ UI_autopilotControlIndex M: 0|3@1+ (1,0) [0|0] "" X
 SG_ UI_hovEnabled m0: 3|1@1+ (1,0) [0|0] "" X
 SG_ UI_donDisableAutoWiperDuration m0: 4|3@1+ (1,0) [0|0] "" X
 SG_ UI_donDisableOnAutoWiperSpeed m0: 7|4@1+ (1,0) [0|0] "" X
 SG_ UI_blindspotMinSpeed m0: 11|4@1+ (1,0) [0|0] "" X
 SG_ UI_blindspotDistance m0: 15|3@1+ (1,0) [0|0] "" X
 SG_ UI_blindspotTTC m0: 18|3@1+ (1,0) [0|0] "" X
 SG_ UI_donStopEndOfRampBuffer m0: 21|3@1+ (1,0) [0|0] "" X
 SG_ UI_donDisableCutin m0: 24|1@1+ (1,0) [0|0] "" X
 SG_ UI_donMinGoreWidthForAbortMap m0: 25|4@1+ (1,0) [0|0] "" X
 SG_ UI_donAlcProgGoreAbortThres m0: 29|4@1+ (1,0) [0|0] "" X
 SG_ UI_donMinGoreWidthForAbortNotMap m0: 33|4@1+ (1,0) [0|0] "" X
 SG_ UI_alcDisableUltrasonicCheck m0: 37|1@1+ (1,0) [0|0] "" X
 SG_ UI_alcUltrasonicDistance m0: 38|4@1+ (1,0) [0|0] "" X
 SG_ UI_alcUltrasonicWaitTime m0: 42|3@1+ (1,0) [0|0] "" X
 SG_ UI_alcEgoLeadingReactionAccel m0: 48|2@1+ (1,0) [0|0] "" X
 SG_ UI_alcMergIntervalRearDHyst m0: 50|2@1+ (1,0) [0|0] "" X
 SG_ UI_alcMergingIntervalHeadwayHyst m0: 52|2@1+ (1,0) [0|0] "" X
 SG_ UI_alcAssertivenessRate m0: 54|2@1+ (1,0) [0|0] "" X
 SG_ UI_alcViewRangeSensitivity m0: 56|2@1+ (1,0) [0|0] "" X
 SG_ UI_camBlockLaneCheckDisable m1: 3|1@1+ (1,0) [0|0] "" X
 SG_ UI_camBlockLaneCheckThreshold m1: 4|6@1+ (0.01587,0) [0|0] "%" X
 SG_ UI_camBlockBlurDisable m1: 10|1@1+ (1,0) [0|0] "" X
 SG_ UI_camBlockBlurThreshold m1: 11|6@1+ (0.01587,0) [0|0] "%" X
 SG_ UI_stopAndGo m1: 17|1@1+ (1,0) [0|0] "" X

BO_ 664 UI_csaOfframpCurvature: 8 ETH
 SG_ UI_csaOfframpCurvC2: 0|16@1- (1e-06,0) [0|0] "1/m" X
 SG_ UI_csaOfframpCurvC3: 16|16@1- (4e-09,0) [0|0] "1/m2" X
 SG_ UI_csaOfframpCurvChecksum: 56|8@1+ (1,0) [0|0] "" X
 SG_ UI_csaOfframpCurvCounter: 40|8@1+ (1,0) [0|0] "" X
 SG_ UI_csaOfframpCurvRange: 32|8@1+ (2,0) [0|0] "m" X
 SG_ UI_csaOfframpCurvReserved: 49|7@1+ (1,0) [0|0] "" X
 SG_ UI_csaOfframpCurvUsingTspline: 48|1@1+ (1,0) [0|0] "" X

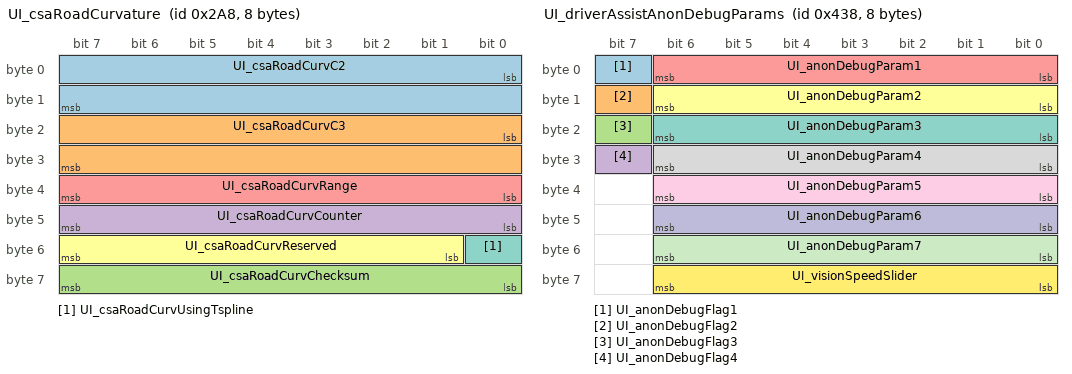
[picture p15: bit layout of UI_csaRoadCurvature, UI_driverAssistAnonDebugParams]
BO_ 680 UI_csaRoadCurvature: 8 ETH
 SG_ UI_csaRoadCurvC2: 0|16@1- (1e-06,0) [0|0] "1/m" X
 SG_ UI_csaRoadCurvC3: 16|16@1- (4e-09,0) [0|0] "1/m2" X
 SG_ UI_csaRoadCurvChecksum: 56|8@1+ (1,0) [0|0] "" X
 SG_ UI_csaRoadCurvCounter: 40|8@1+ (1,0) [0|0] "" X
 SG_ UI_csaRoadCurvRange: 32|8@1+ (2,0) [0|0] "m" X
 SG_ UI_csaRoadCurvReserved: 49|7@1+ (1,0) [0|0] "" X
 SG_ UI_csaRoadCurvUsingTspline: 48|1@1+ (1,0) [0|0] "" X

BO_ 1080 UI_driverAssistAnonDebugParams: 8 ETH
 SG_ UI_anonDebugFlag1: 7|1@1+ (1,0) [0|0] "" X
 SG_ UI_anonDebugFlag2: 15|1@1+ (1,0) [0|0] "" X
 SG_ UI_anonDebugFlag3: 23|1@1+ (1,0) [0|0] "" X
 SG_ UI_anonDebugFlag4: 31|1@1+ (1,0) [0|0] "" X
 SG_ UI_anonDebugParam1: 0|7@1+ (1,0) [0|0] "" X
 SG_ UI_anonDebugParam2: 8|7@1+ (1,0) [0|0] "" X
 SG_ UI_anonDebugParam3: 16|7@1+ (1,0) [0|0] "" X
 SG_ UI_anonDebugParam4: 24|7@1+ (1,0) [0|0] "" X
 SG_ UI_anonDebugParam5: 32|7@1+ (1,0) [0|0] "" X
 SG_ UI_anonDebugParam6: 40|7@1+ (1,0) [0|0] "" X
 SG_ UI_anonDebugParam7: 48|7@1+ (1,0) [0|0] "" X
 SG_ UI_visionSpeedSlider: 56|7@1+ (1,0) [0|0] "" X

BO_ 1000 UI_driverAssistControl: 8 ETH
 SG_ UI_accFromZero: 53|1@1+ (1,0) [0|0] "" X
 SG_ UI_adaptiveSetSpeedEnable: 39|1@1+ (1,0) [0|0] "" X
 SG_ UI_alcOffHighwayEnable: 54|1@1+ (1,0) [0|0] "" X
 SG_ UI_autoSummonEnable: 10|1@1+ (1,0) [0|0] "" X
 SG_ UI_autopilotAlwaysOn: 52|1@1+ (1,0) [0|0] "" X
 SG_ UI_autopilotControlRequest: 0|1@1+ (1,0) [0|0] "" X
 SG_ UI_coastToCoast: 9|1@1+ (1,0) [0|0] "" X
 SG_ UI_curvSpeedAdaptDisable: 4|1@1+ (1,0) [0|0] "" X
 SG_ UI_curvatureDatabaseOnly: 22|1@1+ (1,0) [0|0] "" X
 SG_ UI_dasDeveloper: 5|1@1+ (1,0) [0|0] "" X
 SG_ UI_driveOnMapsEnable: 13|1@1+ (1,0) [0|0] "" X
 SG_ UI_drivingSide: 40|2@1+ (1,0) [0|0] "" X
 SG_ UI_enableClipTelemetry: 42|1@1+ (1,0) [0|0] "" X
 SG_ UI_enableCutinExperiments: 58|1@1+ (1,0) [0|0] "" X
 SG_ UI_enableNavRouteCSA: 57|1@1+ (1,0) [0|0] "" X
 SG_ UI_enableNextGenACC: 19|1@1+ (1,0) [0|0] "" X
 SG_ UI_enableRoadSegmentTelemetry: 44|1@1+ (1,0) [0|0] "" X
 SG_ UI_enableTripTelemetry: 43|1@1+ (1,0) [0|0] "" X
 SG_ UI_enableVinAssociation: 6|1@1+ (1,0) [0|0] "" X
 SG_ UI_enableVisionOnlyStops: 63|1@1+ (1,0) [0|0] "" X
 SG_ UI_exceptionListEnable: 11|1@1+ (1,0) [0|0] "" X
 SG_ UI_followNavRouteEnable: 46|1@1+ (1,0) [0|0] "" X
 SG_ UI_forksEnable: 15|1@1+ (1,0) [0|0] "" X
 SG_ UI_fuseHPPDisable: 17|1@1+ (1,0) [0|0] "" X
 SG_ UI_fuseLanesDisable: 16|1@1+ (1,0) [0|0] "" X
 SG_ UI_fuseVehiclesDisable: 18|1@1+ (1,0) [0|0] "" X
 SG_ UI_handsOnRequirementDisable: 14|1@1+ (1,0) [0|0] "" X
 SG_ UI_hasDriveOnNav: 47|1@1+ (1,0) [0|0] "" X
 SG_ UI_lssElkEnabled: 23|1@1+ (1,0) [0|0] "" X
 SG_ UI_lssLdwEnabled: 8|1@1+ (1,0) [0|0] "" X
 SG_ UI_lssLkaEnabled: 7|1@1+ (1,0) [0|0] "" X
 SG_ UI_roadCheckDisable: 12|1@1+ (1,0) [0|0] "" X
 SG_ UI_selfParkRequest: 28|4@1+ (1,0) [0|0] "" X
 SG_ UI_source3D: 60|3@1+ (1,0) [0|0] "" X
 SG_ UI_summonEntryType: 26|2@1+ (1,0) [0|0] "" X
 SG_ UI_summonExitType: 24|2@1+ (1,0) [0|0] "" X
 SG_ UI_summonHeartbeat: 2|2@1+ (1,0) [0|0] "" X
 SG_ UI_summonReverseDist: 32|6@1+ (1,0) [0|0] "" X
 SG_ UI_ulcBlindSpotConfig: 50|2@1+ (1,0) [0|0] "" X
 SG_ UI_ulcOffHighway: 56|1@1+ (1,0) [0|0] "" X
 SG_ UI_ulcSpeedConfig: 48|2@1+ (1,0) [0|0] "" X
 SG_ UI_ulcStalkConfirm: 1|1@1+ (1,0) [0|0] "" X
 SG_ UI_undertakeAssistEnable: 38|1@1+ (1,0) [0|0] "" X
 SG_ UI_validationLoop: 55|1@1+ (1,0) [0|0] "" X
 SG_ UI_visionSpeedType: 20|2@1+ (1,0) [0|0] "" X

BO_ 568 UI_driverAssistMapData: 8 ETH
 SG_ UI_acceptBottsDots: 48|1@1+ (1,0) [0|0] "" X
 SG_ UI_autosteerRestricted: 49|1@1+ (1,0) [0|0] "" X
 SG_ UI_controlledAccess: 37|1@1+ (1,0) [0|0] "" X
 SG_ UI_countryCode: 16|10@1+ (1,0) [0|0] "" X
 SG_ UI_gpsRoadMatch: 28|1@1+ (1,0) [0|0] "" X
 SG_ UI_inSuperchargerGeofence: 6|1@1+ (1,0) [0|0] "" X
 SG_ UI_mapDataChecksum: 56|8@1+ (1,0) [0|0] "" X
 SG_ UI_mapDataCounter: 52|4@1+ (1,0) [0|0] "" X
 SG_ UI_mapSpeedLimit: 8|5@1+ (1,0) [0|0] "" X
 SG_ UI_mapSpeedLimitDependency: 0|3@1+ (1,0) [0|0] "" X
 SG_ UI_mapSpeedLimitType: 13|3@1+ (1,0) [0|0] "" X
 SG_ UI_mapSpeedUnits: 7|1@1+ (1,0) [0|0] "" X
 SG_ UI_navRouteActive: 29|1@1+ (1,0) [0|0] "" X
 SG_ UI_nextBranchDist: 32|5@1+ (10,0) [0|0] "m" X
 SG_ UI_nextBranchLeftOffRamp: 38|1@1+ (1,0) [0|0] "" X
 SG_ UI_nextBranchRightOffRamp: 39|1@1+ (1,0) [0|0] "" X
 SG_ UI_parallelAutoparkEnabled: 30|1@1+ (1,0) [0|0] "" X
 SG_ UI_perpendicularAutoparkEnabled: 31|1@1+ (1,0) [0|0] "" X
 SG_ UI_pmmEnabled: 50|1@1+ (1,0) [0|0] "" X
 SG_ UI_rejectAutosteer: 46|1@1+ (1,0) [0|0] "" X
 SG_ UI_rejectHPP: 42|1@1+ (1,0) [0|0] "" X
 SG_ UI_rejectHandsOn: 47|1@1+ (1,0) [0|0] "" X
 SG_ UI_rejectLeftFreeSpace: 44|1@1+ (1,0) [0|0] "" X
 SG_ UI_rejectLeftLane: 40|1@1+ (1,0) [0|0] "" X
 SG_ UI_rejectNav: 43|1@1+ (1,0) [0|0] "" X
 SG_ UI_rejectRightFreeSpace: 45|1@1+ (1,0) [0|0] "" X
 SG_ UI_rejectRightLane: 41|1@1+ (1,0) [0|0] "" X
 SG_ UI_roadClass: 3|3@1+ (1,0) [0|0] "" X
 SG_ UI_scaEnabled: 51|1@1+ (1,0) [0|0] "" X
 SG_ UI_streetCount: 26|2@1+ (1,0) [0|0] "" X

BO_ 536 UI_driverAssistRoadSign: 8 ETH
 SG_ UI_roadSign M: 0|8@1+ (1,0) [0|0] "" X
 SG_ UI_roadSignChecksum: 56|8@1+ (1,0) [0|0] "" X
 SG_ UI_roadSignCounter: 52|4@1+ (1,0) [0|0] "" X
 SG_ UI_splineID: 48|4@1+ (1,0) [0|0] "" X
 SG_ UI_splineLocConfidence: 40|7@1+ (1,0) [0|0] "" X
 SG_ UI_dummyData m0: 8|1@1+ (1,0) [0|0] "" X
 SG_ UI_stopSignStopLineDist m1: 8|10@1+ (0.25,-8) [0|0] "m" X
 SG_ UI_stopSignStopLineConf m1: 18|7@1+ (1,0) [0|0] "" X
 SG_ UI_trafficLightStopLineDist m2: 8|10@1+ (0.25,-8) [0|0] "m" X
 SG_ UI_trafficLightStopLineConf m2: 18|7@1+ (1,0) [0|0] "" X
 SG_ UI_baseMapSpeedLimitMPS m3: 8|8@1+ (0.25,0) [0|0] "m/s" X
 SG_ UI_bottomQrtlFleetSpeedMPS m3: 16|8@1+ (0.25,0) [0|0] "m/s" X
 SG_ UI_topQrtlFleetSpeedMPS m3: 24|8@1+ (0.25,0) [0|0] "m/s" X
 SG_ UI_meanFleetSplineSpeedMPS m4: 8|8@1+ (0.25,0) [0|0] "m/s" X
 SG_ UI_medianFleetSpeedMPS m4: 16|8@1+ (0.25,0) [0|0] "m/s" X
 SG_ UI_meanFleetSplineAccelMPS2 m4: 24|8@1+ (0.05,-6.35) [0|0] "m/s^2" X
 SG_ UI_rampType m4: 32|3@1+ (1,0) [0|0] "" X
 SG_ UI_currSplineIdFull m5: 8|32@1+ (1,0) [0|0] "" X

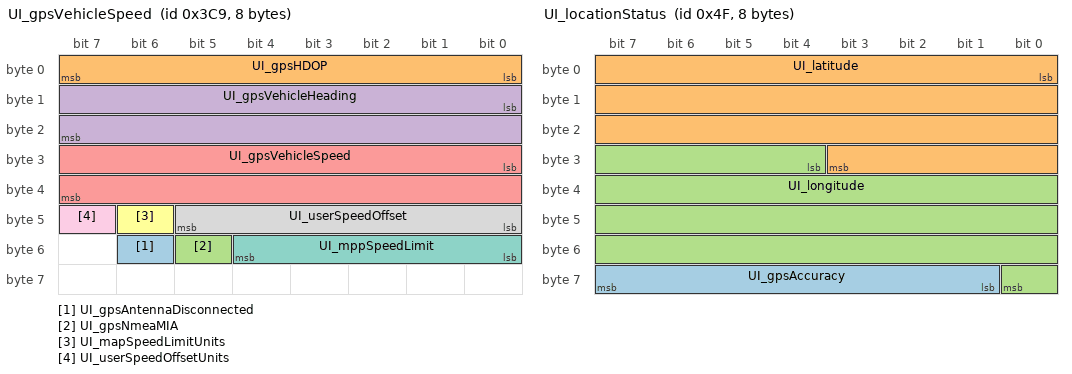
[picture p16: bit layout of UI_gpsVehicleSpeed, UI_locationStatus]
BO_ 969 UI_gpsVehicleSpeed: 8 ETH
 SG_ UI_gpsAntennaDisconnected: 54|1@1+ (1,0) [0|0] "" X
 SG_ UI_gpsHDOP: 0|8@1+ (0.1,0) [0|0] "1" X
 SG_ UI_gpsNmeaMIA: 53|1@1+ (1,0) [0|0] "" X
 SG_ UI_gpsVehicleHeading: 8|16@1+ (0.0078125,0) [0|0] "deg" X
 SG_ UI_gpsVehicleSpeed: 24|16@1+ (0.00390625,0) [0|0] "km/hr" X
 SG_ UI_mapSpeedLimitUnits: 46|1@1+ (1,0) [0|0] "" X
 SG_ UI_mppSpeedLimit: 48|5@1+ (5,0) [0|0] "kph/mph" X
 SG_ UI_userSpeedOffset: 40|6@1+ (1,-30) [0|0] "kph/mph" X
 SG_ UI_userSpeedOffsetUnits: 47|1@1+ (1,0) [0|0] "" X

BO_ 79 UI_locationStatus: 8 ETH
 SG_ UI_gpsAccuracy: 57|7@1+ (0.2,0) [0|0] "m" X
 SG_ UI_latitude: 0|28@1- (1e-06,0) [0|0] "deg" X
 SG_ UI_longitude: 28|29@1- (1e-06,0) [0|0] "deg" X

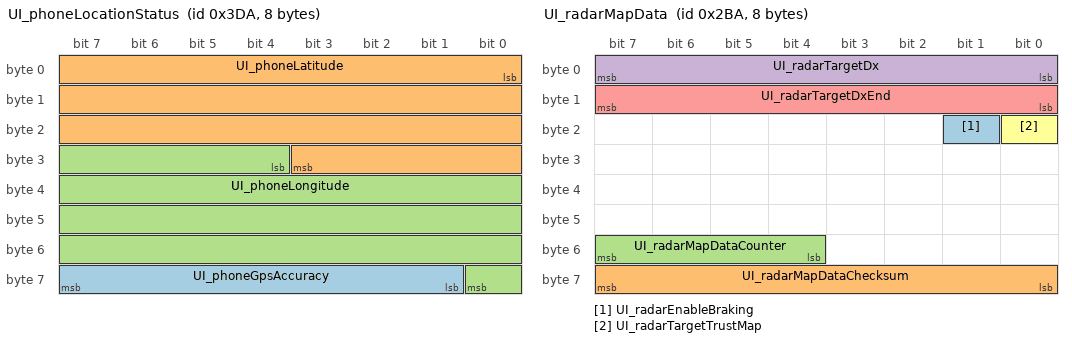
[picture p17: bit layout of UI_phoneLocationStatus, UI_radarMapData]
BO_ 986 UI_phoneLocationStatus: 8 ETH
 SG_ UI_phoneGpsAccuracy: 57|7@1+ (0.2,0) [0|0] "m" X
 SG_ UI_phoneLatitude: 0|28@1- (1e-06,0) [0|0] "deg" X
 SG_ UI_phoneLongitude: 28|29@1- (1e-06,0) [0|0] "deg" X

BO_ 698 UI_radarMapData: 8 ETH
 SG_ UI_radarEnableBraking: 17|1@1+ (1,0) [0|0] "" X
 SG_ UI_radarMapDataChecksum: 56|8@1+ (1,0) [0|0] "" X
 SG_ UI_radarMapDataCounter: 52|4@1+ (1,0) [0|0] "" X
 SG_ UI_radarTargetDx: 0|8@1+ (1,-95) [0|0] "m" X
 SG_ UI_radarTargetDxEnd: 8|8@1+ (1,0) [0|0] "m" X
 SG_ UI_radarTargetTrustMap: 16|1@1+ (1,0) [0|0] "" X

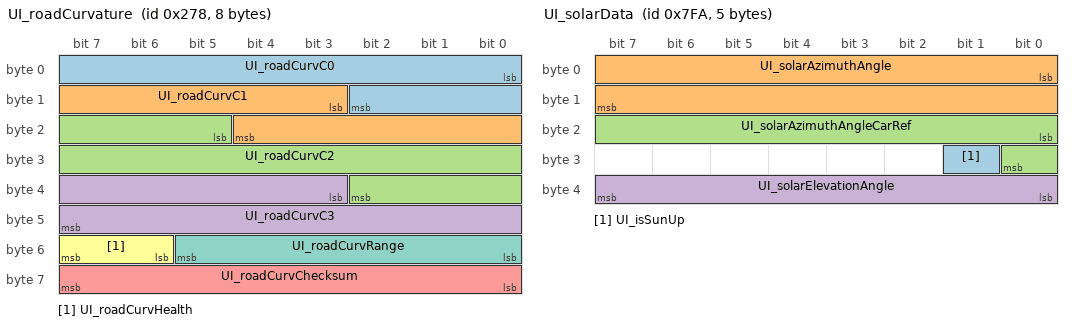
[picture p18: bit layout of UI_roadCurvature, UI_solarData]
BO_ 632 UI_roadCurvature: 8 ETH
 SG_ UI_roadCurvC0: 0|11@1- (0.02,0) [0|0] "m" X
 SG_ UI_roadCurvC1: 11|10@1- (0.00075,0) [0|0] "1" X
 SG_ UI_roadCurvC2: 21|14@1- (7.5e-06,0) [0|0] "1/m" X
 SG_ UI_roadCurvC3: 35|13@1- (3e-08,0) [0|0] "1/m2" X
 SG_ UI_roadCurvChecksum: 56|8@1+ (1,0) [0|0] "" X
 SG_ UI_roadCurvHealth: 54|2@1+ (1,0) [0|0] "" X
 SG_ UI_roadCurvRange: 48|6@1+ (4,0) [0|0] "m" X

BO_ 2042 UI_solarData: 5 ETH
 SG_ UI_isSunUp: 25|1@1+ (1,0) [0|0] "" X
 SG_ UI_solarAzimuthAngle: 0|16@1- (1,0) [0|0] "deg" X
 SG_ UI_solarAzimuthAngleCarRef: 16|9@1- (1,0) [0|0] "deg" X
 SG_ UI_solarElevationAngle: 32|8@1- (1,0) [0|0] "deg" X

BO_ 12 UI_status: 8 ETH
 SG_ UI_audioActive: 1|1@1+ (1,0) [0|0] "" X
 SG_ UI_autopilotTrial: 48|2@1+ (1,0) [0|0] "" X
 SG_ UI_bluetoothActive: 2|1@1+ (1,0) [0|0] "" X
 SG_ UI_cameraActive: 14|1@1+ (1,0) [0|0] "" X
 SG_ UI_cellActive: 3|1@1+ (1,0) [0|0] "" X
 SG_ UI_cellConnected: 11|1@1+ (1,0) [0|0] "" X
 SG_ UI_cellNetworkTechnology: 20|4@1+ (1,0) [0|0] "" X
 SG_ UI_cellReceiverPower: 56|8@1+ (1,-128) [0|0] "dB" X
 SG_ UI_cellSignalBars: 50|3@1+ (1,0) [0|0] "" X
 SG_ UI_developmentCar: 55|1@1+ (1,0) [0|0] "" X
 SG_ UI_displayOn: 9|1@1+ (1,0) [0|0] "" X
 SG_ UI_displayReady: 4|1@1+ (1,0) [0|0] "" X
 SG_ UI_factoryReset: 18|2@1+ (1,0) [0|0] "" X
 SG_ UI_googleWifiUsages: 40|8@1+ (1,0) [0|0] "" X
 SG_ UI_gpsActive: 5|1@1+ (1,0) [0|0] "" X
 SG_ UI_hardwareType: 53|2@1+ (1,0) [0|0] "" X
 SG_ UI_monitorModemPower: 17|1@1+ (1,0) [0|0] "" X
 SG_ UI_readyForDrive: 10|1@1+ (1,0) [0|0] "" X
 SG_ UI_screenshotActive: 16|1@1+ (1,0) [0|0] "" X
 SG_ UI_systemActive: 7|1@1+ (1,0) [0|0] "" X
 SG_ UI_tegraAmbientTemperature: 32|8@1+ (1,-64) [0|0] "deg C" X
 SG_ UI_tegraCoreTemperature: 24|8@1+ (1,-64) [0|0] "deg C" X
 SG_ UI_touchActive: 0|1@1+ (1,0) [0|0] "" X
 SG_ UI_usbActive: 15|1@1+ (1,0) [0|0] "" X
 SG_ UI_vpnActive: 12|1@1+ (1,0) [0|0] "" X
 SG_ UI_wifiActive: 13|1@1+ (1,0) [0|0] "" X
 SG_ UI_wifiConnected: 6|1@1+ (1,0) [0|0] "" X
 SG_ UI_xmActive: 8|1@1+ (1,0) [0|0] "" X

BO_ 1064 UI_telemetryControl: 8 ETH
 SG_ UI_TCR_classConstElem: 5|1@1+ (1,0) [0|0] "" X
 SG_ UI_TCR_classMovingFourWheel: 8|1@1+ (1,0) [0|0] "" X
 SG_ UI_TCR_classMovingPed: 6|1@1+ (1,0) [0|0] "" X
 SG_ UI_TCR_classMovingTwoWheel: 7|1@1+ (1,0) [0|0] "" X
 SG_ UI_TCR_classUnknown: 9|1@1+ (1,0) [0|0] "" X
 SG_ UI_TCR_downSampleFactor: 16|4@1+ (1,0) [0|0] "" X
 SG_ UI_TCR_enable: 0|1@1+ (1,0) [0|0] "" X
 SG_ UI_TCR_maxDy: 48|5@1+ (0.5,0) [0|0] "m" X
 SG_ UI_TCR_maxObjects: 56|5@1+ (1,0) [0|0] "" X
 SG_ UI_TCR_maxRoadClass: 61|3@1+ (1,0) [0|0] "" X
 SG_ UI_TCR_minRCS: 40|8@1+ (0.25,-14) [0|0] "dB" X
 SG_ UI_TCR_moveStateIndeterm: 4|1@1+ (1,0) [0|0] "" X
 SG_ UI_TCR_moveStateMoving: 3|1@1+ (1,0) [0|0] "" X
 SG_ UI_TCR_moveStateStanding: 1|1@1+ (1,0) [0|0] "" X
 SG_ UI_TCR_moveStateStopped: 2|1@1+ (1,0) [0|0] "" X
 SG_ UI_TCR_vehSpeed: 32|8@1+ (1,0) [0|0] "" X
 SG_ UI_TCR_wExist: 24|5@1+ (1,0) [0|0] "" X

BO_ 1151 UMC_alertMatrix: 8 ETH
 SG_ UMC_w001_gndMonIntrptLineSide: 0|1@1+ (1,0) [0|0] "" X
 SG_ UMC_w002_GFCITripped: 1|1@1+ (1,0) [0|0] "" X
 SG_ UMC_w003_GFCISelfTestFault: 2|1@1+ (1,0) [0|0] "" X
 SG_ UMC_w004_inputOverVoltage: 3|1@1+ (1,0) [0|0] "" X
 SG_ UMC_w005_inputUnderVoltage: 4|1@1+ (1,0) [0|0] "" X
 SG_ UMC_w006_contactorWelded: 5|1@1+ (1,0) [0|0] "" X
 SG_ UMC_w007_pcbaOT: 6|1@1+ (1,0) [0|0] "" X
 SG_ UMC_w008_wallPlugOT: 7|1@1+ (1,0) [0|0] "" X
 SG_ UMC_w009_vehConnOT: 8|1@1+ (1,0) [0|0] "" X
 SG_ UMC_w010_inputOT: 9|1@1+ (1,0) [0|0] "" X
 SG_ UMC_w011_proxDisconnected: 10|1@1+ (1,0) [0|0] "" X
 SG_ UMC_w012_pilotFault: 11|1@1+ (1,0) [0|0] "" X
 SG_ UMC_w013_SA_Temperature: 12|1@1+ (1,0) [0|0] "" X
 SG_ UMC_w014_SA_Genealogy: 13|1@1+ (1,0) [0|0] "" X
 SG_ UMC_w015_SA_Connection: 14|1@1+ (1,0) [0|0] "" X
 SG_ UMC_w016_pcbaOTFoldback: 15|1@1+ (1,0) [0|0] "" X
 SG_ UMC_w017_wallPlugOTFoldback: 16|1@1+ (1,0) [0|0] "" X
 SG_ UMC_w018_vehConnOTFoldback: 17|1@1+ (1,0) [0|0] "" X
 SG_ UMC_w019_inputOTFoldback: 18|1@1+ (1,0) [0|0] "" X
 SG_ UMC_w020_applicationCRC: 19|1@1+ (1,0) [0|0] "" X
 SG_ UMC_w021_dataBus: 20|1@1+ (1,0) [0|0] "" X
 SG_ UMC_w022_criticalRAM: 21|1@1+ (1,0) [0|0] "" X
 SG_ UMC_w023_adcSelfTest: 22|1@1+ (1,0) [0|0] "" X

BO_ 1352 UserConfig: 8 ETH
 SG_ MCU_AFSLightingEnabled: 12|1@1+ (1,0) [0|0] "" X
 SG_ MCU_alarmAutoOn: 15|1@1+ (1,0) [0|0] "" X
 SG_ MCU_approachLightingOn: 0|1@1+ (1,0) [0|0] "" X
 SG_ MCU_autoDoorLockOn: 41|1@1+ (1,0) [0|0] "" X
 SG_ MCU_autoFoldMirrorsOn: 42|1@1+ (1,0) [0|0] "" X
 SG_ MCU_autoPresentDoors: 14|1@1+ (1,0) [0|0] "" X
 SG_ MCU_childDoorLockOn: 2|1@1+ (1,0) [0|0] "" X
 SG_ MCU_closeAllOnRKELock: 55|1@1+ (1,0) [0|0] "" X
 SG_ MCU_configWiperSwitch: 48|3@1+ (1,0) [0|0] "" X
 SG_ MCU_courtesyLightingOn: 30|1@1+ (1,0) [0|0] "" X
 SG_ MCU_daytimeRunningLampsOn: 38|1@1+ (1,0) [0|0] "" X
 SG_ MCU_diAckOfPassiveLocking: 5|1@1+ (1,0) [0|0] "" X
 SG_ MCU_displayBrightnessLevel: 16|8@1+ (0.5,0) [0|0] "%" X
 SG_ MCU_doorMoodLighting: 32|3@1+ (1,0) [0|0] "" X
 SG_ MCU_doorsGlobalUnlockOn: 45|1@1+ (1,0) [0|0] "" X
 SG_ MCU_driveAwayLockingSpeed: 56|8@1+ (1,0) [0|0] "kph" X
 SG_ MCU_entryLightingTimer: 24|3@1+ (1,0) [0|0] "" X
 SG_ MCU_exitLightingTimer: 27|3@1+ (1,0) [0|0] "" X
 SG_ MCU_falconQuickOpenDefault: 13|1@1+ (1,0) [0|0] "" X
 SG_ MCU_footwellMoodLighting: 35|3@1+ (1,0) [0|0] "" X
 SG_ MCU_interiorAlarmRoofOpenOn: 44|1@1+ (1,0) [0|0] "" X
 SG_ MCU_intrusionSensorOn: 7|1@1+ (1,0) [0|0] "" X
 SG_ MCU_kl58UserLevelSelected: 8|3@1+ (1,0) [0|0] "" X
 SG_ MCU_magicLockingOn: 4|1@1+ (1,0) [0|0] "" X
 SG_ MCU_mirrorDipOnReverse: 52|2@1+ (1,0) [0|0] "" X
 SG_ MCU_passiveEntryEnabled: 11|1@1+ (1,0) [0|0] "" X
 SG_ MCU_rangeModeOn: 39|1@1+ (1,0) [0|0] "" X
 SG_ MCU_seeYouHomeLightingOn: 1|1@1+ (1,0) [0|0] "" X
 SG_ MCU_showroomModeOn: 46|1@1+ (1,0) [0|0] "" X
 SG_ MCU_startButtonPulseOn: 43|1@1+ (1,0) [0|0] "" X
 SG_ MCU_tiltSensorOn: 6|1@1+ (1,0) [0|0] "" X
 SG_ MCU_timedWiperModeOn: 47|1@1+ (1,0) [0|0] "" X
 SG_ MCU_transportModeOn: 51|1@1+ (1,0) [0|0] "" X
 SG_ MCU_unlockOnPark: 31|1@1+ (1,0) [0|0] "" X
 SG_ MCU_valetModeOn: 40|1@1+ (1,0) [0|0] "" X
 SG_ MCU_walkUpHandlesPresentOn: 3|1@1+ (1,0) [0|0] "" X

BO_ 1788 VALEOUSS_udsResponse: 8 ETH
 SG_ VALEOUSS_udsResponseData: 0|54@0+ (1024,0) [0|0] "" X

BA_DEF_ BO_ "GenMsgSendType" ENUM "Cyclic";
BA_DEF_ BO_ "GenMsgCycleTime" INT 0 60000;

BA_ "GenMsgSendType" BO_ 881 0;
BA_ "GenMsgCycleTime" BO_ 881 1000;

BA_ "GenMsgSendType" BO_ 273 0;
BA_ "GenMsgCycleTime" BO_ 273 10;

BA_ "GenMsgSendType" BO_ 535 0;
BA_ "GenMsgCycleTime" BO_ 535 100;

BA_ "GenMsgSendType" BO_ 561 0;
BA_ "GenMsgCycleTime" BO_ 561 100;

BA_ "GenMsgSendType" BO_ 705 0;
BA_ "GenMsgCycleTime" BO_ 705 100;

BA_ "GenMsgSendType" BO_ 531 0;
BA_ "GenMsgCycleTime" BO_ 531 1000;

BA_ "GenMsgSendType" BO_ 576 0;
BA_ "GenMsgCycleTime" BO_ 576 100;

BA_ "GenMsgSendType" BO_ 513 0;
BA_ "GenMsgCycleTime" BO_ 513 100;

BA_ "GenMsgSendType" BO_ 1503 0;
BA_ "GenMsgCycleTime" BO_ 1503 10000;

BA_ "GenMsgSendType" BO_ 547 0;
BA_ "GenMsgCycleTime" BO_ 547 1000;

BA_ "GenMsgSendType" BO_ 16 0;
BA_ "GenMsgCycleTime" BO_ 16 10;

BA_ "GenMsgSendType" BO_ 102 0;
BA_ "GenMsgCycleTime" BO_ 102 1000;

BA_ "GenMsgSendType" BO_ 1317 0;
BA_ "GenMsgCycleTime" BO_ 1317 1000;

BA_ "GenMsgSendType" BO_ 1318 0;
BA_ "GenMsgCycleTime" BO_ 1318 1000;

BA_ "GenMsgSendType" BO_ 1319 0;
BA_ "GenMsgCycleTime" BO_ 1319 1000;

BA_ "GenMsgSendType" BO_ 1320 0;
BA_ "GenMsgCycleTime" BO_ 1320 1000;

BA_ "GenMsgSendType" BO_ 138 0;
BA_ "GenMsgCycleTime" BO_ 138 25;

BA_ "GenMsgSendType" BO_ 1292 0;
BA_ "GenMsgCycleTime" BO_ 1292 100;

BA_ "GenMsgSendType" BO_ 545 0;
BA_ "GenMsgCycleTime" BO_ 545 100;

BA_ "GenMsgSendType" BO_ 1307 0;
BA_ "GenMsgCycleTime" BO_ 1307 1000;

BA_ "GenMsgSendType" BO_ 555 0;
BA_ "GenMsgCycleTime" BO_ 555 100;

BA_ "GenMsgSendType" BO_ 743 0;
BA_ "GenMsgCycleTime" BO_ 743 1000;

BA_ "GenMsgSendType" BO_ 859 0;
BA_ "GenMsgCycleTime" BO_ 859 1000;

BA_ "GenMsgSendType" BO_ 631 0;
BA_ "GenMsgCycleTime" BO_ 631 1000;

BA_ "GenMsgSendType" BO_ 615 0;
BA_ "GenMsgCycleTime" BO_ 615 1000;

BA_ "GenMsgSendType" BO_ 599 0;
BA_ "GenMsgCycleTime" BO_ 599 1000;

BA_ "GenMsgSendType" BO_ 58 0;
BA_ "GenMsgCycleTime" BO_ 58 1000;

BA_ "GenMsgSendType" BO_ 53 0;
BA_ "GenMsgCycleTime" BO_ 53 100;

BA_ "GenMsgSendType" BO_ 45 0;
BA_ "GenMsgCycleTime" BO_ 45 1000;

BA_ "GenMsgSendType" BO_ 46 0;
BA_ "GenMsgCycleTime" BO_ 46 1000;

BA_ "GenMsgSendType" BO_ 47 0;
BA_ "GenMsgCycleTime" BO_ 47 1000;

BA_ "GenMsgSendType" BO_ 48 0;
BA_ "GenMsgCycleTime" BO_ 48 1000;

BA_ "GenMsgSendType" BO_ 682 0;
BA_ "GenMsgCycleTime" BO_ 682 100;

BA_ "GenMsgSendType" BO_ 618 0;
BA_ "GenMsgCycleTime" BO_ 618 100;

BA_ "GenMsgSendType" BO_ 522 0;
BA_ "GenMsgCycleTime" BO_ 522 100;

BA_ "GenMsgSendType" BO_ 778 0;
BA_ "GenMsgCycleTime" BO_ 778 1000;

BA_ "GenMsgSendType" BO_ 21 0;
BA_ "GenMsgCycleTime" BO_ 21 1000;

BA_ "GenMsgSendType" BO_ 1610 0;
BA_ "GenMsgCycleTime" BO_ 1610 1000;

BA_ "GenMsgSendType" BO_ 842 0;
BA_ "GenMsgCycleTime" BO_ 842 1000;

BA_ "GenMsgSendType" BO_ 1322 0;
BA_ "GenMsgCycleTime" BO_ 1322 1000;

BA_ "GenMsgSendType" BO_ 1626 0;
BA_ "GenMsgCycleTime" BO_ 1626 1000;

BA_ "GenMsgSendType" BO_ 602 0;
BA_ "GenMsgCycleTime" BO_ 602 100;

BA_ "GenMsgSendType" BO_ 858 0;
BA_ "GenMsgCycleTime" BO_ 858 1000;

BA_ "GenMsgSendType" BO_ 810 0;
BA_ "GenMsgCycleTime" BO_ 810 1000;

BA_ "GenMsgSendType" BO_ 826 0;
BA_ "GenMsgCycleTime" BO_ 826 1000;

BA_ "GenMsgSendType" BO_ 874 0;
BA_ "GenMsgCycleTime" BO_ 874 1000;

BA_ "GenMsgSendType" BO_ 890 0;
BA_ "GenMsgCycleTime" BO_ 890 1000;

BA_ "GenMsgSendType" BO_ 922 0;
BA_ "GenMsgCycleTime" BO_ 922 1000;

BA_ "GenMsgSendType" BO_ 1642 0;
BA_ "GenMsgCycleTime" BO_ 1642 1000;

BA_ "GenMsgSendType" BO_ 1002 0;
BA_ "GenMsgCycleTime" BO_ 1002 1000;

BA_ "GenMsgSendType" BO_ 2029 0;
BA_ "GenMsgCycleTime" BO_ 2029 1000;

BA_ "GenMsgSendType" BO_ 2030 0;
BA_ "GenMsgCycleTime" BO_ 2030 1000;

BA_ "GenMsgSendType" BO_ 132 0;
BA_ "GenMsgCycleTime" BO_ 132 1000;

BA_ "GenMsgSendType" BO_ 123 0;
BA_ "GenMsgCycleTime" BO_ 123 1000;

BA_ "GenMsgSendType" BO_ 899 0;
BA_ "GenMsgCycleTime" BO_ 899 1000;

BA_ "GenMsgSendType" BO_ 927 0;
BA_ "GenMsgCycleTime" BO_ 927 1000;

BA_ "GenMsgSendType" BO_ 911 0;
BA_ "GenMsgCycleTime" BO_ 911 100;

BA_ "GenMsgSendType" BO_ 815 0;
BA_ "GenMsgCycleTime" BO_ 815 100;

BA_ "GenMsgSendType" BO_ 783 0;
BA_ "GenMsgCycleTime" BO_ 783 1000;

BA_ "GenMsgSendType" BO_ 936 0;
BA_ "GenMsgCycleTime" BO_ 936 100;

BA_ "GenMsgSendType" BO_ 895 0;
BA_ "GenMsgCycleTime" BO_ 895 100;

BA_ "GenMsgSendType" BO_ 863 0;
BA_ "GenMsgCycleTime" BO_ 863 100;

BA_ "GenMsgSendType" BO_ 879 0;
BA_ "GenMsgCycleTime" BO_ 879 100;

BA_ "GenMsgSendType" BO_ 904 0;
BA_ "GenMsgCycleTime" BO_ 904 100;

BA_ "GenMsgSendType" BO_ 920 0;
BA_ "GenMsgCycleTime" BO_ 920 100;

BA_ "GenMsgSendType" BO_ 831 0;
BA_ "GenMsgCycleTime" BO_ 831 100;

BA_ "GenMsgSendType" BO_ 767 0;
BA_ "GenMsgCycleTime" BO_ 767 100;

BA_ "GenMsgSendType" BO_ 1407 0;
BA_ "GenMsgCycleTime" BO_ 1407 5000;

BA_ "GenMsgSendType" BO_ 1423 0;
BA_ "GenMsgCycleTime" BO_ 1423 5000;

BA_ "GenMsgSendType" BO_ 1006 0;
BA_ "GenMsgCycleTime" BO_ 1006 1000;

BA_ "GenMsgSendType" BO_ 664 0;
BA_ "GenMsgCycleTime" BO_ 664 100;

BA_ "GenMsgSendType" BO_ 680 0;
BA_ "GenMsgCycleTime" BO_ 680 100;

BA_ "GenMsgSendType" BO_ 1080 0;
BA_ "GenMsgCycleTime" BO_ 1080 1000;

BA_ "GenMsgSendType" BO_ 1000 0;
BA_ "GenMsgCycleTime" BO_ 1000 1000;

BA_ "GenMsgSendType" BO_ 568 0;
BA_ "GenMsgCycleTime" BO_ 568 500;

BA_ "GenMsgSendType" BO_ 536 0;
BA_ "GenMsgCycleTime" BO_ 536 100;

BA_ "GenMsgSendType" BO_ 969 0;
BA_ "GenMsgCycleTime" BO_ 969 1000;

BA_ "GenMsgSendType" BO_ 79 0;
BA_ "GenMsgCycleTime" BO_ 79 1000;

BA_ "GenMsgSendType" BO_ 986 0;
BA_ "GenMsgCycleTime" BO_ 986 1000;

BA_ "GenMsgSendType" BO_ 698 0;
BA_ "GenMsgCycleTime" BO_ 698 100;

BA_ "GenMsgSendType" BO_ 632 0;
BA_ "GenMsgCycleTime" BO_ 632 100;

BA_ "GenMsgSendType" BO_ 2042 0;
BA_ "GenMsgCycleTime" BO_ 2042 1000;

BA_ "GenMsgSendType" BO_ 12 0;
BA_ "GenMsgCycleTime" BO_ 12 1000;

BA_ "GenMsgSendType" BO_ 1064 0;
BA_ "GenMsgCycleTime" BO_ 1064 1000;

BA_ "GenMsgSendType" BO_ 1151 0;
BA_ "GenMsgCycleTime" BO_ 1151 1000;

BA_ "GenMsgSendType" BO_ 1352 0;
BA_ "GenMsgCycleTime" BO_ 1352 5000;

VAL_ 881 RCM_d000_comFault1 0 "NOT_TESTED_DTC" 1 "PASSED_DTC" 2 "FAILED_DTC" 3 "UNABLE_TO_TEST_DTC";
VAL_ 881 RCM_d001_vBatRange 0 "NOT_TESTED_DTC" 1 "PASSED_DTC" 2 "FAILED_DTC" 3 "UNABLE_TO_TEST_DTC";
VAL_ 881 RCM_d002_vinMismatch 0 "NOT_TESTED_DTC" 1 "PASSED_DTC" 2 "FAILED_DTC" 3 "UNABLE_TO_TEST_DTC";
VAL_ 881 RCM_d003_swVersionMismatch 0 "NOT_TESTED_DTC" 1 "PASSED_DTC" 2 "FAILED_DTC" 3 "UNABLE_TO_TEST_DTC";
VAL_ 881 RCM_d004_idleMode 0 "NOT_TESTED_DTC" 1 "PASSED_DTC" 2 "FAILED_DTC" 3 "UNABLE_TO_TEST_DTC";
VAL_ 881 RCM_d005_internalHard 0 "NOT_TESTED_DTC" 1 "PASSED_DTC" 2 "FAILED_DTC" 3 "UNABLE_TO_TEST_DTC";
VAL_ 881 RCM_d006_crashAlgoDisabled 0 "NOT_TESTED_DTC" 1 "PASSED_DTC" 2 "FAILED_DTC" 3 "UNABLE_TO_TEST_DTC";
VAL_ 881 RCM_d007_eolProgMismatch 0 "NOT_TESTED_DTC" 1 "PASSED_DTC" 2 "FAILED_DTC" 3 "UNABLE_TO_TEST_DTC";
VAL_ 881 RCM_d008_crcErrorExternal 0 "NOT_TESTED_DTC" 1 "PASSED_DTC" 2 "FAILED_DTC" 3 "UNABLE_TO_TEST_DTC";
VAL_ 881 RCM_d009_cfgFault 0 "NOT_TESTED_DTC" 1 "PASSED_DTC" 2 "FAILED_DTC" 3 "UNABLE_TO_TEST_DTC";
VAL_ 881 RCM_d010_crashCalPNMissing 0 "NOT_TESTED_DTC" 1 "PASSED_DTC" 2 "FAILED_DTC" 3 "UNABLE_TO_TEST_DTC";
VAL_ 881 RCM_d011_vdsFieldCalibFailed 0 "NOT_TESTED_DTC" 1 "PASSED_DTC" 2 "FAILED_DTC" 3 "UNABLE_TO_TEST_DTC";
VAL_ 881 RCM_d012_vdsChannelSigMonTmp 0 "NOT_TESTED_DTC" 1 "PASSED_DTC" 2 "FAILED_DTC" 3 "UNABLE_TO_TEST_DTC";
VAL_ 881 RCM_d013_vdsFieldCalibNotDone 0 "NOT_TESTED_DTC" 1 "PASSED_DTC" 2 "FAILED_DTC" 3 "UNABLE_TO_TEST_DTC";
VAL_ 881 RCM_d014_vdsChannelSigMonPerm 0 "NOT_TESTED_DTC" 1 "PASSED_DTC" 2 "FAILED_DTC" 3 "UNABLE_TO_TEST_DTC";
VAL_ 881 RCM_d015_vdsSensorMonitorTemp 0 "NOT_TESTED_DTC" 1 "PASSED_DTC" 2 "FAILED_DTC" 3 "UNABLE_TO_TEST_DTC";
VAL_ 881 RCM_d016_comCANInitFailure 0 "NOT_TESTED_DTC" 1 "PASSED_DTC" 2 "FAILED_DTC" 3 "UNABLE_TO_TEST_DTC";
VAL_ 881 RCM_d017_comGTWCarConfig 0 "NOT_TESTED_DTC" 1 "PASSED_DTC" 2 "FAILED_DTC" 3 "UNABLE_TO_TEST_DTC";
VAL_ 881 RCM_d018_vinEmptyError 0 "NOT_TESTED_DTC" 1 "PASSED_DTC" 2 "FAILED_DTC" 3 "UNABLE_TO_TEST_DTC";
VAL_ 881 RCM_d019_comESPC 0 "NOT_TESTED_DTC" 1 "PASSED_DTC" 2 "FAILED_DTC" 3 "UNABLE_TO_TEST_DTC";
VAL_ 881 RCM_d020_comESP135 0 "NOT_TESTED_DTC" 1 "PASSED_DTC" 2 "FAILED_DTC" 3 "UNABLE_TO_TEST_DTC";
VAL_ 881 RCM_d021_comEPBStatus 0 "NOT_TESTED_DTC" 1 "PASSED_DTC" 2 "FAILED_DTC" 3 "UNABLE_TO_TEST_DTC";
VAL_ 881 RCM_d022_comBCS2RStatus 0 "NOT_TESTED_DTC" 1 "PASSED_DTC" 2 "FAILED_DTC" 3 "UNABLE_TO_TEST_DTC";
VAL_ 881 RCM_d023_comBCS2LStatus 0 "NOT_TESTED_DTC" 1 "PASSED_DTC" 2 "FAILED_DTC" 3 "UNABLE_TO_TEST_DTC";
VAL_ 881 RCM_d024_comBCS2CStatus 0 "NOT_TESTED_DTC" 1 "PASSED_DTC" 2 "FAILED_DTC" 3 "UNABLE_TO_TEST_DTC";
VAL_ 881 RCM_d025_comTPMSStatus 0 "NOT_TESTED_DTC" 1 "PASSED_DTC" 2 "FAILED_DTC" 3 "UNABLE_TO_TEST_DTC";
VAL_ 881 RCM_d026_airbagWarnMismatch 0 "NOT_TESTED_DTC" 1 "PASSED_DTC" 2 "FAILED_DTC" 3 "UNABLE_TO_TEST_DTC";
VAL_ 881 RCM_d027_ocsFailure 0 "NOT_TESTED_DTC" 1 "PASSED_DTC" 2 "FAILED_DTC" 3 "UNABLE_TO_TEST_DTC";
VAL_ 881 RCM_d028_comGTWACS 0 "NOT_TESTED_DTC" 1 "PASSED_DTC" 2 "FAILED_DTC" 3 "UNABLE_TO_TEST_DTC";
VAL_ 881 RCM_d029_comChassisBusOff 0 "NOT_TESTED_DTC" 1 "PASSED_DTC" 2 "FAILED_DTC" 3 "UNABLE_TO_TEST_DTC";
VAL_ 881 RCM_d030_comStwAngle 0 "NOT_TESTED_DTC" 1 "PASSED_DTC" 2 "FAILED_DTC" 3 "UNABLE_TO_TEST_DTC";
VAL_ 881 RCM_d031_comESP145 0 "NOT_TESTED_DTC" 1 "PASSED_DTC" 2 "FAILED_DTC" 3 "UNABLE_TO_TEST_DTC";
VAL_ 881 RCM_d032_comDITorque2 0 "NOT_TESTED_DTC" 1 "PASSED_DTC" 2 "FAILED_DTC" 3 "UNABLE_TO_TEST_DTC";
VAL_ 881 RCM_d033_comDITorque1 0 "NOT_TESTED_DTC" 1 "PASSED_DTC" 2 "FAILED_DTC" 3 "UNABLE_TO_TEST_DTC";
VAL_ 881 RCM_d034_comESPB 0 "NOT_TESTED_DTC" 1 "PASSED_DTC" 2 "FAILED_DTC" 3 "UNABLE_TO_TEST_DTC";
VAL_ 881 RCM_d035_comGTWOdo 0 "NOT_TESTED_DTC" 1 "PASSED_DTC" 2 "FAILED_DTC" 3 "UNABLE_TO_TEST_DTC";
VAL_ 881 RCM_d036_comBusOff 0 "NOT_TESTED_DTC" 1 "PASSED_DTC" 2 "FAILED_DTC" 3 "UNABLE_TO_TEST_DTC";
VAL_ 881 RCM_d037_comMissingVehConfg 0 "NOT_TESTED_DTC" 1 "PASSED_DTC" 2 "FAILED_DTC" 3 "UNABLE_TO_TEST_DTC";
VAL_ 881 RCM_d038_seatBackSw2ndRowLeft 0 "NOT_TESTED_DTC" 1 "PASSED_DTC" 2 "FAILED_DTC" 3 "UNABLE_TO_TEST_DTC";
VAL_ 881 RCM_d039_pretenLapFrontRight 0 "NOT_TESTED_DTC" 1 "PASSED_DTC" 2 "FAILED_DTC" 3 "UNABLE_TO_TEST_DTC";
VAL_ 881 RCM_d040_pretenLapFrontLeft 0 "NOT_TESTED_DTC" 1 "PASSED_DTC" 2 "FAILED_DTC" 3 "UNABLE_TO_TEST_DTC";
VAL_ 881 RCM_d041_pretenShldFrontRight 0 "NOT_TESTED_DTC" 1 "PASSED_DTC" 2 "FAILED_DTC" 3 "UNABLE_TO_TEST_DTC";
VAL_ 881 RCM_d042_pretenShldrFrontLeft 0 "NOT_TESTED_DTC" 1 "PASSED_DTC" 2 "FAILED_DTC" 3 "UNABLE_TO_TEST_DTC";
VAL_ 881 RCM_d043_passABLampOnHardWire 0 "NOT_TESTED_DTC" 1 "PASSED_DTC" 2 "FAILED_DTC" 3 "UNABLE_TO_TEST_DTC";
VAL_ 881 RCM_d044_crashDetected 0 "NOT_TESTED_DTC" 1 "PASSED_DTC" 2 "FAILED_DTC" 3 "UNABLE_TO_TEST_DTC";
VAL_ 881 RCM_d045_crashOutSignal 0 "NOT_TESTED_DTC" 1 "PASSED_DTC" 2 "FAILED_DTC" 3 "UNABLE_TO_TEST_DTC";
VAL_ 881 RCM_d046_passengerActiveVent 0 "NOT_TESTED_DTC" 1 "PASSED_DTC" 2 "FAILED_DTC" 3 "UNABLE_TO_TEST_DTC";
VAL_ 881 RCM_d047_kneeABFrontPassenger 0 "NOT_TESTED_DTC" 1 "PASSED_DTC" 2 "FAILED_DTC" 3 "UNABLE_TO_TEST_DTC";
VAL_ 881 RCM_d048_pressureFrontRtDoor 0 "NOT_TESTED_DTC" 1 "PASSED_DTC" 2 "FAILED_DTC" 3 "UNABLE_TO_TEST_DTC";
VAL_ 881 RCM_d049_pressureFrontLftDoor 0 "NOT_TESTED_DTC" 1 "PASSED_DTC" 2 "FAILED_DTC" 3 "UNABLE_TO_TEST_DTC";
VAL_ 881 RCM_d050_eepromDataLocked 0 "NOT_TESTED_DTC" 1 "PASSED_DTC" 2 "FAILED_DTC" 3 "UNABLE_TO_TEST_DTC";
VAL_ 881 RCM_d051_hoodActuatorLeft 0 "NOT_TESTED_DTC" 1 "PASSED_DTC" 2 "FAILED_DTC" 3 "UNABLE_TO_TEST_DTC";
VAL_ 881 RCM_d052_pretenMid2ndRow 0 "NOT_TESTED_DTC" 1 "PASSED_DTC" 2 "FAILED_DTC" 3 "UNABLE_TO_TEST_DTC";
VAL_ 881 RCM_d053_sbsw2ndRowRight 0 "NOT_TESTED_DTC" 1 "PASSED_DTC" 2 "FAILED_DTC" 3 "UNABLE_TO_TEST_DTC";
VAL_ 881 RCM_d054_padLampHardWire 0 "NOT_TESTED_DTC" 1 "PASSED_DTC" 2 "FAILED_DTC" 3 "UNABLE_TO_TEST_DTC";
VAL_ 881 RCM_d055_passResOccupancySw 0 "NOT_TESTED_DTC" 1 "PASSED_DTC" 2 "FAILED_DTC" 3 "UNABLE_TO_TEST_DTC";
VAL_ 881 RCM_d056_stpsDriver 0 "NOT_TESTED_DTC" 1 "PASSED_DTC" 2 "FAILED_DTC" 3 "UNABLE_TO_TEST_DTC";
VAL_ 881 RCM_d057_pasDPillarLeftYAxis 0 "NOT_TESTED_DTC" 1 "PASSED_DTC" 2 "FAILED_DTC" 3 "UNABLE_TO_TEST_DTC";
VAL_ 881 RCM_d058_pasDPillarLeftXAxis 0 "NOT_TESTED_DTC" 1 "PASSED_DTC" 2 "FAILED_DTC" 3 "UNABLE_TO_TEST_DTC";
VAL_ 881 RCM_d059_pasDPillarRight 0 "NOT_TESTED_DTC" 1 "PASSED_DTC" 2 "FAILED_DTC" 3 "UNABLE_TO_TEST_DTC";
VAL_ 881 RCM_d060_pasCPillarRight 0 "NOT_TESTED_DTC" 1 "PASSED_DTC" 2 "FAILED_DTC" 3 "UNABLE_TO_TEST_DTC";
VAL_ 881 RCM_d061_pasBPillarRight 0 "NOT_TESTED_DTC" 1 "PASSED_DTC" 2 "FAILED_DTC" 3 "UNABLE_TO_TEST_DTC";
VAL_ 881 RCM_d062_ufsRightSide 0 "NOT_TESTED_DTC" 1 "PASSED_DTC" 2 "FAILED_DTC" 3 "UNABLE_TO_TEST_DTC";
VAL_ 881 RCM_d063_pasCPillarLeft 0 "NOT_TESTED_DTC" 1 "PASSED_DTC" 2 "FAILED_DTC" 3 "UNABLE_TO_TEST_DTC";
VAL_ 881 RCM_d064_pasBPillarLeft 0 "NOT_TESTED_DTC" 1 "PASSED_DTC" 2 "FAILED_DTC" 3 "UNABLE_TO_TEST_DTC";
VAL_ 881 RCM_d065_ufsLeftSide 0 "NOT_TESTED_DTC" 1 "PASSED_DTC" 2 "FAILED_DTC" 3 "UNABLE_TO_TEST_DTC";
VAL_ 881 RCM_d066_loadLimiterRightSide 0 "NOT_TESTED_DTC" 1 "PASSED_DTC" 2 "FAILED_DTC" 3 "UNABLE_TO_TEST_DTC";
VAL_ 881 RCM_d067_loadLimiterLeftSide 0 "NOT_TESTED_DTC" 1 "PASSED_DTC" 2 "FAILED_DTC" 3 "UNABLE_TO_TEST_DTC";
VAL_ 881 RCM_d068_curAB3rdRowRight 0 "NOT_TESTED_DTC" 1 "PASSED_DTC" 2 "FAILED_DTC" 3 "UNABLE_TO_TEST_DTC";
VAL_ 881 RCM_d069_curAB2ndRowRight 0 "NOT_TESTED_DTC" 1 "PASSED_DTC" 2 "FAILED_DTC" 3 "UNABLE_TO_TEST_DTC";
VAL_ 881 RCM_d070_curAB2ndRowLeft 0 "NOT_TESTED_DTC" 1 "PASSED_DTC" 2 "FAILED_DTC" 3 "UNABLE_TO_TEST_DTC";
VAL_ 881 RCM_d071_preten2ndRowRight 0 "NOT_TESTED_DTC" 1 "PASSED_DTC" 2 "FAILED_DTC" 3 "UNABLE_TO_TEST_DTC";
VAL_ 881 RCM_d072_curAB3rdRowLeft 0 "NOT_TESTED_DTC" 1 "PASSED_DTC" 2 "FAILED_DTC" 3 "UNABLE_TO_TEST_DTC";
VAL_ 881 RCM_d073_preten2ndRowLeft 0 "NOT_TESTED_DTC" 1 "PASSED_DTC" 2 "FAILED_DTC" 3 "UNABLE_TO_TEST_DTC";
VAL_ 881 RCM_d074_siAB2ndRowRight 0 "NOT_TESTED_DTC" 1 "PASSED_DTC" 2 "FAILED_DTC" 3 "UNABLE_TO_TEST_DTC";
VAL_ 881 RCM_d075_siAB2ndRowLeft 0 "NOT_TESTED_DTC" 1 "PASSED_DTC" 2 "FAILED_DTC" 3 "UNABLE_TO_TEST_DTC";
VAL_ 881 RCM_d076_hardwarCodingPin3 0 "NOT_TESTED_DTC" 1 "PASSED_DTC" 2 "FAILED_DTC" 3 "UNABLE_TO_TEST_DTC";
VAL_ 881 RCM_d077_hardwareCodingPin2 0 "NOT_TESTED_DTC" 1 "PASSED_DTC" 2 "FAILED_DTC" 3 "UNABLE_TO_TEST_DTC";
VAL_ 881 RCM_d078_hardwareCodingPin1 0 "NOT_TESTED_DTC" 1 "PASSED_DTC" 2 "FAILED_DTC" 3 "UNABLE_TO_TEST_DTC";
VAL_ 881 RCM_d079_buckleRightSide 0 "NOT_TESTED_DTC" 1 "PASSED_DTC" 2 "FAILED_DTC" 3 "UNABLE_TO_TEST_DTC";
VAL_ 881 RCM_d080_buckleLeftSide 0 "NOT_TESTED_DTC" 1 "PASSED_DTC" 2 "FAILED_DTC" 3 "UNABLE_TO_TEST_DTC";
VAL_ 881 RCM_d081_curAB1stRowRight 0 "NOT_TESTED_DTC" 1 "PASSED_DTC" 2 "FAILED_DTC" 3 "UNABLE_TO_TEST_DTC";
VAL_ 881 RCM_d082_siAB1stRowRight 0 "NOT_TESTED_DTC" 1 "PASSED_DTC" 2 "FAILED_DTC" 3 "UNABLE_TO_TEST_DTC";
VAL_ 881 RCM_d083_curAB1stRowLeft 0 "NOT_TESTED_DTC" 1 "PASSED_DTC" 2 "FAILED_DTC" 3 "UNABLE_TO_TEST_DTC";
VAL_ 881 RCM_d084_siAB1stRowLeft 0 "NOT_TESTED_DTC" 1 "PASSED_DTC" 2 "FAILED_DTC" 3 "UNABLE_TO_TEST_DTC";
VAL_ 881 RCM_d085_pabStage2 0 "NOT_TESTED_DTC" 1 "PASSED_DTC" 2 "FAILED_DTC" 3 "UNABLE_TO_TEST_DTC";
VAL_ 881 RCM_d086_pabStage1 0 "NOT_TESTED_DTC" 1 "PASSED_DTC" 2 "FAILED_DTC" 3 "UNABLE_TO_TEST_DTC";
VAL_ 881 RCM_d087_hvDisconnect 0 "NOT_TESTED_DTC" 1 "PASSED_DTC" 2 "FAILED_DTC" 3 "UNABLE_TO_TEST_DTC";
VAL_ 881 RCM_d088_kneeABDriver 0 "NOT_TESTED_DTC" 1 "PASSED_DTC" 2 "FAILED_DTC" 3 "UNABLE_TO_TEST_DTC";
VAL_ 881 RCM_d089_dabStage2 0 "NOT_TESTED_DTC" 1 "PASSED_DTC" 2 "FAILED_DTC" 3 "UNABLE_TO_TEST_DTC";
VAL_ 881 RCM_d090_dabStage1 0 "NOT_TESTED_DTC" 1 "PASSED_DTC" 2 "FAILED_DTC" 3 "UNABLE_TO_TEST_DTC";
VAL_ 881 RCM_d091_comGTWCarState 0 "NOT_TESTED_DTC" 1 "PASSED_DTC" 2 "FAILED_DTC" 3 "UNABLE_TO_TEST_DTC";
VAL_ 881 RCM_d092_driverOrientation 0 "NOT_TESTED_DTC" 1 "PASSED_DTC" 2 "FAILED_DTC" 3 "UNABLE_TO_TEST_DTC";
VAL_ 881 RCM_d093_scmUnavailable 0 "NOT_TESTED_DTC" 1 "PASSED_DTC" 2 "FAILED_DTC" 3 "UNABLE_TO_TEST_DTC";
VAL_ 881 RCM_d094_comDasControl 0 "NOT_TESTED_DTC" 1 "PASSED_DTC" 2 "FAILED_DTC" 3 "UNABLE_TO_TEST_DTC";
VAL_ 881 RCM_d095_comDasIDF 0 "NOT_TESTED_DTC" 1 "PASSED_DTC" 2 "FAILED_DTC" 3 "UNABLE_TO_TEST_DTC";
VAL_ 881 RCM_d096_comDasStatus 0 "NOT_TESTED_DTC" 1 "PASSED_DTC" 2 "FAILED_DTC" 3 "UNABLE_TO_TEST_DTC";
VAL_ 881 RCM_d097_comDIState 0 "NOT_TESTED_DTC" 1 "PASSED_DTC" 2 "FAILED_DTC" 3 "UNABLE_TO_TEST_DTC";
VAL_ 881 RCM_d098_comDIState2 0 "NOT_TESTED_DTC" 1 "PASSED_DTC" 2 "FAILED_DTC" 3 "UNABLE_TO_TEST_DTC";

VAL_ 849 RCM_infoBuildType 0 "UNKNOWN_BUILD" 1 "PLATFORM_BUILD" 2 "LOCAL_BUILD" 3 "TRACEABLE_CI_BUILD" 4 "MFG_BUILD";

VAL_ 273 RCM_crashAlgoWakeup 0 "INACTIVE" 1 "ACTIVE" 2 "UNUSED";
VAL_ 273 RCM_ndChargerCollision 0 "INACTIVE" 1 "ACTIVE" 2 "UNUSED";
VAL_ 273 RCM_ndFrontCollision 0 "INACTIVE" 1 "ACTIVE" 2 "UNUSED";
VAL_ 273 RCM_ndLeftSideCollision 0 "INACTIVE" 1 "ACTIVE" 2 "UNUSED";
VAL_ 273 RCM_ndPedProEvent 0 "INACTIVE" 1 "ACTIVE" 2 "UNUSED";
VAL_ 273 RCM_ndRearCollision 0 "INACTIVE" 1 "ACTIVE" 2 "UNUSED";
VAL_ 273 RCM_ndRightSideCollision 0 "INACTIVE" 1 "ACTIVE" 2 "UNUSED";
VAL_ 273 RCM_ndRollOverCollision 0 "INACTIVE" 1 "ACTIVE" 2 "UNUSED";

VAL_ 535 RCM_airbagCutoffSwStatus 0 "AIRBAG_ON" 1 "AIRBAG_OFF" 2 "UNUSED" 3 "SNA";
VAL_ 535 RCM_armStatus 0 "UNARMED" 1 "ARMED" 2 "UNUSED" 3 "SNA";
VAL_ 535 RCM_buckle2ndRowStatus 0 "0" 1 "1" 2 "2" 3 "3" 6 "FAULT" 7 "SNA";
VAL_ 535 RCM_buckleDriverStatus 0 "BUCKLE_UNLATCHED" 1 "BUCKLE_LATCHED" 2 "FAULTED" 3 "SNA";
VAL_ 535 RCM_bucklePassengerStatus 0 "BUCKLE_UNLATCHED" 1 "BUCKLE_LATCHED" 2 "FAULTED" 3 "SNA";
VAL_ 535 RCM_chimeState1stRow 0 "OFF" 1 "ON" 2 "UNUSED" 3 "SNA";
VAL_ 535 RCM_driverOrientationInitStatus 0 "INIT_NOT_COMPLETE" 1 "MATCHED_LHD" 2 "MATCHED_RHD" 3 "MISMATCH_DEFAULT_LHD" 4 "MISMATCH_DEFAULT_RHD" 7 "SNA";
VAL_ 535 RCM_edr1State 0 "EMPTY" 1 "STORED" 2 "LOCKED" 3 "SNA";
VAL_ 535 RCM_edr2State 0 "EMPTY" 1 "STORED" 2 "LOCKED" 3 "SNA";
VAL_ 535 RCM_hwConfigPin56 0 "NA_MARKET_GND" 1 "EU_MARKET_FLOATING" 2 "FAULTED" 3 "SNA";
VAL_ 535 RCM_hwConfigPin57 0 "RHD_GROUNDED" 1 "LHD_FLOATING" 2 "FAULTED" 3 "SNA";
VAL_ 535 RCM_hwConfigPin58 0 "GROUNDED" 1 "FLOATING" 2 "FAULTED" 3 "SNA";
VAL_ 535 RCM_passAirbagRequest 0 "OFF" 1 "ON" 2 "UNUSED" 3 "SNA";
VAL_ 535 RCM_passOccupantStatus 0 "UNOCCUPIED" 1 "OCCUPIED" 2 "FAULTED" 3 "SNA";
VAL_ 535 RCM_privateCANStatus 0 "NO_FAULT" 1 "FAULTED" 2 "PAST_HISTORY" 3 "SNA";
VAL_ 535 RCM_publicCANStatus 0 "NO_FAULT" 1 "FAULTED" 2 "PAST_HISTORY" 3 "SNA";
VAL_ 535 RCM_seatTrackPositionDrvr 0 "NEAR" 1 "FAR" 2 "FAULTED" 3 "SNA";
VAL_ 535 RCM_tellTaleDriverState 0 "OFF" 1 "ON" 2 "FLASHING" 3 "SNA";
VAL_ 535 RCM_tellTalePassengerState 0 "OFF" 1 "ON" 2 "FLASHING" 3 "SNA";
VAL_ 535 RCM_vinLearnFlag 0 "NO_VIN_STORED" 1 "VIN_STORED" 2 "UNUSED" 3 "SNA";
VAL_ 535 RCM_warningIndicatorState 0 "OFF" 1 "ON" 2 "UNUSED" 3 "SNA";

VAL_ 561 RLS_active 0 "INACTIVE" 1 "ACTIVE";
VAL_ 561 RLS_autoTimerActive 0 "INACTIVE" 1 "ACTIVE";
VAL_ 561 RLS_hudFrontLight 255 "SNA";
VAL_ 561 RLS_humidity 255 "SNA";
VAL_ 561 RLS_lightRequest 0 "OFF" 1 "ON" 3 "INVALID";
VAL_ 561 RLS_rawLeftSensor 255 "SNA";
VAL_ 561 RLS_rawRightSensor 255 "SNA";
VAL_ 561 RLS_vendor 0 "HELLA" 1 "VALEO" 2 "TESLA" 7 "SNA";
VAL_ 561 RLS_windowTemperature 255 "SNA";
VAL_ 561 RLS_wiperSpeed 0 "OFF" 1 "1" 2 "2" 3 "3" 4 "4" 5 "5" 6 "6" 7 "7" 8 "8" 9 "9" 10 "10" 11 "11" 12 "12" 13 "13" 14 "14" 15 "INVALID";

VAL_ 705 RLS_ambientLightRaw 255 "SNA";
VAL_ 705 RLS_frontLightRaw 255 "SNA";
VAL_ 705 RLS_hudData 1 "TWILIGHT" 2 "DARKNESS" 4 "PRECIPITATION" 8 "TUNNEL" 16 "UNDERGROUND" 32 "HIGH_SPEED" 64 "RANGE_4_CD_PER_M2" 128 "RANGE_40_CD_PER_M2" 255 "INVALID";
VAL_ 705 RLS_versionID 255 "RLS_VERSION_SNA";

VAL_ 515 SC_alarmStatus 0 "disarmed" 1 "armed" 2 "partial_armed" 3 "triggered_flash_active" 4 "alarm_error" 5 "triggered_flash_inactive" 7 "default" 15 "SNA";
VAL_ 515 SC_driverFrontDoorOpenStatus 0 "closed" 1 "open" 2 "on_secondary_latch" 3 "default";
VAL_ 515 SC_driverRearDoorOpenStatus 0 "closed" 1 "open" 2 "on_secondary_latch" 3 "default";
VAL_ 515 SC_frontTrunkStatus 0 "closed" 1 "open" 2 "ambiguous" 3 "default";
VAL_ 515 SC_hazardSwitchStatus 0 "No_request" 1 "Hazard_request" 2 "Not_used" 3 "default";
VAL_ 515 SC_ignitionStatus 0 "Locked" 1 "Sleep" 2 "Awake" 3 "Accessory" 4 "Powertrain_wake" 5 "Ignition" 6 "Crank" 15 "Default";
VAL_ 515 SC_keyChallengeType 0 "encryption algorithm 1";
VAL_ 515 SC_keyFobAuthenticated 0 "NONE" 1 "IN_PROGRESS" 2 "AUTHENTICATED" 3 "SNA";
VAL_ 515 SC_passFrontDoorOpenStatus 0 "closed" 1 "open" 2 "on_secondary_latch" 3 "default";
VAL_ 515 SC_passRearDoorOpenStatus 0 "closed" 1 "open" 2 "on_secondary_latch" 3 "default";
VAL_ 515 SC_rearTrunkStatus 0 "closed" 1 "open" 2 "ambiguous" 3 "default";
VAL_ 515 SC_vehicleLockStatus 0 "RKE_UNLOCKED" 1 "PE_UNLOCKED" 2 "INTERNAL_LOCKED" 3 "RKE_SELECTIVE_UNLOCKED" 4 "PE_SELECTIVE_UNLOCKED" 5 "RKE_LOCKED" 6 "PE_LOCKED" 7 "LOCKSTATUSDEFAULT";
VAL_ 515 SC_vehicleStatus 0 "Vehicle_asleep_engine_stop" 1 "Vehicle_awake_engine_stop" 2 "Ignition_ON_ready_to_start" 3 "Startin_in_progress" 4 "Vehicle_awake_engine_run" 7 "default";
VAL_ 515 SEC_accessViaDeadFob 0 "Inactive" 1 "DSTEntry" 2 "DSTStart";
VAL_ 515 SEC_chargePortRequest 0 "NO_ACTION" 1 "OPEN_CHG_CABLE_RF" 2 "OPEN_KEYFOB" 3 "DEFAULT_SNA";
VAL_ 515 SEC_driverPresent 0 "NOT_PRESENT" 1 "PRESENT";
VAL_ 515 SEC_keyLocation 0 "NOT_PRESENT" 1 "OUTSIDE" 2 "INSIDE" 3 "UNKNOWN" 15 "SNA";
VAL_ 515 SEC_lockRejected 0 "NOT_REJECTED" 1 "REJECTED";
VAL_ 515 SEC_windowRequest 0 "IDLE" 1 "DROP_WINDOWS" 3 "SNA";

VAL_ 531 SC_activeKeyFob 0 "0" 1 "1" 2 "2" 3 "NONE";
VAL_ 531 SC_ftSecondaryLatchReq 0 "NO_ACTION" 1 "PREPARE_TO_UNLATCH" 2 "UNLATCH_NOW" 3 "SNA";
VAL_ 531 SC_indicationRequest 0 "IDLE" 1 "LOCK" 2 "MISLOCK" 3 "UNLOCK" 7 "SNA";
VAL_ 531 SC_keyFob1Battery 0 "NO_INFO" 1 "BATTERY_OK" 2 "BATTERY_LOW" 3 "SNA";
VAL_ 531 SC_keyFob2Battery 0 "NO_INFO" 1 "BATTERY_OK" 2 "BATTERY_LOW" 3 "SNA";
VAL_ 531 SC_keyFob3Battery 0 "NO_INFO" 1 "BATTERY_OK" 2 "BATTERY_LOW" 3 "SNA";
VAL_ 531 SC_keyPollingStatus 0 "POLLING_INACTIVE" 1 "POLLING_TYPE_LOCATION" 2 "POLLING_TYPE_APPROACH" 3 "RESERVED" 4 "RESERVED2" 5 "RESERVED3" 6 "RESERVED4" 7 "SNA";
VAL_ 531 SC_keyPresent 0 "NOT_PRESENT" 1 "PRESENT" 2 "UNKNOWN";
VAL_ 531 SC_lockRequestType 0 "No_new_request" 1 "RKE_lock" 2 "PE_lock" 3 "RKE_unlock" 4 "PE_unlock" 5 "RKE_luggage" 6 "not_used" 7 "default";
VAL_ 531 SC_remoteAccessState 0 "NO_KEY" 1 "NORMAL" 2 "RESET" 3 "LOCKED";
VAL_ 531 SC_windowControlAvailable 0 "NOTHING" 1 "NOT_AVAILABLE" 2 "AVAILABLE" 3 "SNA";
VAL_ 531 SEC_intSwitchFrontTrunkOpenReq 0 "UNPRESSED" 1 "PRESSED" 2 "FAULT" 3 "SNA";
VAL_ 531 SEC_keyFrontTrunkOpenReq 0 "UNPRESSED" 1 "PRESSED" 2 "FAULT" 3 "SNA";

VAL_ 576 SC_keyfobButton1 0 "UNPRESSED" 1 "PRESSED" 2 "FAULT" 3 "SNA";
VAL_ 576 SC_keyfobButton2 0 "UNPRESSED" 1 "PRESSED" 2 "FAULT" 3 "SNA";
VAL_ 576 SC_keyfobButton3 0 "UNPRESSED" 1 "PRESSED" 2 "FAULT" 3 "SNA";

VAL_ 513 SDM_airbagCutoffSwStatus 0 "AIRBAG_ON" 1 "AIRBAG_OFF" 2 "SNA" 3 "UNUSED";
VAL_ 513 SDM_buckle2ndRowStatus 0 "0" 1 "1" 2 "2" 3 "3";
VAL_ 513 SDM_buckleDriverStatus 0 "BUCKLE_UNLATCHED" 1 "BUCKLE_LATCHED" 2 "FAULTED" 3 "SNA";
VAL_ 513 SDM_bucklePassengerStatus 0 "BUCKLE_UNLATCHED" 1 "BUCKLE_LATCHED" 2 "FAULTED" 3 "SNA";
VAL_ 513 SDM_frontChimeState 0 "OFF" 1 "ON";
VAL_ 513 SDM_ocsSerialNumberRx 0 "NOT_RECEIVED" 1 "RECEIVED";
VAL_ 513 SDM_padLampState 0 "OFF" 1 "ON" 2 "UNUSED" 3 "SNA";
VAL_ 513 SDM_pedProEquiped 0 "NO_PEDPRO" 1 "PEDPRO_EQUIPED";
VAL_ 513 SDM_rearChimeState 0 "OFF" 1 "ON";
VAL_ 513 SDM_tellTale2ndRowState 0 "OFF" 1 "ON" 2 "FLASHING" 3 "SNA";
VAL_ 513 SDM_tellTaleDriverState 0 "OFF" 1 "ON" 2 "FLASHING" 3 "SNA";
VAL_ 513 SDM_tellTalePassengerState 0 "OFF" 1 "ON" 2 "FLASHING" 3 "SNA";
VAL_ 513 SDM_warningIndicatorState 0 "OFF" 1 "ON" 2 "DEPLOYMENT_NOT_ENABLED" 3 "SNA";

VAL_ 25 SDM_crashSeverity 0 "NON_DEPLOY" 1 "PRETENSIONER" 2 "FIRST_STAGE" 3 "SECOND_STAGE";
VAL_ 25 SDM_frontCrash 0 "NOT_CRASH" 1 "CRASH";
VAL_ 25 SDM_leftSideCrash 0 "NOT_CRASH" 1 "CRASH";
VAL_ 25 SDM_pedProEvent 0 "NO_EVENT" 1 "EVENT";
VAL_ 25 SDM_rearCrash 0 "NOT_CRASH" 1 "CRASH";
VAL_ 25 SDM_rightSideCrash 0 "NOT_CRASH" 1 "CRASH";
VAL_ 25 SDM_rollOverCrash 0 "NOT_CRASH" 1 "CRASH";

VAL_ 547 SC_handleFLCommand 0 "Unused" 1 "Retract" 2 "Present" 3 "SNA";

VAL_ 1315 SEC_componentBranchOrigin 254 "LOCAL_BUILD" 255 "SNA";
VAL_ 1315 SEC_componentHardwareRevision 254 "LOCAL_BUILD" 255 "SNA";
VAL_ 1315 SEC_componentMajorVersion 254 "LOCAL_BUILD" 255 "SNA";
VAL_ 1315 SEC_componentMaturity 254 "LOCAL_BUILD" 255 "SNA";
VAL_ 1315 SEC_componentSvn 16777215 "SNA";
VAL_ 1315 SEC_platformType 254 "LOCAL_BUILD" 255 "SNA";

VAL_ 1317 SNSCLL1_infoIndex 0 "DEPRECATED_0" 1 "DEPRECATED_1" 2 "DEPRECATED_2" 3 "DEPRECATED_3" 4 "DEPRECATED_4" 5 "DEPRECATED_5" 6 "DEPRECATED_6" 7 "DEPRECATED_7" 8 "DEPRECATED_8" 9 "DEPRECATED_9" 10 "BUILD_HWID_COMPONENTID" 11 "PCBAID_ASSYID_USAGEID" 13 "APP_CRC" 14 "BOOTLOADER_SVN" 15 "BOOTLOADER_CRC" 16 "SUBCOMPONENT" 17 "APP_GITHASH" 18 "BOOTLOADER_GITHASH" 19 "VERSION_DEPRECATED" 20 "UDS_PROTOCOL_BOOTCRC" 255 "END";
VAL_ 1317 SNSCLL1_infoBuildType 0 "UNKNOWN_BUILD" 1 "PLATFORM_BUILD" 2 "LOCAL_BUILD" 3 "TRACEABLE_CI_BUILD" 4 "MFG_BUILD";
VAL_ 1317 SNSCLL1_infoAssemblyID 1 "ASSEMBLY1" 255 "ASSEMBLY_SNA";

VAL_ 1318 SNSCLR1_infoIndex 0 "DEPRECATED_0" 1 "DEPRECATED_1" 2 "DEPRECATED_2" 3 "DEPRECATED_3" 4 "DEPRECATED_4" 5 "DEPRECATED_5" 6 "DEPRECATED_6" 7 "DEPRECATED_7" 8 "DEPRECATED_8" 9 "DEPRECATED_9" 10 "BUILD_HWID_COMPONENTID" 11 "PCBAID_ASSYID_USAGEID" 13 "APP_CRC" 14 "BOOTLOADER_SVN" 15 "BOOTLOADER_CRC" 16 "SUBCOMPONENT" 17 "APP_GITHASH" 18 "BOOTLOADER_GITHASH" 19 "VERSION_DEPRECATED" 20 "UDS_PROTOCOL_BOOTCRC" 255 "END";
VAL_ 1318 SNSCLR1_infoBuildType 0 "UNKNOWN_BUILD" 1 "PLATFORM_BUILD" 2 "LOCAL_BUILD" 3 "TRACEABLE_CI_BUILD" 4 "MFG_BUILD";
VAL_ 1318 SNSCLR1_infoAssemblyID 1 "ASSEMBLY1" 255 "ASSEMBLY_SNA";

VAL_ 1319 SNSCUL1_infoIndex 0 "DEPRECATED_0" 1 "DEPRECATED_1" 2 "DEPRECATED_2" 3 "DEPRECATED_3" 4 "DEPRECATED_4" 5 "DEPRECATED_5" 6 "DEPRECATED_6" 7 "DEPRECATED_7" 8 "DEPRECATED_8" 9 "DEPRECATED_9" 10 "BUILD_HWID_COMPONENTID" 11 "PCBAID_ASSYID_USAGEID" 13 "APP_CRC" 14 "BOOTLOADER_SVN" 15 "BOOTLOADER_CRC" 16 "SUBCOMPONENT" 17 "APP_GITHASH" 18 "BOOTLOADER_GITHASH" 19 "VERSION_DEPRECATED" 20 "UDS_PROTOCOL_BOOTCRC" 255 "END";
VAL_ 1319 SNSCUL1_infoBuildType 0 "UNKNOWN_BUILD" 1 "PLATFORM_BUILD" 2 "LOCAL_BUILD" 3 "TRACEABLE_CI_BUILD" 4 "MFG_BUILD";
VAL_ 1319 SNSCUL1_infoAssemblyID 1 "ASSEMBLY1" 255 "ASSEMBLY_SNA";

VAL_ 1320 SNSCUR1_infoIndex 0 "DEPRECATED_0" 1 "DEPRECATED_1" 2 "DEPRECATED_2" 3 "DEPRECATED_3" 4 "DEPRECATED_4" 5 "DEPRECATED_5" 6 "DEPRECATED_6" 7 "DEPRECATED_7" 8 "DEPRECATED_8" 9 "DEPRECATED_9" 10 "BUILD_HWID_COMPONENTID" 11 "PCBAID_ASSYID_USAGEID" 13 "APP_CRC" 14 "BOOTLOADER_SVN" 15 "BOOTLOADER_CRC" 16 "SUBCOMPONENT" 17 "APP_GITHASH" 18 "BOOTLOADER_GITHASH" 19 "VERSION_DEPRECATED" 20 "UDS_PROTOCOL_BOOTCRC" 255 "END";
VAL_ 1320 SNSCUR1_infoBuildType 0 "UNKNOWN_BUILD" 1 "PLATFORM_BUILD" 2 "LOCAL_BUILD" 3 "TRACEABLE_CI_BUILD" 4 "MFG_BUILD";
VAL_ 1320 SNSCUR1_infoAssemblyID 1 "ASSEMBLY1" 255 "ASSEMBLY_SNA";

VAL_ 685 DTR_Dist_Rq 0 "ACC_DIST_1" 33 "ACC_DIST_2" 66 "ACC_DIST_3" 100 "ACC_DIST_4" 133 "ACC_DIST_5" 166 "ACC_DIST_6" 200 "ACC_DIST_7" 255 "SNA";
VAL_ 685 HiBmLvr_Stat 0 "IDLE" 1 "HIBM_ON_PSD" 2 "HIBM_FLSH_ON_PSD" 3 "SNA";
VAL_ 685 HrnSw_Psd 0 "NPSD" 1 "PSD" 2 "NDEF2" 3 "SNA";
VAL_ 685 SpdCtrlLvr_Stat 0 "IDLE" 1 "FWD" 2 "RWD" 4 "UP_2ND" 8 "DN_2ND" 16 "UP_1ST" 32 "DN_1ST";
VAL_ 685 StW_Cond_Psd 0 "NPSD" 1 "UP" 2 "DOWN" 3 "SNA";
VAL_ 685 StW_Lvr_Stat 0 "NPSD" 1 "STW_UP" 2 "STW_DOWN" 3 "STW_FWD" 4 "STW_BACK";
VAL_ 685 StW_Sw00_Psd 0 "NOT_PRESSED" 1 "PRESSED";
VAL_ 685 StW_Sw01_Psd 0 "NOT_PRESSED" 1 "PRESSED";
VAL_ 685 StW_Sw03_Psd 0 "NOT_PRESSED" 1 "PRESSED";
VAL_ 685 StW_Sw04_Psd 0 "NOT_PRESSED" 1 "PRESSED";
VAL_ 685 TurnIndLvr_Stat 0 "IDLE" 1 "LEFT" 2 "RIGHT" 3 "SNA";
VAL_ 685 WprSw6Posn 0 "OFF" 1 "INTERVAL1" 2 "INTERVAL2" 3 "INTERVAL3" 4 "INTERVAL4" 5 "STAGE1" 6 "STAGE2" 7 "SNA";
VAL_ 685 WprWashSw_Psd 0 "NPSD" 1 "TIPWIPE" 2 "WASH" 3 "SNA";
VAL_ 685 WprWash_R_Sw_Posn_V2 0 "OFF" 1 "INTERVAL" 2 "WASH" 3 "SNA";

VAL_ 138 StW_AnglHP 16383 "SNA";
VAL_ 138 StW_AnglHP_Spd 16383 "SNA";

VAL_ 526 SUN_misuseInhibit 0 "FALSE" 1 "TRUE";
VAL_ 526 SUN_movementStatus 0 "IDLE" 1 "CLOSING" 2 "CLOSING_LEFT" 3 "CLOSING_RIGHT" 4 "OPENING" 5 "OPENING_LEFT" 6 "OPENING_RIGHT" 7 "SNA";
VAL_ 526 SUN_panelStatus 0 "IDLE" 1 "CLOSING" 2 "STALLED_CLOSE" 3 "OPENING" 4 "STALLED_OPEN" 5 "SETTLING" 6 "FAULT" 7 "STATUS_SNA";

VAL_ 1310 SUN_componentBranchOrigin 254 "LOCAL_BUILD" 255 "SNA";
VAL_ 1310 SUN_componentHardwareRevision 254 "LOCAL_BUILD" 255 "SNA";
VAL_ 1310 SUN_componentMajorVersion 254 "LOCAL_BUILD" 255 "SNA";
VAL_ 1310 SUN_componentMaturity 254 "LOCAL_BUILD" 255 "SNA";
VAL_ 1310 SUN_componentSvn 16777215 "SNA";
VAL_ 1310 SUN_platformType 254 "LOCAL_BUILD" 255 "SNA";

VAL_ 1292 TAS2_matrixIndex 0 "AlertMatrix0" 1 "AlertMatrix1" 2 "AlertMatrix2" 3 "AlertMatrix3" 4 "AlertMatrix4";

VAL_ 545 TAS_levelFLfiltered 255 "SNA";
VAL_ 545 TAS_levelFLraw 255 "SNA";
VAL_ 545 TAS_levelFRfiltered 255 "SNA";
VAL_ 545 TAS_levelFRraw 255 "SNA";
VAL_ 545 TAS_levelRLfiltered 255 "SNA";
VAL_ 545 TAS_levelRLraw 255 "SNA";
VAL_ 545 TAS_levelRRfiltered 255 "SNA";
VAL_ 545 TAS_levelRRraw 255 "SNA";

VAL_ 1307 TAS_infoIndex 0 "DEPRECATED_0" 1 "DEPRECATED_1" 2 "DEPRECATED_2" 3 "DEPRECATED_3" 4 "DEPRECATED_4" 5 "DEPRECATED_5" 6 "DEPRECATED_6" 7 "DEPRECATED_7" 8 "DEPRECATED_8" 9 "DEPRECATED_9" 10 "BUILD_HWID_COMPONENTID" 11 "PCBAID_ASSYID_USAGEID" 13 "APP_CRC" 14 "BOOTLOADER_SVN" 15 "BOOTLOADER_CRC" 16 "SUBCOMPONENT1" 17 "APP_GITHASH" 18 "BOOTLOADER_GITHASH" 19 "VERSION_DEPRECATED" 20 "UDS_PROTOCOL_BOOTCRC" 23 "SUBCOMPONENT2" 24 "SUBCOMPONENT3" 31 "SUBCOMPONENT4" 255 "END";
VAL_ 1307 TAS_infoBuildType 0 "UNKNOWN_BUILD" 1 "PLATFORM_BUILD" 2 "LOCAL_BUILD" 3 "TRACEABLE_CI_BUILD" 4 "MFG_BUILD";
VAL_ 1307 TAS_infoAssemblyId 1 "ASSEMBLY1" 255 "ASSEMBLY_SNA";
VAL_ 1307 TAS_infoMajorVersion 254 "LOCAL_BUILD" 255 "SNA";
VAL_ 1307 TAS_infoBranchOrigin 254 "LOCAL_BUILD" 255 "SNA";
VAL_ 1307 TAS_infoMaturity 254 "LOCAL_BUILD" 255 "SNA";
VAL_ 1307 TAS_infoHardwareRevision 254 "LOCAL_BUILD" 255 "SNA";

VAL_ 555 TAS_closureRestriction 0 "NOT_DETECTED" 1 "DETECTED";
VAL_ 555 TAS_currentLevel 0 "NOT_DEFINED_0" 1 "NOT_DEFINED_1" 2 "NOT_DEFINED_2" 3 "LOW_LEVEL" 4 "STANDARD_LEVEL" 5 "HIGH_LEVEL" 6 "VERY_HIGH_LEVEL" 7 "VERY_LOW_LEVEL";
VAL_ 555 TAS_detectedJack 0 "NOT_DETECTED" 1 "DETECTED";
VAL_ 555 TAS_detectedLean 0 "NOT_DETECTED" 1 "DETECTED";
VAL_ 555 TAS_detectedTwist 0 "NOT_DETECTED" 1 "DETECTED";
VAL_ 555 TAS_levelingItem 0 "FL_CORNER" 1 "FR_CORNER" 2 "RL_CORNER" 3 "RR_CORNER" 4 "FRONT_AXLE" 5 "REAR_AXLE" 6 "NONE";
VAL_ 555 TAS_levelingType 0 "NOT_LEVELING" 1 "AXLE_LEVELING" 2 "CORNER_LEVELING" 3 "PRESSURE_LEVELING";
VAL_ 555 TAS_mode 0 "NONE" 1 "INIT" 2 "CALIBRATE" 3 "TEST" 4 "READY" 5 "LOADING" 6 "DRIVE" 7 "STOPPING";
VAL_ 555 TAS_pressureFL 31 "SNA";
VAL_ 555 TAS_pressureFR 31 "SNA";
VAL_ 555 TAS_pressureGallery 63 "SNA";
VAL_ 555 TAS_pressureRL 31 "SNA";
VAL_ 555 TAS_pressureRR 31 "SNA";
VAL_ 555 TAS_pressureReservoir 63 "SNA";
VAL_ 555 TAS_runMode 0 "INIT" 1 "SYSTEM_CHECK" 2 "SERVICE" 3 "ASSEMBLY" 4 "DAN" 5 "NORMAL" 6 "LOW_POWER";
VAL_ 555 TAS_state 0 "IDLE" 1 "READ_P_RESERVOIR" 2 "MANUAL_SPRING_CONTROL" 3 "EXHAUST_GALLERY" 4 "COMPRESSOR_RAMPUP" 5 "COMPRESSOR_PREFILL_GALLERY" 6 "FILL_RESERVOIR_FROM_COMPRESSOR" 7 "FILL_SPRING_FROM_COMPRESSOR" 8 "FILL_SPRING_FROM_BOOST" 9 "FILL_SPRING_FROM_RESERVOIR" 10 "FILL_SPRING_RESERVOIR_FROM_COMPRESSOR" 11 "LOWER_SPRING" 12 "EMPTY_RESERVOIR";
VAL_ 555 TAS_targetLevel 0 "NOT_DEFINED_0" 1 "NOT_DEFINED_1" 2 "NOT_DEFINED_2" 3 "LOW_LEVEL" 4 "STANDARD_LEVEL" 5 "HIGH_LEVEL" 6 "VERY_HIGH_LEVEL" 7 "VERY_LOW_LEVEL";

VAL_ 53 THC_MCUDefogInd_Flag 0 "OFF" 1 "DEFOG" 2 "MAX_DEFOG" 3 "AUTO_DEFOG";
VAL_ 53 THC_MCUIntakeInd_Flag 0 "FRESH" 1 "FRESH_OFF_RECIRC" 2 "AUTO";
VAL_ 53 THC_MCUModeDis_Flag 1 "Panel" 2 "PanelAndFloor" 3 "Floor" 4 "FloorAndDef" 5 "Defrost" 6 "AllMode" 7 "PanelAndDef";

VAL_ 682 THC_auxBlowerSegDisplay 0 "OFF" 1 "SPEED_1" 2 "SPEED_2" 3 "SPEED_3" 4 "SPEED_4" 5 "SPEED_5" 6 "SPEED_6" 7 "SPEED_7";
VAL_ 682 THC_auxEvapTemp_DegC 255 "SNA";
VAL_ 682 THC_auxOutletTemp_DegC 255 "SNA";

VAL_ 618 THC_batHeaterStartupState 0 "START_COOLANT_RECIRC" 1 "START_BAT_INLET_T_CMP" 2 "START_TEMP_CHECK_10s" 3 "START_TEMP_CHECK_15s" 4 "START_TEMP_CHECK_20s" 5 "START_TEMP_CHECK_60s" 6 "START_RETRY_DELAY" 7 "STRT_NO_COOLNT_DISABL" 8 "START_LAST";
VAL_ 618 THC_batteryHeaterState 0 "OFF" 1 "STARTUP" 2 "BAT_IN_HEAT_CK" 3 "RUN" 4 "OVERTEMP" 5 "SUSPENDED" 6 "HVLIMITED" 7 "SNA";
VAL_ 618 THC_batteryHeaterTemp 2047 "SNA";

VAL_ 522 THC_cabinACCoolingPct 127 "SNA";
VAL_ 522 THC_chillerCoolingPct 127 "SNA";
VAL_ 522 THC_compCoolingReqPct 127 "SNA";
VAL_ 522 THC_compressorPower 63 "SNA";
VAL_ 522 THC_compressorState 0 "OFF" 1 "START_RAMP" 2 "START" 3 "RUN" 4 "SUSPENDED_LP" 5 "SUSPENDED_HP" 6 "SUSPENDED_DISCH_OT" 7 "SUSPENDED_HIGH_COMP_TEMP" 8 "SUSPENDED_FAULT" 9 "PRESSURE_SENSOR_FAULT" 10 "INHIBITED" 11 "STATE_SNA" 12 "SUSPENDED_SUCT_PRESS" 15 "TEMP_SENSOR_FAULT";
VAL_ 522 THC_condFanLeftReqPct 127 "SNA";
VAL_ 522 THC_condFanRightReqPct 127 "SNA";
VAL_ 522 THC_refrigerantPressure 255 "SNA";

VAL_ 778 THC_chillerBypassYMaxUCPct 127 "SNA";
VAL_ 778 THC_chillerCompArbState 0 "COMP_DMND_NONE" 1 "COMP_DMND_EVAP_ONLY" 2 "COMP_DMND_CHILLER_ONLY" 3 "COMP_DMND_BOTH" 4 "COMP_DMND_BOTH_EVAP_MAX" 5 "COMP_DMND_BOTH_EVAP_MX_CHIL_MX" 6 "COMP_DMND_BOTH_CHILLER_MAX_EMERG" 7 "PRECHILL" 8 "POSTCHILL";
VAL_ 778 THC_chillerMode 0 "NO_FLOW" 1 "ADJUSTED_FLOW_BY_BAT_T" 2 "ADJUSTED_FLOW_BY_EVAP_T" 3 "FULL_FLOW";
VAL_ 778 THC_coolantBatFlowPct 127 "SNA";
VAL_ 778 THC_desiredMode 0 "SERIES_MODE" 1 "PARALLEL_MODE" 2 "PARALLEL_MODE_PRECHILL";
VAL_ 778 THC_mode 0 "SERIES_MODE" 1 "PARALLEL_MODE" 2 "PARALLEL_MODE_PRECHILL";
VAL_ 778 THC_previousMode 0 "SERIES_MODE" 1 "PARALLEL_MODE" 2 "PARALLEL_MODE_PRECHILL";

VAL_ 21 THC_PTActiveTargetSource 0 "OUT_OF_RANGE_LOW" 1 "DRIVE_INVERTER" 2 "CHARGER" 3 "EXTERNAL";
VAL_ 21 THC_PTInletActiveTargetT 63 "SNA";
VAL_ 21 THC_PTInletPassiveTargetT 63 "SNA";
VAL_ 21 THC_PTPassiveTargetSource 0 "OUT_OF_RANGE_LOW" 1 "DRIVE_INVERTER" 2 "CHARGER" 3 "EXTERNAL";
VAL_ 21 THC_coolantBatInletT 1023 "SNA";
VAL_ 21 THC_coolantBatOutletT 1023 "SNA";
VAL_ 21 THC_coolantPTInletT 2047 "SNA";
VAL_ 21 THC_coolantPTOutletT 2047 "SNA";

VAL_ 1610 THC_d0001_tempSnsPTIn 0 "NOT_TESTED" 1 "PASS" 2 "FAIL" 3 "NOT_TESTABLE";
VAL_ 1610 THC_d0002_tempSnsBatIn 0 "NOT_TESTED" 1 "PASS" 2 "FAIL" 3 "NOT_TESTABLE";
VAL_ 1610 THC_d0003_cabinPTCRHeater 0 "NOT_TESTED" 1 "PASS" 2 "FAIL" 3 "NOT_TESTABLE";
VAL_ 1610 THC_d0004_pumpPT 0 "NOT_TESTED" 1 "PASS" 2 "FAIL" 3 "NOT_TESTABLE";
VAL_ 1610 THC_d0005_pumpBat1 0 "NOT_TESTED" 1 "PASS" 2 "FAIL" 3 "NOT_TESTABLE";
VAL_ 1610 THC_d0006_pumpBat2 0 "NOT_TESTED" 1 "PASS" 2 "FAIL" 3 "NOT_TESTABLE";
VAL_ 1610 THC_d0007_valveRadByp 0 "NOT_TESTED" 1 "PASS" 2 "FAIL" 3 "NOT_TESTABLE";
VAL_ 1610 THC_d0008_valveChilByp 0 "NOT_TESTED" 1 "PASS" 2 "FAIL" 3 "NOT_TESTABLE";
VAL_ 1610 THC_d0009_valveParallel 0 "NOT_TESTED" 1 "PASS" 2 "FAIL" 3 "NOT_TESTABLE";
VAL_ 1610 THC_d0010_compressor 0 "NOT_TESTED" 1 "PASS" 2 "FAIL" 3 "NOT_TESTABLE";
VAL_ 1610 THC_d0011_presSnsDis 0 "NOT_TESTED" 1 "PASS" 2 "FAIL" 3 "NOT_TESTABLE";
VAL_ 1610 THC_d0012_presSnsSuct 0 "NOT_TESTED" 1 "PASS" 2 "FAIL" 3 "NOT_TESTABLE";
VAL_ 1610 THC_d0013_coolantHeater 0 "NOT_TESTED" 1 "PASS" 2 "FAIL" 3 "NOT_TESTABLE";
VAL_ 1610 THC_d0014_coolant 0 "NOT_TESTED" 1 "PASS" 2 "FAIL" 3 "NOT_TESTABLE";
VAL_ 1610 THC_d0015_cabinPTCHeater 0 "NOT_TESTED" 1 "PASS" 2 "FAIL" 3 "NOT_TESTABLE";
VAL_ 1610 THC_d0016_chiller 0 "NOT_TESTED" 1 "PASS" 2 "FAIL" 3 "NOT_TESTABLE";
VAL_ 1610 THC_d0017_evaporator 0 "NOT_TESTED" 1 "PASS" 2 "FAIL" 3 "NOT_TESTABLE";
VAL_ 1610 THC_d0018_activeAero 0 "NOT_TESTED" 1 "PASS" 2 "FAIL" 3 "NOT_TESTABLE";
VAL_ 1610 THC_d0019_RCCMComm 0 "NOT_TESTED" 1 "PASS" 2 "FAIL" 3 "NOT_TESTABLE";
VAL_ 1610 THC_d0020_RCCMTempSnsAmb 0 "NOT_TESTED" 1 "PASS" 2 "FAIL" 3 "NOT_TESTABLE";
VAL_ 1610 THC_d0021_RCCMActuator 0 "NOT_TESTED" 1 "PASS" 2 "FAIL" 3 "NOT_TESTABLE";
VAL_ 1610 THC_d0022_RCCMSensor 0 "NOT_TESTED" 1 "PASS" 2 "FAIL" 3 "NOT_TESTABLE";
VAL_ 1610 THC_d0023_THCFailure 0 "NOT_TESTED" 1 "PASS" 2 "FAIL" 3 "NOT_TESTABLE";
VAL_ 1610 THC_d0024_refrigSystem 0 "NOT_TESTED" 1 "PASS" 2 "FAIL" 3 "NOT_TESTABLE";
VAL_ 1610 THC_d0025_pumpPT2 0 "NOT_TESTED" 1 "PASS" 2 "FAIL" 3 "NOT_TESTABLE";
VAL_ 1610 THC_d0026_hvacIonizer 0 "NOT_TESTED" 1 "PASS" 2 "FAIL" 3 "NOT_TESTABLE";
VAL_ 1610 THC_d0027_coolingFan 0 "NOT_TESTED" 1 "PASS" 2 "FAIL" 3 "NOT_TESTABLE";
VAL_ 1610 THC_d0028_incarTempSns 0 "NOT_TESTED" 1 "PASS" 2 "FAIL" 3 "NOT_TESTABLE";

VAL_ 842 THC_heaterPWM 127 "SNA";

VAL_ 1322 THC_hvacStatusMultiplex 0 "0" 1 "1" 2 "2" 3 "3" 4 "4";
VAL_ 1322 THC_occupantHeatLoad -128 "SNA";
VAL_ 1322 THC_leftTargetDischTemp 255 "SNA";
VAL_ 1322 THC_rightTargetDischTemp 255 "SNA";
VAL_ 1322 THC_rearAirMassTempEst 255 "SNA";
VAL_ 1322 THC_windshieldTempEst 255 "SNA";
VAL_ 1322 THC_dasHeaterTempEst 255 "SNA";
VAL_ 1322 THC_airMassTempEst 1023 "SNA";
VAL_ 1322 THC_evapTargetT 15 "SNA";
VAL_ 1322 THC_deliveredConvection 255 "SNA";
VAL_ 1322 THC_targetConvection 255 "SNA";
VAL_ 1322 THC_glassRoofTempEst 255 "SNA";
VAL_ 1322 THC_actualSetTempTarget 255 "SNA";
VAL_ 1322 THC_incidentAirTemp 255 "SNA";
VAL_ 1322 THC_actualSolarLoadEst 32767 "SNA";

VAL_ 1626 THC_infoIndex 0 "DEPRECATED_0" 1 "DEPRECATED_1" 2 "DEPRECATED_2" 3 "DEPRECATED_3" 4 "DEPRECATED_4" 5 "DEPRECATED_5" 6 "DEPRECATED_6" 7 "DEPRECATED_7" 8 "DEPRECATED_8" 9 "DEPRECATED_9" 10 "BUILD_HWID_COMPONENTID" 11 "PCBAID_ASSYID_USAGEID" 13 "APP_CRC" 14 "BOOTLOADER_SVN" 15 "BOOTLOADER_CRC" 16 "SUBCOMPONENT" 17 "APP_GITHASH" 18 "BOOTLOADER_GITHASH" 19 "VERSION_DEPRECATED" 20 "UDS_PROTOCOL_BOOTCRC" 255 "END";

VAL_ 858 THC_HVPowerLimit 65535 "SNA";
VAL_ 858 THC_totalPowerConsumed12V 511 "SNA";
VAL_ 858 THC_totalPowerConsumedHV 4095 "SNA";

VAL_ 810 THC_PTPump2Pct 127 "SNA";
VAL_ 810 THC_PTPumpPct 127 "SNA";
VAL_ 810 THC_batteryHeaterPct 127 "SNA";
VAL_ 810 THC_batteryPump1Pct 127 "SNA";
VAL_ 810 THC_batteryPump2Pct 127 "SNA";
VAL_ 810 THC_cabinHeaterPct 127 "SNA";
VAL_ 810 THC_chillerBypassValvePct 127 "SNA";
VAL_ 810 THC_radBypassValvePct 127 "SNA";

VAL_ 826 THC_ambientTempFiltered 255 "SNA";
VAL_ 826 THC_condenserFanPct 127 "SNA";
VAL_ 826 THC_fanPct 127 "SNA";
VAL_ 826 THC_radiatorFanPct 127 "SNA";
VAL_ 826 THC_refrigDischargeTemp 2047 "SNA";
VAL_ 826 THC_refrigSuctionPressure 127 "SNA";
VAL_ 826 THC_refrigSuctionTemp 255 "SNA";

VAL_ 874 THC_fanLeftPwmOut 127 "SNA";
VAL_ 874 THC_fanRightPwmOut 127 "SNA";
VAL_ 874 THC_louverLeftPosition 127 "SNA";
VAL_ 874 THC_louverRightPosition 127 "SNA";
VAL_ 874 THC_radiatorOutletTemp 2047 "SNA";
VAL_ 874 THC_throatLeftPosition 127 "SNA";
VAL_ 874 THC_throatRightPosition 127 "SNA";

VAL_ 890 THC_boardTemp 255 "SNA";
VAL_ 890 THC_chillerBypassValvePos 127 "SNA";
VAL_ 890 THC_modeValveParallelPos 127 "SNA";
VAL_ 890 THC_radBypassValvePos 127 "SNA";

VAL_ 922 THC_BMSInletActiveTargetT 127 "SNA";
VAL_ 922 THC_BMSInletHeatTargetT 127 "SNA";
VAL_ 922 THC_BMSInletPassiveTargetT 127 "SNA";
VAL_ 922 THC_PT2PumpPctReq 127 "SNA";
VAL_ 922 THC_PTPumpPctReq 127 "SNA";
VAL_ 922 THC_batteryPump1PctReq 127 "SNA";
VAL_ 922 THC_batteryPump2PctReq 127 "SNA";
VAL_ 922 THC_pcbID 0 "UNKNOWN" 1 "THC_BETA2" 2 "THC_PCBAID2";
VAL_ 922 THC_refrigerantPressTarget 31 "SNA";

VAL_ 1002 THC_componentBranchOrigin 254 "LOCAL_BUILD" 255 "SNA";
VAL_ 1002 THC_componentHardwareRevision 252 "CONFIGURABLE_HWID_PLACEHOLDER";
VAL_ 1002 THC_componentMajorVersion 254 "LOCAL_BUILD" 255 "SNA";
VAL_ 1002 THC_componentMaturity 254 "LOCAL_BUILD" 255 "SNA";
VAL_ 1002 THC_platformBranchOrigin 254 "LOCAL_BUILD" 255 "SNA";
VAL_ 1002 THC_platformMajorVersion 254 "LOCAL_BUILD" 255 "SNA";
VAL_ 1002 THC_platformMaturity 254 "LOCAL_BUILD" 255 "SNA";
VAL_ 1002 THC_platformType 254 "LOCAL_BUILD" 255 "SNA";

VAL_ 2029 TOOL_forceEasOn 0 "FALSE_SNA" 1 "TRUE";
VAL_ 2029 TOOL_homelinkCountry 0 "SNA";

VAL_ 2030 TOOL_enum 4294967295 "TOOL_SNA" 0 "TOOL_CONNECTED" 1 "TOOL_DISCONNECTING" 65536 "LOG_UPLOAD" 65537 "LOG_UPLOAD_OK" 65552 "LOG_UPLOAD_FAILED" 131072 "FIRMWARE_DOWNLOAD" 131073 "FIRMWARE_DOWNLOAD_OK" 131088 "FIRMWARE_DOWNLOAD_FAILED" 196608 "CLEAR_DTC_BDY" 196609 "CLEAR_DTC_BDY_OK" 196624 "CLEAR_DTC_BDY_FAILED" 196864 "CLEAR_DTC_BMS" 196865 "CLEAR_DTC_BMS_OK" 196880 "CLEAR_DTC_BMS_FAILED" 197120 "CLEAR_DTC_CHG" 197121 "CLEAR_DTC_CHG_OK" 197136 "CLEAR_DTC_CHG_FAILED" 197376 "CLEAR_DTC_CHGS" 197377 "CLEAR_DTC_CHGS_OK" 197392 "CLEAR_DTC_CHGS_FAILED" 197632 "CLEAR_DTC_CP" 197633 "CLEAR_DTC_CP_OK" 197648 "CLEAR_DTC_CP_FAILED" 197888 "CLEAR_DTC_DCDC" 197889 "CLEAR_DTC_DCDC_OK" 197904 "CLEAR_DTC_DCDC_FAILED" 198144 "CLEAR_DTC_DDM" 198145 "CLEAR_DTC_DDM_OK" 198160 "CLEAR_DTC_DDM_FAILED" 198400 "CLEAR_DTC_DH" 198401 "CLEAR_DTC_DH_OK" 198416 "CLEAR_DTC_DH_FAILED" 198656 "CLEAR_DTC_DI" 198657 "CLEAR_DTC_DI_OK" 198672 "CLEAR_DTC_DI_FAILED" 198912 "CLEAR_DTC_DIS" 198913 "CLEAR_DTC_DIS_OK" 198928 "CLEAR_DTC_DIS_FAILED" 199168 "CLEAR_DTC_EAS" 199169 "CLEAR_DTC_EAS_OK" 199184 "CLEAR_DTC_EAS_FAILED" 199424 "CLEAR_DTC_EPAS" 199425 "CLEAR_DTC_EPAS_OK" 199440 "CLEAR_DTC_EPAS_FAILED" 199680 "CLEAR_DTC_EPB" 199681 "CLEAR_DTC_EPB_OK" 199696 "CLEAR_DTC_EPB_FAILED" 199936 "CLEAR_DTC_EPBM" 199937 "CLEAR_DTC_EPBM_OK" 199952 "CLEAR_DTC_EPBM_FAILED" 200192 "CLEAR_DTC_ESP" 200193 "CLEAR_DTC_ESP_OK" 200208 "CLEAR_DTC_ESP_FAILED" 200448 "CLEAR_DTC_FC1" 200449 "CLEAR_DTC_FC1_OK" 200464 "CLEAR_DTC_FC1_FAILED" 200704 "CLEAR_DTC_FC10" 200705 "CLEAR_DTC_FC10_OK" 200720 "CLEAR_DTC_FC10_FAILED" 200960 "CLEAR_DTC_FC11" 200961 "CLEAR_DTC_FC11_OK" 200976 "CLEAR_DTC_FC11_FAILED" 201216 "CLEAR_DTC_FC12" 201217 "CLEAR_DTC_FC12_OK" 201232 "CLEAR_DTC_FC12_FAILED" 201472 "CLEAR_DTC_FC2" 201473 "CLEAR_DTC_FC2_OK" 201488 "CLEAR_DTC_FC2_FAILED" 201728 "CLEAR_DTC_FC3" 201729 "CLEAR_DTC_FC3_OK" 201744 "CLEAR_DTC_FC3_FAILED" 201984 "CLEAR_DTC_FC4" 201985 "CLEAR_DTC_FC4_OK" 202000 "CLEAR_DTC_FC4_FAILED" 202240 "CLEAR_DTC_FC5" 202241 "CLEAR_DTC_FC5_OK" 202256 "CLEAR_DTC_FC5_FAILED" 202496 "CLEAR_DTC_FC6" 202497 "CLEAR_DTC_FC6_OK" 202512 "CLEAR_DTC_FC6_FAILED" 202752 "CLEAR_DTC_FC7" 202753 "CLEAR_DTC_FC7_OK" 202768 "CLEAR_DTC_FC7_FAILED" 203008 "CLEAR_DTC_FC8" 203009 "CLEAR_DTC_FC8_OK" 203024 "CLEAR_DTC_FC8_FAILED" 203264 "CLEAR_DTC_FC9" 203265 "CLEAR_DTC_FC9_OK" 203280 "CLEAR_DTC_FC9_FAILED" 203520 "CLEAR_DTC_HNDFD" 203521 "CLEAR_DTC_HNDFD_OK" 203536 "CLEAR_DTC_HNDFD_FAILED" 203776 "CLEAR_DTC_HNDFP" 203777 "CLEAR_DTC_HNDFP_OK" 203792 "CLEAR_DTC_HNDFP_FAILED" 204032 "CLEAR_DTC_HNDRD" 204033 "CLEAR_DTC_HNDRD_OK" 204048 "CLEAR_DTC_HNDRD_FAILED" 204288 "CLEAR_DTC_HNDRP" 204289 "CLEAR_DTC_HNDRP_OK" 204304 "CLEAR_DTC_HNDRP_FAILED" 204544 "CLEAR_DTC_IC" 204545 "CLEAR_DTC_IC_OK" 204560 "CLEAR_DTC_IC_FAILED" 204800 "CLEAR_DTC_LFT" 204801 "CLEAR_DTC_LFT_OK" 204816 "CLEAR_DTC_LFT_FAILED" 205056 "CLEAR_DTC_MSM" 205057 "CLEAR_DTC_MSM_OK" 205072 "CLEAR_DTC_MSM_FAILED" 205312 "CLEAR_DTC_OCS" 205313 "CLEAR_DTC_OCS_OK" 205328 "CLEAR_DTC_OCS_FAILED" 205568 "CLEAR_DTC_PDM" 205569 "CLEAR_DTC_PDM_OK" 205584 "CLEAR_DTC_PDM_FAILED" 205824 "CLEAR_DTC_PM" 205825 "CLEAR_DTC_PM_OK" 205840 "CLEAR_DTC_PM_FAILED" 206080 "CLEAR_DTC_PTC" 206081 "CLEAR_DTC_PTC_OK" 206096 "CLEAR_DTC_PTC_FAILED" 206336 "CLEAR_DTC_RCCM" 206337 "CLEAR_DTC_RCCM_OK" 206352 "CLEAR_DTC_RCCM_FAILED" 206592 "CLEAR_DTC_SCCM" 206593 "CLEAR_DTC_SCCM_OK" 206608 "CLEAR_DTC_SCCM_FAILED" 206848 "CLEAR_DTC_SCM" 206849 "CLEAR_DTC_SCM_OK" 206864 "CLEAR_DTC_SCM_FAILED" 207104 "CLEAR_DTC_SCS" 207105 "CLEAR_DTC_SCS_OK" 207120 "CLEAR_DTC_SCS_FAILED" 207360 "CLEAR_DTC_SDM" 207361 "CLEAR_DTC_SDM_OK" 207376 "CLEAR_DTC_SDM_FAILED" 207616 "CLEAR_DTC_SEC" 207617 "CLEAR_DTC_SEC_OK" 207632 "CLEAR_DTC_SEC_FAILED" 207872 "CLEAR_DTC_SUN" 207873 "CLEAR_DTC_SUN_OK" 207888 "CLEAR_DTC_SUN_FAILED" 208128 "CLEAR_DTC_THC" 208129 "CLEAR_DTC_THC_OK" 208144 "CLEAR_DTC_THC_FAILED" 208384 "CLEAR_DTC_TPMS" 208385 "CLEAR_DTC_TPMS_OK" 208400 "CLEAR_DTC_TPMS_FAILED" 208640 "CLEAR_DTC_TUNER" 208641 "CLEAR_DTC_TUNER_OK" 208656 "CLEAR_DTC_TUNER_FAILED" 262144 "THC_SYS_TEST" 262145 "THC_SYS_TEST_OK" 262160 "THC_SYS_TEST_UDS_FAILED" 262161 "THC_SYS_TEST_TEMP_SENS_FAILED" 262162 "THC_SYS_TEST_PUMPS_FAILED" 262163 "THC_SYS_TEST_VALVES_FAILED" 262164 "THC_SYS_TEST_CHILLER_FAILED" 262165 "THC_SYS_TEST_FANS_FAILED" 262166 "THC_SYS_TEST_BATT_HEATER_FAILED" 262167 "THC_SYS_TEST_PRESSURE_SENS_FAILED" 262168 "THC_SYS_TEST_CAN_NETWORK_FAILED" 262169 "THC_SYS_TEST_EVAPORATOR_FAILED" 262170 "THC_SYS_TEST_PTC_HEATER_FAILED" 262171 "THC_SYS_TEST_RCCM_ACT_FAILED" 262172 "THC_SYS_TEST_CABIN_BLOWER_FAILED" 262173 "THC_SYS_TEST_LT_CONDENSER_FAILED" 262174 "THC_SYS_TEST_RT_CONDENSER_FAILED" 262175 "THC_SYS_TEST_LT_RAD_FAILED" 262176 "THC_SYS_TEST_RT_RAD_FAILED" 327680 "THC_COOLANT_AIR_PURGE" 327681 "THC_COOLANT_AIR_PURGE_OK" 327696 "THC_COOLANT_AIR_PURGE_FAILED" 393216 "THC_COOLANT_FILL" 393232 "THC_COOLANT_FILL_UDS_FAILED" 393472 "THC_COOLANT_FILL_STOPPED" 458752 "PUMP_TOOL_ENABLED" 459008 "PUMP_TOOL_DISABLED" 524288 "GTW_RST" 524289 "GTW_RST_OK" 524304 "GTW_RST_FAILED" 589824 "MCU_RST" 589825 "MCU_RST_OK" 589840 "MCU_RST_FAILED" 655360 "GTW_DUMP" 655361 "GTW_DUMP_OK" 655376 "GTW_DUMP_FAILED" 720896 "GTW_RESTORE" 720897 "GTW_RESTORE_OK" 720912 "GTW_RESTORE_FAILED" 786432 "GTW_DISABLE" 786433 "GTW_DISABLE_OK" 786448 "GTW_DISABLE_FAILED" 917504 "OCS_REZERO" 917505 "OCS_REZERO_OK" 917520 "OCS_REZERO_UDS_FAILED" 917521 "OCS_REZERO_NOT_ATTEMPTED_FAILED" 917522 "OCS_REZERO_SEAT_INIT_NOT_COMPLETE_FAILED" 917523 "OCS_REZERO_RESET_INIT_NOT_COMPLETE_FAILED" 917524 "OCS_REZERO_RESET_FAULTS_SET_FAILED" 917525 "OCS_REZERO_EDR_IN_PROGRESS_FAILED" 917526 "OCS_REZERO_PRESSURE_OUT_OF_RANGE_FAILED" 917527 "OCS_REZERO_PRESSURE_UNSTABLE_FAILED" 917528 "OCS_TEMP_OUT_OF_RANGE_FAILED" 983040 "SEC_LEARN_KEYS" 983041 "SEC_LEARN_KEYS_OK" 983057 "SEC_LEARN_KEYS_UDS_FAILED" 1048576 "TPMS_AUTO_LEARN" 1048832 "TPMS_AUTO_LEARN_DONE" 1114112 "MODEM_CONNECTION" 1114113 "MODEM_CONNECTION_OK" 1114128 "MODEM_CONNECTION_FAILED" 1179648 "EAS_CAL_READ" 1179664 "EAS_CAL_READ_FAILED" 1179665 "EAS_CAL_WRITE_FAILED" 1179904 "EAS_CAL_WRITE" 1245184 "EAS_PRESSURIZE" 1245185 "EAS_PRESSURIZE_OK" 1245200 "EAS_PRESSURIZE_UDS_FAILED" 1310720 "EAS_FILL_TIME_TRIGGERED_FL" 1310721 "EAS_FILL_DEFLATE_COMPLETED" 1310736 "EAS_FILL_DEFLATE_UDS_FAILED" 1310737 "EAS_FILL_DEFLATE_FINISHED_WITH_ERROR" 1310738 "EAS_FILL_DEFLATE_TEMP_TOO_HIGH" 1310739 "EAS_FILL_DEFLATE_LIMP_HOME_MODE_LEVEL_CONTROL_ACTIVE" 1310740 "EAS_FILL_DEFLATE_LIMP_HOME_MODE_DAMPING_CONTROL_ACTIVE" 1310741 "EAS_FILL_DEFLATE_VALVE_SWITCH_ON_TIME_EXCEEDED" 1310742 "EAS_FILL_DEFLATE_SYSTEM_AIR_MASS_TOO_HIGH" 1310743 "EAS_FILL_DEFLATE_SYSTEM_AIR_MASS_TOO_LOW" 1310744 "EAS_FILL_DEFLATE_RESERVOIR_PRESSURE_TOO_LOW" 1310745 "EAS_FILL_DEFLATE_RESERVOIR_PRESSURE_TOO_HIGH" 1310746 "EAS_FILL_AIR_SPRING_PRESSURE_TOO_LOW" 1310747 "EAS_FILL_AIR_SPRING_PRESSURE_TOO_HIGH" 1310748 "EAS_FILL_DEFLATE_TIMEOUT_OF_SUB_FUNCTION" 1310749 "EAS_FILL_DEFLATE_INVALID_ACCESS" 1310976 "EAS_FILL_TIME_TRIGGERED_FR" 1311232 "EAS_FILL_TIME_TRIGGERED_RL" 1311488 "EAS_FILL_TIME_TRIGGERED_RR" 1311744 "EAS_FILL_COMPLETE_FL" 1312000 "EAS_FILL_COMPLETE_FR" 1312256 "EAS_FILL_COMPLETE_RL" 1312512 "EAS_FILL_COMPLETE_RR" 1312768 "EAS_DEFLATE_RESERVOIR_FIXED_SHORT_TIME_FL" 1313024 "EAS_DEFLATE_RESERVOIR_FIXED_SHORT_TIME_FR" 1313280 "EAS_DEFLATE_RESERVOIR_FIXED_SHORT_TIME_RL" 1313536 "EAS_DEFLATE_RESERVOIR_FIXED_SHORT_TIME_RR" 1313792 "EAS_DEFLATE_AMBIENT_FIXED_SHORT_TIME_FL" 1314048 "EAS_DEFLATE_AMBIENT_FIXED_SHORT_TIME_FR" 1314304 "EAS_DEFLATE_AMBIENT_FIXED_SHORT_TIME_RL" 1314560 "EAS_DEFLATE_AMBIENT_FIXED_SHORT_TIME_RR" 1314816 "EAS_DEFLATE_AMBIENT_FIXED_SHORT_TIME_ALL" 1315072 "EAS_DEFLATE_AMBIENT_PREDEFINED_PRESSURE_FL" 1315328 "EAS_DEFLATE_AMBIENT_PREDEFINED_PRESSURE_FR" 1315584 "EAS_DEFLATE_AMBIENT_PREDEFINED_PRESSURE_RL" 1315840 "EAS_DEFLATE_AMBIENT_PREDEFINED_PRESSURE_RR" 1316096 "EAS_DEFLATE_AMBIENT_PREDEFINED_PRESSURE_ALL" 1376256 "EAS_STOP_SERVICE" 1376257 "EAS_STOP_SERVICE_COMPLETED" 1376272 "EAS_STOP_SERVICE_FAILED" 1441792 "EAS_LEVEL_SET_VERY_HIGH" 1441793 "EAS_LEVEL_COMPLETED" 1441808 "EAS_LEVEL_FAILED" 1442048 "EAS_LEVEL_SET_HIGH" 1442304 "EAS_LEVEL_SET_NORMAL" 1442560 "EAS_LEVEL_SET_LOW" 1442816 "EAS_LEVEL_SET_VERY_LOW" 1507328 "EAS_MEASURE_AIR_MASS" 1507329 "EAS_MEASURE_AIR_MASS_COMPLETED" 1507344 "EAS_MEASURE_AIR_MASS_FAILED" 1507345 "EAS_MEASURE_AIR_MASS_TOO_LOW" 1507346 "EAS_MEASURE_AIR_MASS_TOO_HIGH" 1572864 "EAS_MEASURE_PRESSURE" 1572865 "EAS_MEASURE_PRESSURE_COMPLETED" 1572880 "EAS_MEASURE_PRESSURE_FAILED" 1638400 "SUNROOF_OPEN" 1638416 "SUNROOF_OPERATION_FAILED" 1638656 "SUNROOF_CALIBRATE" 1638912 "SUNROOF_CLOSE" 1639168 "SUNROOF_VENT" 1639424 "SUNROOF_STOP" 1639680 "SUNROOF_SET_PERCENT" 2097153 "EOL_ANTENNA_REAR_BUMPER_OK" 2097168 "EOL_ANTENNA_REAR_BUMPER_FAILED" 2097409 "EOL_ANTENNA_FRONT_TRUNK_OK" 2097424 "EOL_ANTENNA_FRONT_TRUNK_FAILED" 2097665 "EOL_ANTENNA_CENTER_CONSOLE_OK" 2097680 "EOL_ANTENNA_CENTER_CONSOLE_FAILED" 2097921 "EOL_ANTENNA_REAR_SEAT_OK" 2097936 "EOL_ANTENNA_REAR_SEAT_FAILED" 2098177 "EOL_ANTENNA_DEAD_KEY_FOB_OK" 2098192 "EOL_ANTENNA_DEAD_KEY_FOB_FAILED" 2098433 "EOL_ANTENNA_DRIVER_IP_END_CAP_OK" 2098448 "EOL_ANTENNA_DRIVER_IP_END_CAP_FAILED" 2098689 "EOL_SUNROOF_CALIBRATION_OK" 2098704 "EOL_SUNROOF_CALIBRATION_FAILED" 2098945 "EOL_SUNROOF_ANTI_PINCH_OK" 2098960 "EOL_SUNROOF_ANTI_PINCH_FAILED" 2099201 "EOL_THERMAL_TEST_OK" 2099216 "EOL_THERMAL_TEST_FAILED" 2099457 "EOL_STEERING_ANGLE_OK" 2099472 "EOL_STEERING_ANGLE_FAILED" 2099713 "EOL_FW_REVISION_OK" 2099728 "EOL_FW_REVISION_FAILED" 2099969 "EOL_HANDLE_CONFIG_DRIVER_FRONT_OK" 2099984 "EOL_HANDLE_CONFIG_DRIVER_FRONT_FAILED" 2100225 "EOL_HANDLE_CONFIG_DRIVER_REAR_OK" 2100240 "EOL_HANDLE_CONFIG_DRIVER_REAR_FAILED" 2100481 "EOL_HANDLE_CONFIG_PASSENGER_FRONT_OK" 2100496 "EOL_HANDLE_CONFIG_PASSENGER_FRONT_FAILED" 2100737 "EOL_HANDLE_CONFIG_PASSENGER_REAR_OK" 2100752 "EOL_HANDLE_CONFIG_PASSENGER_REAR_FAILED" 2100993 "EOL_AIR_HUMIDITY_SENSOR_HUMIDITY_OK" 2101008 "EOL_AIR_HUMIDITY_SENSOR_HUMIDITY_FAILED" 2101249 "EOL_AIR_HUMIDITY_SENSOR_TEMP_OK" 2101264 "EOL_AIR_HUMIDITY_SENSOR_TEMP_FAILED" 2101505 "EOL_POWER_STEERING_F108_OK" 2101520 "EOL_POWER_STEERING_F108_FAILED" 2101761 "EOL_POWER_STEERING_F111_OK" 2101776 "EOL_POWER_STEERING_F111_FAILED" 2102017 "EOL_POWER_STEERING_F113_OK" 2102032 "EOL_POWER_STEERING_F113_FAILED" 2102273 "EOL_POWER_STEERING_F124_OK" 2102288 "EOL_POWER_STEERING_F124_FAILED" 2102529 "EOL_POWER_STEERING_F125_OK" 2102544 "EOL_POWER_STEERING_F125_FAILED" 2102785 "EOL_POWER_STEERING_F188_OK" 2102800 "EOL_POWER_STEERING_F188_FAILED" 2103041 "EOL_HEADLIGHTS_LOW_BEAMS_OK" 2103056 "EOL_HEADLIGHTS_LOW_BEAMS_FAILED" 2103297 "EOL_FOG_LAMPS_FRONT_OK" 2103312 "EOL_FOG_LAMPS_FRONT_FAILED" 2103553 "EOL_FOG_LAMPS_REAR_OK" 2103568 "EOL_FOG_LAMPS_REAR_FAILED" 2103809 "EOL_EXTERIOR_LIGHTS_OFF_OK" 2103824 "EOL_EXTERIOR_LIGHTS_OFF_FAILED" 2104065 "EOL_DRL_OK" 2104080 "EOL_DRL_FAILED" 2104321 "EOL_TAIL_LAMP_OK" 2104336 "EOL_TAIL_LAMP_FAILED" 2104577 "EOL_LICENSE_PLATE_LAMPS_OK" 2104592 "EOL_LICENSE_PLATE_LAMPS_FAILED" 2104833 "EOL_PARKING_LIGHTS_OK" 2104848 "EOL_PARKING_LIGHTS_FAILED" 2105089 "EOL_AMBIENT_LIGHTS_OK" 2105104 "EOL_AMBIENT_LIGHTS_FAILED" 2105345 "EOL_HOMELINK_OK" 2105360 "EOL_HOMELINK_FAILED" 2105601 "EOL_HANDLE_PRESENT_DRIVER_FRONT_OK" 2105616 "EOL_HANDLE_PRESENT_DRIVER_FRONT_FAILED" 2105857 "EOL_HANDLE_PRESENT_DRIVER_REAR_OK" 2105872 "EOL_HANDLE_PRESENT_DRIVER_REAR_FAILED" 2106113 "EOL_HANDLE_PRESENT_PASSENGER_FRONT_OK" 2106128 "EOL_HANDLE_PRESENT_PASSENGER_FRONT_FAILED" 2106369 "EOL_HANDLE_PRESENT_PASSENGER_REAR_OK" 2106384 "EOL_HANDLE_PRESENT_PASSENGER_REAR_FAILED" 2106625 "EOL_SEAT_SENSOR_DRIVER_OK" 2106640 "EOL_SEAT_SENSOR_DRIVER_FAILED" 2106881 "EOL_SEAT_SENSOR_PASSENGER_OK" 2106896 "EOL_SEAT_SENSOR_PASSENGER_FAILED" 2107137 "EOL_HANDLE_OPEN_DRIVER_FRONT_OK" 2107152 "EOL_HANDLE_OPEN_DRIVER_FRONT_FAILED" 2107393 "EOL_HANDLE_OPEN_DRIVER_REAR_OK" 2107408 "EOL_HANDLE_OPEN_DRIVER_REAR_FAILED" 2107649 "EOL_HANDLE_OPEN_PASSENGER_FRONT_OK" 2107664 "EOL_HANDLE_OPEN_PASSENGER_FRONT_FAILED" 2107905 "EOL_HANDLE_OPEN_PASSENGER_REAR_OK" 2107920 "EOL_HANDLE_OPEN_PASSENGER_REAR_FAILED" 2108161 "EOL_SEAT_BELT_DRIVER_OK" 2108176 "EOL_SEAT_BELT_DRIVER_FAILED" 2108417 "EOL_SEAT_BELT_PASSENGER_OK" 2108432 "EOL_SEAT_BELT_PASSENGER_FAILED" 2108673 "EOL_DOOR_RELEASE_DRIVER_FRONT_OK" 2108688 "EOL_DOOR_RELEASE_DRIVER_FRONT_FAILED" 2108929 "EOL_DOOR_RELEASE_DRIVER_REAR_OK" 2108944 "EOL_DOOR_RELEASE_DRIVER_REAR_FAILED" 2109185 "EOL_DOOR_RELEASE_PASSENGER_FRONT_OK" 2109200 "EOL_DOOR_RELEASE_PASSENGER_FRONT_FAILED" 2109441 "EOL_DOOR_RELEASE_PASSENGER_REAR_OK" 2109456 "EOL_DOOR_RELEASE_PASSENGER_REAR_FAILED" 2109697 "EOL_SIGNAL_LIGHTS_HAZARD_OK" 2109712 "EOL_SIGNAL_LIGHTS_HAZARD_FAILED" 2109953 "EOL_SIGNAL_LIGHTS_LEFT_OK" 2109968 "EOL_SIGNAL_LIGHTS_LEFT_FAILED" 2110209 "EOL_SIGNAL_LIGHTS_RIGHT_OK" 2110224 "EOL_SIGNAL_LIGHTS_RIGHT_FAILED" 2110465 "EOL_STEERING_WHEEL_LEFT_TOP_OK" 2110480 "EOL_STEERING_WHEEL_LEFT_TOP_FAILED" 2110721 "EOL_STEERING_WHEEL_LEFT_BOTTOM_OK" 2110736 "EOL_STEERING_WHEEL_LEFT_BOTTOM_FAILED" 2110977 "EOL_STEERING_WHEEL_LEFT_MIDDLE_OK" 2110992 "EOL_STEERING_WHEEL_LEFT_MIDDLE_FAILED" 2111233 "EOL_STEERING_WHEEL_LEFT_UP_OK" 2111248 "EOL_STEERING_WHEEL_LEFT_UP_FAILED" 2111489 "EOL_STEERING_WHEEL_LEFT_DOWN_OK" 2111504 "EOL_STEERING_WHEEL_LEFT_DOWN_FAILED" 2111745 "EOL_STEERING_WHEEL_RIGHT_TOP_OK" 2111760 "EOL_STEERING_WHEEL_RIGHT_TOP_FAILED" 2112001 "EOL_STEERING_WHEEL_RIGHT_BOTTOM_OK" 2112016 "EOL_STEERING_WHEEL_RIGHT_BOTTOM_FAILED" 2112257 "EOL_STEERING_WHEEL_RIGHT_MIDDLE_OK" 2112272 "EOL_STEERING_WHEEL_RIGHT_MIDDLE_FAILED" 2112513 "EOL_STEERING_WHEEL_RIGHT_UP_OK" 2112528 "EOL_STEERING_WHEEL_RIGHT_UP_FAILED" 2112769 "EOL_STEERING_WHEEL_RIGHT_DOWN_OK" 2112784 "EOL_STEERING_WHEEL_RIGHT_DOWN_FAILED" 2113025 "EOL_RLS_OK" 2113040 "EOL_RLS_FAILED" 2113281 "EOL_POWER_LIFTGATE_INT_BUTTON_OK" 2113296 "EOL_POWER_LIFTGATE_INT_BUTTON_FAILED" 2113537 "EOL_REAR_TRUNK_EXT_BUTTON_OK" 2113552 "EOL_REAR_TRUNK_EXT_BUTTON_FAILED" 2113793 "EOL_POWER_LIFTGATE_BOTTOM_BUTTON_CLOSE_OK" 2113808 "EOL_POWER_LIFTGATE_BOTTOM_BUTTON_CLOSE_FAILED" 2114049 "EOL_POWER_LIFTGATE_BEEP_OK" 2114064 "EOL_POWER_LIFTGATE_BEEP_FAILED" 2114305 "EOL_POWER_LIFTGATE_ANTI_PINCH_LEFT_OK" 2114320 "EOL_POWER_LIFTGATE_ANTI_PINCH_LEFT_FAILED" 2114561 "EOL_POWER_LIFTGATE_ANTI_PINCH_RIGHT_OK" 2114576 "EOL_POWER_LIFTGATE_ANTI_PINCH_RIGHT_FAILED" 2114817 "EOL_BRAKE_LIGHTS_CHMSL_OK" 2114832 "EOL_BRAKE_LIGHTS_CHMSL_FAILED" 2115073 "EOL_BRAKE_LIGHTS_REAR_OK" 2115088 "EOL_BRAKE_LIGHTS_REAR_FAILED" 2115329 "EOL_BRAKE_CORNERING_LIGHTS_LEFT_OK" 2115344 "EOL_BRAKE_CORNERING_LIGHTS_LEFT_FAILED" 2115585 "EOL_BRAKE_CORNERING_LIGHTS_RIGHT_OK" 2115600 "EOL_BRAKE_CORNERING_LIGHTS_RIGHT_FAILED" 2115841 "EOL_HEAD_LIGHTS_HI_BEAM_OK" 2115856 "EOL_HEAD_LIGHTS_HI_BEAM_FAILED" 2116097 "EOL_FRUNK_RELEASE_OK" 2116112 "EOL_FRUNK_RELEASE_FAILED" 2116353 "EOL_REVERSE_LIGHTS_OK" 2116368 "EOL_REVERSE_LIGHTS_FAILED" 2116608 "SEC_CLEAR_NVRAM" 2116609 "SEC_CLEAR_NVRAM_OK" 2116624 "SEC_CLEAR_NVRAM_UDS_FAILED" 2116625 "SEC_CLEAR_NVRAM_EEPROM_FAILED" 2116864 "SEC_BARCODE_LEARN_KEYS" 2116865 "SEC_BARCODE_LEARN_KEYS_OK" 2116880 "SEC_BARCODE_LEARN_KEYS_UDS_FAILED" 2116881 "SEC_BARCODE_LEARN_KEYS_FAILED" 2117120 "DCDC_BOOTLOADER_UPDATE_PROMPTED" 2117121 "DCDC_BOOTLOADER_UPDATE_ACCEPTED" 2117122 "DCDC_BOOTLOADER_UPDATE_REJECTED" 2117123 "DCDC_BOOTLOADER_UPDATE_OK" 2117136 "DCDC_BOOTLOADER_UPDATE_FAILED" 2117376 "AIRBAG_PROGRAM_FLASH_FIRMWARE" 2117377 "AIRBAG_PROGRAM_FLASH_FIRMWARE_OK" 2117392 "AIRBAG_PROGRAM_FLASH_FIRMWARE_FAILED" 2117632 "AIRBAG_PROGRAM_CHECK_SW_VERSION" 2117633 "AIRBAG_PROGRAM_CHECK_SW_VERSION_OK" 2117648 "AIRBAG_PROGRAM_CHECK_SW_VERSION_FAILED" 2117888 "AIRBAG_PROGRAM_READ_VIN" 2117889 "AIRBAG_PROGRAM_READ_VIN_OK" 2117904 "AIRBAG_PROGRAM_READ_VIN_FAILED" 2118144 "AIRBAG_PROGRAM_WRITE_VIN" 2118145 "AIRBAG_PROGRAM_WRITE_VIN_OK" 2118160 "AIRBAG_PROGRAM_WRITE_VIN_FAILED" 2118400 "AIRBAG_PROGRAM_CHECK_ARM_STATUS" 2118401 "AIRBAG_PROGRAM_CHECK_ARM_STATUS_OK" 2118416 "AIRBAG_PROGRAM_CHECK_ARM_STATUS_FAILED" 2118656 "AIRBAG_PROGRAM_CONTROL_MODULE" 2118657 "AIRBAG_PROGRAM_CONTROL_MODULE_OK" 2118672 "AIRBAG_PROGRAM_CONTROL_MODULE_FAILED" 2118912 "EPAS_VIN_LEARN" 2118913 "EPAS_VIN_LEARN_OK" 2118928 "EPAS_VIN_LEARN_FAILED" 2119168 "EPAS_VERIFY_VIN_LEARN" 2119169 "EPAS_VERIFY_VIN_LEARN_OK" 2119184 "EPAS_VERIFY_VIN_LEARN_FAILED" 2119424 "EPAS_STEERING_TUNE" 2119425 "EPAS_STEERING_TUNE_OK" 2119440 "EPAS_STEERING_TUNE_FAILED" 2119680 "CHARGER_CONFIG_MASTER" 2119681 "CHARGER_CONFIG_MASTER_OK" 2119696 "CHARGER_CONFIG_MASTER_FAILED" 2119936 "CHARGER_CONFIG_SLAVE" 2119937 "CHARGER_CONFIG_SLAVE_OK" 2119952 "CHARGER_CONFIG_SLAVE_FAILED" 2120192 "CHARGER_CONFIG_RAV4" 2120193 "CHARGER_CONFIG_RAV4_OK" 2120208 "CHARGER_CONFIG_RAV4_FAILED" 2120449 "EOL_PASSENGER_IP_END_CAP_OK" 2120464 "EOL_PASSENGER_IP_END_CAP_FAILED" 2120705 "EOL_SYSTEM_AIR_MASS_OK" 2120720 "EOL_SYSTEM_AIR_MASS_FAILED";

VAL_ 132 TPMS_learningStatus 0 "FAILED" 1 "ONGOING" 2 "STOPPED" 3 "PASSED";
VAL_ 132 TPMS_localisationStatus 0 "FAILED" 1 "ONGOING" 2 "STOPPED" 3 "PASSED";

VAL_ 911 TUNER_displayType 0 "INFOTAINMENT_LINE" 1 "INFOTAINMENT_TXT" 2 "RSA_LINE" 3 "RSE_LINE" 4 "RSE_TFT" 5 "INDASH_LINE" 6 "HUD_LINE";

VAL_ 815 TUNER_abitrationCommand 0 "NO_ACTION" 1 "START_ARBITRATION" 2 "CONNECT_TO_SINK" 3 "DISCONNECT_FROM_SINK" 4 "END_ARBITRATION";

VAL_ 936 TUNER_controlCommand 0 "NOOP" 1 "SELECT_BAND" 2 "CANCEL_TRAFFIC_INTERRUPT" 4 "MUTE" 5 "CONFIGURE_REGION" 6 "REQUEST_ERROR_STATUS" 16 "AMFMHD_DIRECT_TUNE" 17 "AMFMHD_TUNE_UP_DOWN" 19 "AMFMHD_SEEK_UP_DOWN" 20 "AMFMHD_SCAN_UP_DOWN" 21 "AMFMHD_PTY_SEEK" 22 "AMFMHD_PTY_SCAN" 23 "AMFMHD_PTY_GROUP_SELECT" 26 "RDS_SETTINGS" 27 "AMFMHD_RADIO_SETTINGS" 32 "XD_DIRECT_TUNE" 33 "XD_TUNE_UP_DOWN" 34 "XD_FAST_UP_DOWN" 35 "XM_SEEK_UP_DOWN" 36 "XM_SCAN_UP_DOWN" 39 "XM_CATEGORY_UP_DOWN" 40 "XM_CATEGORY_SEARCH_UP_DN" 44 "XM_DIAGNOSTICS_MODE" 45 "XM_EXT_DIAGNOSTICS_MODE" 48 "DAB_DIRECT_TUNE" 49 "DAB_TUNE_UP_DOWN" 51 "DAB_SEEK_UP_DOWN" 52 "DAB_SCAN_UP_DOWN" 53 "DAB_PTY_SEEK" 54 "DAB_PTY_SCAN" 55 "DAB_PTY_GROUP_SELECT" 58 "DAB_SETTINGS" 62 "DAB_MAKE_STATION_LIST";
VAL_ 936 TUNER_paramSelectBand 0 "AM_MW" 1 "LW" 2 "FM" 3 "XM" 4 "DAB";
VAL_ 936 TUNER_paramMuteControl 0 "UNMUTE" 1 "MUTE";
VAL_ 936 TUNER_paramConfigureRegion 0 "EU_NA" 2 "JAPAN" 4 "CHINA" 6 "AUSTRALIA" 8 "OTHER" 10 "THAI" 12 "LATIN_AMERICA" 14 "NA_NO_HD" 255 "DEFAULT";
VAL_ 936 TUNER_paramConfigureRegionPD 0 "OFF" 1 "ON" 255 "DEFAULT";
VAL_ 936 TUNER_paramAMFMHDDirectTuneBy 0 "FREQ" 1 "PI";
VAL_ 936 TUNER_paramAMFMHDTuneUpDown 0 "DOWN" 1 "UP";
VAL_ 936 TUNER_paramAMFMHDSeekUpDown 0 "DOWN" 1 "UP";
VAL_ 936 TUNER_paramAMFMHDScanUpDown 0 "DOWN" 1 "UP" 2 "STOP";
VAL_ 936 TUNER_paramAMFMHDPtySeek 0 "DOWN" 1 "UP";
VAL_ 936 TUNER_paramAMFMHDPtyScan 0 "DOWN" 1 "UP" 2 "STOP";
VAL_ 936 TUNER_paramAMFMHDPtyGroupSelect 0 "DOWN" 1 "UP" 2 "CURRENT" 4 "DIRECT";
VAL_ 936 TUNER_paramXMDirectTuneBy 0 "CHANNEL" 1 "SID";
VAL_ 936 TUNER_paramXMTuneUpDown 0 "DOWN" 1 "UP";
VAL_ 936 TUNER_paramXMFastUpDown 0 "DOWN" 1 "UP";
VAL_ 936 TUNER_paramXMSeekUpDown 0 "DOWN" 1 "UP";
VAL_ 936 TUNER_paramXMScanUpDown 0 "DOWN" 1 "UP" 2 "STOP";
VAL_ 936 TUNER_paramXMCategoryUpDown 0 "DOWN" 1 "UP";
VAL_ 936 TUNER_paramXMCatSearchUpDown 0 "DOWN" 1 "UP";
VAL_ 936 TUNER_paramXMDiagnosisMode 0 "OFF" 1 "ON";
VAL_ 936 TUNER_paramXMExtDiagnosisMode 0 "OFF" 1 "ON";
VAL_ 936 TUNER_paramDABDirectTuneBy 0 "CHANNEL" 1 "EID_SID";
VAL_ 936 TUNER_paramDABTuneUpDown 0 "DOWN" 1 "UP";
VAL_ 936 TUNER_paramDABSeekUpDown 0 "DOWN" 1 "UP";
VAL_ 936 TUNER_paramDABScanUpDown 0 "DOWN" 1 "UP" 2 "STOP";
VAL_ 936 TUNER_paramDABPtySeek 0 "DOWN" 1 "UP";
VAL_ 936 TUNER_paramDABPtyScan 0 "DOWN" 1 "UP" 2 "STOP";
VAL_ 936 TUNER_paramDABPtyGroupSelect 0 "DOWN" 1 "UP" 2 "CURRENT" 4 "DIRECT";
VAL_ 936 TUNER_paramDABMakeStationList 0 "CANCEL" 1 "START" 2 "START_SERVICE_LIST";

VAL_ 895 TUNER_receiverExtStatusType 0 "FM" 1 "HD" 2 "XM" 3 "DAB";
VAL_ 895 TUNER_receiverStatusFMPrgType 0 "NONE__NONE" 1 "NEWS__NEWS" 2 "INFORMATION__CURRENT_AFFAIRS" 3 "SPORTS__INFORMATION" 4 "TALK__SPORT" 5 "ROCK__EDUCATION" 6 "CLASSIC_ROCK__DRAMA" 7 "ADULT_HITS__CULTURES" 8 "SOFT_ROCK__SCIENCE" 9 "TOP_40__VARIED_SPEECH" 10 "COUNTRY__POP_MUSIC" 11 "OLDIES__ROCK_MUSIC" 12 "SOFT__EASY_LISTENING" 13 "NOSTALGIA__LIGHT_CLASSICS" 14 "JAZZ__SERIOUS_CLASSICS" 15 "CLASSICAL__OTHER_MUSIC" 16 "RHYTHM_AND_BLUES__WEATHER" 17 "SOFT_R_AND_B__FINANCE" 18 "FOREIGN__CHILDREN" 19 "RELIGIOUS_MUSIC__SOCIAL" 20 "RELIGIOUS_TALK__RELIGION" 21 "PERSONALITY__PHONE_IN" 22 "PUBLIC__TRAVEL_AND_TOURING" 23 "COLLEGE__LEISURE_AND_HOBBY" 24 "_JAZZ_MUSIC" 25 "_COUNTRY_MUSIC" 26 "_NATIONAL_MUSIC" 27 "_OLDIES_MUSIC" 28 "_FOLK_MUSIC" 29 "WEATHER__DOCUMENTARY" 30 "TEST__ALARM_TEST" 31 "ALERT__ALARM";
VAL_ 895 TUNER_receiverStatusFMPrgTypeGrp 0 "NO_PTY" 1 "NEWS" 2 "SPORTS" 3 "TALK" 4 "POP" 5 "ROCK" 6 "JAZZ" 7 "CLASSICS" 8 "OTHER" 9 "INFORMATION" 10 "EASY_LISTENING" 11 "OLDIES" 12 "R_AND_B" 13 "RELIGION" 14 "COUNTRY" 15 "TRAFFIC";
VAL_ 895 TUNER_receiverStatusHDPrgTypeGrp 0 "NO_PTY" 1 "NEWS" 2 "SPORTS" 3 "TALK" 4 "POP" 5 "ROCK" 6 "JAZZ" 7 "CLASSICS" 8 "OTHER" 9 "INFORMATION" 10 "EASY_LISTENING" 11 "OLDIES" 12 "R_AND_B" 13 "RELIGION" 14 "COUNTRY" 15 "TRAFFIC";
VAL_ 895 TUNER_receiverStatusDABPrgType 0 "NONE__NONE" 1 "NEWS__NEWS" 2 "AFFAIRS__CURRENT_AFFAIRS" 3 "INFO__INFORMATION" 4 "SPORT__SPORT" 5 "EDUCATE__EDUCATION" 6 "DRAMA__DRAMA" 7 "CULTURE__CULTURES" 8 "SCIENCE__SCIENCE" 9 "VARIED__VARIED_SPEECH" 10 "POP_M__POP_MUSIC" 11 "ROCK_M__ROCK_MUSIC" 12 "EASY_M__EASY_LISTENING" 13 "LIGHT_M__LIGHT_CLASSICS_M" 14 "CLASSICS__SERIOUS_CLASSICS" 15 "OTHER_M__OTHER_MUSIC" 16 "WEATHER__WEATHER_AND_METR" 17 "FINANCE__FINANCE" 18 "CHILDREN__CHILDRENS_PROGS" 19 "SOCIAL__SOCIAL_AFFAIRS" 20 "RELIGION__RELIGION" 21 "PHONE_IN__PHONE_IN" 22 "TRAVEL__TRAVEL_AND_TOURING" 23 "LEISURE__LEISURE_AND_HOBBY" 24 "JAZZ__JAZZ_MUSIC" 25 "COUNTRY__COUNTRY_MUSIC" 26 "NATIONAL__NATIONAL_MUSIC" 27 "OLDIES__OLDIES_MUSIC" 28 "FOLK__FOLK_MUSIC" 29 "DOCUMENT__DOCUMENTARY" 30 "TEST__ALARM_TEST" 31 "ALARM__ALARM_ALARM";

VAL_ 863 TUNER_cmdResponseEcho 0 "NOOP" 1 "SELECT_BAND" 2 "CANCEL_TRAFFIC_INTERRUPT" 4 "MUTE" 16 "AMFMHD_DIRECT_TUNE" 17 "AMFMHD_TUNE_UP_DOWN" 19 "AMFMHD_SEEK_UP_DOWN" 20 "AMFMHD_SCAN_UP_DOWN" 21 "AMFMHD_PTY_SEEK" 22 "AMFMHD_PTY_SCAN" 23 "AMFMHD_PTY_GROUP_SELECT" 26 "RDS_SETTINGS" 27 "AMFMHD_RADIO_SETTINGS" 32 "XD_DIRECT_TUNE" 33 "XD_TUNE_UP_DOWN" 34 "XD_FAST_UP_DOWN" 35 "XM_SEEK_UP_DOWN" 36 "XM_SCAN_UP_DOWN" 39 "XM_CATEGORY_UP_DOWN" 40 "XM_CATEGORY_SEARCH_UP_DN" 44 "XM_DIAGNOSTICS_MODE" 45 "XM_EXT_DIAGNOSTICS_MODE" 48 "DAB_DIRECT_TUNE" 49 "DAB_TUNE_UP_DOWN" 51 "DAB_SEEK_UP_DOWN" 52 "DAB_SCAN_UP_DOWN" 53 "DAB_PTY_SEEK" 54 "DAB_PTY_SCAN" 55 "DAB_PTY_GROUP_SELECT" 58 "DAB_SETTINGS";
VAL_ 863 TUNER_cmdResponseStatus 0 "SUCCESS" 1 "BUSY" 2 "UNKNOWN_CMD" 3 "INVALID_PARAM" 4 "INVALID_IN_BAND";

VAL_ 879 TUNER_receiverStatusBand 0 "AM_MW" 1 "AM_LW" 2 "FM" 3 "XM" 4 "DAB" 5 "TRAFFIC_INT";

VAL_ 904 TUNER_requestStatusType 111 "STATUS" 127 "EXT_STATUS";

VAL_ 920 TUNER_requestTextTextID 0 "HD_TITLE" 1 "HD_ARTIST" 2 "HD_ALBUM" 3 "HD_GENRE" 4 "HD_COMMENT" 5 "HD_COMMERCIAL" 6 "HD_STATION_NAME" 8 "PROG_SERVICE_NAME" 9 "RADIO_TEXT" 10 "PROGRAM_TYPE_NAME" 11 "PROG_TYPE_NAME_SRCH" 12 "FM_STATION_LIST" 13 "DAB_ENSEMBLE_LABEL" 14 "DAB_STATION_LIST" 16 "XM_TITLE" 17 "XM_CHANNEL_NAME" 18 "XM_ARTIST" 19 "XM_CATEGORY" 20 "XM_CATEGORY_SEARCH" 24 "XM_CATEGORY_MAP";

VAL_ 831 TUNER_audioSourceStatus 0 "START_ARBITRATION" 1 "BUSY" 2 "CONNECTION_COMPLETE" 3 "DISCONNECT_COMPLETE" 4 "END_ARBITRATION";

VAL_ 1407 TUNER_bootloaderVersion 255 "SNA";
VAL_ 1407 TUNER_componentHardwareRevision 15 "SNA";
VAL_ 1407 TUNER_componentVersion 255 "SNA";
VAL_ 1407 TUNER_country 255 "SNA";
VAL_ 1407 TUNER_dabVersion 255 "SNA";
VAL_ 1407 TUNER_dspDataVersion 65535 "SNA";
VAL_ 1407 TUNER_dspVersion 255 "SNA";

VAL_ 1423 TUNER_HDVersion 65535 "SNA";

VAL_ 1006 UI_autopilotControlIndex 0 "0" 1 "1" 2 "2" 3 "3" 4 "4" 5 "5" 6 "6" 7 "7";
VAL_ 1006 UI_hovEnabled 0 "OFF" 1 "ON";
VAL_ 1006 UI_donDisableAutoWiperDuration 0 "DEFAULT" 1 "5_S" 2 "15_S" 3 "30_S" 4 "60_S" 5 "120_S" 6 "OFF";
VAL_ 1006 UI_donDisableOnAutoWiperSpeed 0 "OFF" 1 "1" 2 "2" 3 "3" 4 "4" 5 "5" 6 "6" 7 "7" 8 "8" 9 "9" 10 "10" 11 "11" 12 "12" 13 "13" 14 "14" 15 "INVALID";
VAL_ 1006 UI_blindspotMinSpeed 0 "DEFAULT" 1 "5_KPH" 2 "10_KPH" 3 "15_KPH" 4 "20_KPH" 5 "25_KPH" 6 "30_KPH" 7 "35_KPH" 8 "40_KPH" 9 "45_KPH" 10 "OFF";
VAL_ 1006 UI_blindspotDistance 0 "DEFAULT" 1 "0P5_M" 2 "1_M" 3 "2_M" 4 "4_M" 5 "OFF";
VAL_ 1006 UI_blindspotTTC 0 "DEFAULT" 1 "0P5_S" 2 "1_S" 3 "2_S" 4 "3_S" 5 "4_S" 6 "5_S" 7 "OFF";
VAL_ 1006 UI_donStopEndOfRampBuffer 0 "DEFAULT" 1 "15_M" 2 "30_M" 3 "45_M" 4 "OFF";
VAL_ 1006 UI_donDisableCutin 0 "OFF" 1 "ON";
VAL_ 1006 UI_donMinGoreWidthForAbortMap 0 "DEFAULT" 1 "0_M" 2 "0P5_M" 3 "1_M" 4 "1P5_M" 5 "2_M" 6 "2P5_M" 7 "3_M" 8 "3P5_M" 9 "4_M" 10 "4P5_M" 11 "5_M";
VAL_ 1006 UI_donAlcProgGoreAbortThres 0 "DEFAULT" 1 "0P00" 2 "0P05" 3 "0P10" 4 "0P15" 5 "0P20" 6 "0P25" 7 "0P30" 8 "0P35" 9 "0P40";
VAL_ 1006 UI_donMinGoreWidthForAbortNotMap 0 "DEFAULT" 1 "0_M" 2 "0P5_M" 3 "1_M" 4 "1P5_M" 5 "2_M" 6 "2P5_M" 7 "3_M" 8 "3P5_M" 9 "4_M" 10 "4P5_M" 11 "5_M";
VAL_ 1006 UI_alcDisableUltrasonicCheck 0 "OFF" 1 "ON";
VAL_ 1006 UI_alcUltrasonicDistance 0 "DEFAULT" 1 "2_M" 2 "2P5_M" 3 "3_M" 4 "3P5_M" 5 "4_M" 6 "4P5_M" 7 "5_M" 8 "OFF";
VAL_ 1006 UI_alcUltrasonicWaitTime 0 "DEFAULT" 1 "0P1_S" 3 "0P25_S" 4 "0P5_S" 5 "0P75_S" 6 "1_S" 7 "OFF";
VAL_ 1006 UI_alcEgoLeadingReactionAccel 0 "DEFAULT" 1 "LESS" 2 "EVEN_LESS" 3 "OFF";
VAL_ 1006 UI_alcMergIntervalRearDHyst 0 "DEFAULT" 1 "LESS" 2 "EVEN_LESS" 3 "OFF";
VAL_ 1006 UI_alcMergingIntervalHeadwayHyst 0 "DEFAULT" 1 "LESS" 2 "EVEN_LESS" 3 "OFF";
VAL_ 1006 UI_alcAssertivenessRate 0 "DEFAULT" 1 "LESS" 2 "OFF";
VAL_ 1006 UI_alcViewRangeSensitivity 0 "DEFAULT" 1 "HIGH" 2 "LOW" 3 "OFF";
VAL_ 1006 UI_camBlockLaneCheckDisable 0 "DEFAULT" 1 "DISABLE";
VAL_ 1006 UI_camBlockBlurDisable 0 "DEFAULT" 1 "DISABLE";

VAL_ 1080 UI_anonDebugFlag1 0 "OFF" 1 "ON";
VAL_ 1080 UI_anonDebugFlag2 0 "OFF" 1 "ON";
VAL_ 1080 UI_anonDebugFlag3 0 "OFF" 1 "ON";
VAL_ 1080 UI_anonDebugFlag4 0 "OFF" 1 "ON";

VAL_ 1000 UI_autopilotControlRequest 0 "LEGACY_LAT_CTRL" 1 "NEXT_GEN_CTRL";
VAL_ 1000 UI_curvSpeedAdaptDisable 0 "ON" 1 "OFF";
VAL_ 1000 UI_curvatureDatabaseOnly 0 "OFF" 1 "ON";
VAL_ 1000 UI_driveOnMapsEnable 0 "OFF" 1 "ON";
VAL_ 1000 UI_drivingSide 0 "LEFT" 1 "RIGHT" 2 "UNKNOWN";
VAL_ 1000 UI_exceptionListEnable 0 "OFF" 1 "ON";
VAL_ 1000 UI_followNavRouteEnable 0 "OFF" 1 "ON";
VAL_ 1000 UI_forksEnable 0 "OFF" 1 "ON";
VAL_ 1000 UI_fuseHPPDisable 0 "ON" 1 "OFF";
VAL_ 1000 UI_fuseLanesDisable 0 "ON" 1 "OFF";
VAL_ 1000 UI_fuseVehiclesDisable 0 "ON" 1 "OFF";
VAL_ 1000 UI_handsOnRequirementDisable 0 "ON" 1 "OFF";
VAL_ 1000 UI_lssElkEnabled 0 "OFF" 1 "ON";
VAL_ 1000 UI_lssLdwEnabled 0 "OFF" 1 "ON";
VAL_ 1000 UI_lssLkaEnabled 0 "OFF" 1 "ON";
VAL_ 1000 UI_roadCheckDisable 0 "ON" 1 "OFF";
VAL_ 1000 UI_selfParkRequest 0 "NONE" 1 "SELF_PARK_FORWARD" 2 "SELF_PARK_REVERSE" 3 "ABORT" 4 "PRIME" 5 "PAUSE" 6 "RESUME" 7 "AUTO_SUMMON_FORWARD" 8 "AUTO_SUMMON_REVERSE" 9 "AUTO_SUMMON_CANCEL" 10 "AUTO_SUMMON_PRIMED" 11 "SMART_SUMMON" 15 "SNA";
VAL_ 1000 UI_source3D 0 "Z_FROM_MAP" 1 "Z_FROM_PATH_PREDICTION" 2 "XYZ_PREDICTION";
VAL_ 1000 UI_summonEntryType 0 "STRAIGHT" 1 "TURN_RIGHT" 2 "TURN_LEFT" 3 "SNA";
VAL_ 1000 UI_summonExitType 0 "STRAIGHT" 1 "TURN_RIGHT" 2 "TURN_LEFT" 3 "SNA";
VAL_ 1000 UI_summonReverseDist 63 "SNA";
VAL_ 1000 UI_ulcBlindSpotConfig 0 "STANDARD" 1 "AGGRESSIVE" 2 "MAD_MAX";
VAL_ 1000 UI_ulcSpeedConfig 0 "DISABLED" 1 "MILD" 2 "AVERAGE" 3 "MAD_MAX";
VAL_ 1000 UI_visionSpeedType 0 "DISABLED" 1 "ONE_SECOND" 2 "TWO_SECOND" 3 "OPTIMIZED";

VAL_ 568 UI_countryCode 0 "UNKNOWN" 1023 "SNA";
VAL_ 568 UI_mapSpeedLimit 0 "UNKNOWN" 1 "LESS_OR_EQ_5" 2 "LESS_OR_EQ_7" 3 "LESS_OR_EQ_10" 4 "LESS_OR_EQ_15" 5 "LESS_OR_EQ_20" 6 "LESS_OR_EQ_25" 7 "LESS_OR_EQ_30" 8 "LESS_OR_EQ_35" 9 "LESS_OR_EQ_40" 10 "LESS_OR_EQ_45" 11 "LESS_OR_EQ_50" 12 "LESS_OR_EQ_55" 13 "LESS_OR_EQ_60" 14 "LESS_OR_EQ_65" 15 "LESS_OR_EQ_70" 16 "LESS_OR_EQ_75" 17 "LESS_OR_EQ_80" 18 "LESS_OR_EQ_85" 19 "LESS_OR_EQ_90" 20 "LESS_OR_EQ_95" 21 "LESS_OR_EQ_100" 22 "LESS_OR_EQ_105" 23 "LESS_OR_EQ_110" 24 "LESS_OR_EQ_115" 25 "LESS_OR_EQ_120" 26 "LESS_OR_EQ_130" 27 "LESS_OR_EQ_140" 28 "LESS_OR_EQ_150" 29 "LESS_OR_EQ_160" 30 "UNLIMITED" 31 "SNA";
VAL_ 568 UI_mapSpeedLimitDependency 0 "NONE" 1 "SCHOOL" 2 "RAIN" 3 "SNOW" 4 "TIME" 5 "SEASON" 6 "LANE" 7 "SNA";
VAL_ 568 UI_mapSpeedLimitType 1 "REGULAR" 2 "ADVISORY" 3 "DEPENDENT" 4 "BUMPS" 7 "UNKNOWN_SNA";
VAL_ 568 UI_mapSpeedUnits 0 "MPH" 1 "KPH";
VAL_ 568 UI_nextBranchDist 31 "SNA";
VAL_ 568 UI_roadClass 0 "UNKNOWN_INVALID_SNA" 1 "CLASS_1_MAJOR" 2 "CLASS_2" 3 "CLASS_3" 4 "CLASS_4" 5 "CLASS_5" 6 "CLASS_6_MINOR";

VAL_ 536 UI_roadSign 0 "NONE" 1 "STOP_SIGN" 2 "TRAFFIC_LIGHT" 3 "SPEED_LIMIT" 4 "SPEED_SPLINE" 5 "SPLINE_ID_FULL";
VAL_ 536 UI_splineLocConfidence 0 "SNA";
VAL_ 536 UI_stopSignStopLineDist 1023 "SNA";
VAL_ 536 UI_stopSignStopLineConf 0 "SNA";
VAL_ 536 UI_trafficLightStopLineDist 1023 "SNA";
VAL_ 536 UI_trafficLightStopLineConf 0 "SNA";
VAL_ 536 UI_baseMapSpeedLimitMPS 255 "SNA";
VAL_ 536 UI_bottomQrtlFleetSpeedMPS 255 "SNA";
VAL_ 536 UI_topQrtlFleetSpeedMPS 255 "SNA";
VAL_ 536 UI_meanFleetSplineSpeedMPS 255 "SNA";
VAL_ 536 UI_medianFleetSpeedMPS 255 "SNA";
VAL_ 536 UI_meanFleetSplineAccelMPS2 255 "SNA";
VAL_ 536 UI_rampType 0 "NONE_SNA" 1 "ENTRANCE" 2 "EXIT" 3 "INTERCHANGE_ENTRANCE" 4 "INTERCHANGE_EXIT";
VAL_ 536 UI_currSplineIdFull 0 "SNA";

VAL_ 969 UI_mapSpeedLimitUnits 0 "MPH" 1 "KPH";
VAL_ 969 UI_userSpeedOffsetUnits 0 "MPH" 1 "KPH";

VAL_ 79 UI_gpsAccuracy 127 "SNA";

VAL_ 986 UI_phoneGpsAccuracy 127 "SNA";

VAL_ 698 UI_radarTargetDx 255 "NO_OBJECT";
VAL_ 698 UI_radarTargetDxEnd 255 "NO_OBJECT";

VAL_ 632 UI_roadCurvHealth 0 "UNAVAILABLE" 1 "DEGRADED" 2 "AVAILABLE" 3 "DATABASE";

VAL_ 2042 UI_isSunUp 0 "NO_SNA" 1 "YES";
VAL_ 2042 UI_solarAzimuthAngle -1 "SNA";
VAL_ 2042 UI_solarAzimuthAngleCarRef 255 "SNA";
VAL_ 2042 UI_solarElevationAngle 127 "SNA";

VAL_ 12 UI_autopilotTrial 0 "NONE" 1 "START" 2 "STOP" 3 "ACTIVE";
VAL_ 12 UI_cellNetworkTechnology 0 "NONE" 1 "GPRS" 2 "EDGE" 3 "UMTS" 4 "HSDPA" 5 "HSUPA" 6 "HSPA" 7 "LTE" 15 "SNA";
VAL_ 12 UI_cellSignalBars 0 "ZERO" 1 "ONE" 2 "TWO" 3 "THREE" 4 "FOUR" 5 "FIVE" 7 "SNA";
VAL_ 12 UI_factoryReset 0 "NONE_SNA" 1 "DEVELOPER" 2 "DIAGNOSTIC" 3 "CUSTOMER";
VAL_ 12 UI_hardwareType 0 "SNA" 1 "INFO_ONE" 2 "INFO_TWO";
VAL_ 12 UI_monitorModemPower 0 "DISABLE" 1 "ENABLE";
VAL_ 12 UI_readyForDrive 0 "NO_SNA" 1 "YES";
VAL_ 12 UI_tegraAmbientTemperature 255 "SNA";
VAL_ 12 UI_tegraCoreTemperature 255 "SNA";

VAL_ 1352 MCU_alarmAutoOn 0 "No_auto_set_of_alarm" 1 "Set_if_shutdown_and_not_locked";
VAL_ 1352 MCU_configWiperSwitch 0 "low" 1 "medium_low" 2 "medium" 3 "medium_high" 4 "high" 7 "default";
VAL_ 1352 MCU_daytimeRunningLampsOn 0 "off" 1 "on";
VAL_ 1352 MCU_diAckOfPassiveLocking 0 "Off" 1 "On";
VAL_ 1352 MCU_doorMoodLighting 0 "Off" 1 "Low_2" 2 "4" 3 "6" 4 "8" 5 "10" 6 "12" 7 "High_14";
VAL_ 1352 MCU_doorsGlobalUnlockOn 0 "DRIVER_ONLY" 1 "ALL_DOORS";
VAL_ 1352 MCU_entryLightingTimer 0 "Off" 1 "15" 2 "30" 3 "45" 4 "60" 7 "Default";
VAL_ 1352 MCU_exitLightingTimer 0 "Off" 1 "15" 2 "30" 3 "45" 4 "60" 7 "Default";
VAL_ 1352 MCU_footwellMoodLighting 0 "Off" 1 "Low 2" 2 "4" 3 "6" 4 "8" 5 "10" 6 "12" 7 "High 14";
VAL_ 1352 MCU_kl58UserLevelSelected 0 "Off" 1 "Low 2" 2 "4" 3 "6" 4 "8" 5 "10" 6 "12" 7 "High 14";
VAL_ 1352 MCU_mirrorDipOnReverse 0 "Off" 1 "Both" 2 "Passenger only";
VAL_ 1352 MCU_rangeModeOn 0 "OFF" 1 "ON";
VAL_ 1352 MCU_timedWiperModeOn 0 "Auto" 1 "Timed";
VAL_ 1352 MCU_transportModeOn 0 "NORMAL_MODE";
